VERSION "dbc-export 1 2026.26.6.5"

NS_ :

BS_:

BU_: ADSP APSB CMP DAS GTW OCS1P PTC RCM TCU TCU2 UI UIS VCLEFT

BO_ 979 UI_airbagCutoffStatus: 1 UI
 SG_ UI_airbagCutoffSwState : 0|2@1+ (1,0) [0|3] "" Vector__XXX
 SG_ UI_warningIndicatorStatus : 2|2@1+ (1,0) [0|2] "" Vector__XXX

BO_ 1523 UI_alertLog: 8 UI
 SG_ UI_alertID M : 0|9@1+ (1,0) [0|511] "" Vector__XXX
 SG_ UI_alertState : 15|1@1+ (1,0) [0|1] "" Vector__XXX
 SG_ UI_a006_remoteServiceAlertCode m6 : 16|32@1+ (1,0) [0|4294967295] "" Vector__XXX
 SG_ UI_a009_squashfsDevice m9 : 16|4@1+ (1,0) [0|15] "" Vector__XXX
 SG_ UI_a009_squashfsErrorCount m9 : 24|16@1+ (1,0) [0|65535] "" Vector__XXX
 SG_ UI_a034_BackupCamera m34 : 16|1@1+ (1,0) [0|1] "" Vector__XXX
 SG_ UI_a034_Tuner m34 : 17|1@1+ (1,0) [0|1] "" Vector__XXX
 SG_ UI_a034_Bluetooth m34 : 18|1@1+ (1,0) [0|1] "" Vector__XXX
 SG_ UI_a034_WiFi m34 : 19|1@1+ (1,0) [0|1] "" Vector__XXX
 SG_ UI_a034_Cellular m34 : 20|1@1+ (1,0) [0|1] "" Vector__XXX
 SG_ UI_a034_TouchScreen m34 : 21|1@1+ (1,0) [0|1] "" Vector__XXX
 SG_ UI_a034_Display m34 : 22|1@1+ (1,0) [0|1] "" Vector__XXX
 SG_ UI_a034_Audio m34 : 23|1@1+ (1,0) [0|1] "" Vector__XXX
 SG_ UI_a034_FatalWakeup m34 : 24|1@1+ (1,0) [0|1] "" Vector__XXX
 SG_ UI_a034_UnknownWakeupError m34 : 25|1@1+ (1,0) [0|1] "" Vector__XXX
 SG_ UI_a036_audioWatchdogReason m36 : 16|8@1+ (1,0) [0|255] "" Vector__XXX
 SG_ UI_a045_ManualECallDisabled m45 : 16|1@1+ (1,0) [0|1] "" Vector__XXX
 SG_ UI_a045_ManualECallButtonDisconn m45 : 17|1@1+ (1,0) [0|1] "" Vector__XXX
 SG_ UI_a045_CellAntenna m45 : 18|1@1+ (1,0) [0|1] "" Vector__XXX
 SG_ UI_a045_GPSAntenna m45 : 19|1@1+ (1,0) [0|1] "" Vector__XXX
 SG_ UI_a045_ECallSpeaker m45 : 20|1@1+ (1,0) [0|1] "" Vector__XXX
 SG_ UI_a045_ECallMic m45 : 21|1@1+ (1,0) [0|1] "" Vector__XXX
 SG_ UI_a045_SIMTest m45 : 22|1@1+ (1,0) [0|1] "" Vector__XXX
 SG_ UI_a045_ENSTest m45 : 23|1@1+ (1,0) [0|1] "" Vector__XXX
 SG_ UI_a045_CellularTest m45 : 24|1@1+ (1,0) [0|1] "" Vector__XXX
 SG_ UI_a045_ModemFirmwareTest m45 : 25|1@1+ (1,0) [0|1] "" Vector__XXX
 SG_ UI_a052_kernelPanicSignature m52 : 16|32@1+ (1,0) [0|4294967295] "" Vector__XXX
 SG_ UI_a065_wifiRecoveryReason m65 : 16|8@1+ (1,0) [0|255] "" Vector__XXX
 SG_ UI_a066_ProcessId m66 : 16|8@1+ (1,0) [0|255] "" Vector__XXX
 SG_ UI_a066_RingBlitter m66 : 24|1@1+ (1,0) [0|1] "" Vector__XXX
 SG_ UI_a066_RingBSD m66 : 25|1@1+ (1,0) [0|1] "" Vector__XXX
 SG_ UI_a066_RingRender m66 : 26|1@1+ (1,0) [0|1] "" Vector__XXX
 SG_ UI_a066_RingVideoEnhancement m66 : 27|1@1+ (1,0) [0|1] "" Vector__XXX
 SG_ UI_a066_EnginesHung m66 : 28|1@1+ (1,0) [0|1] "" Vector__XXX
 SG_ UI_a066_EnginesWedged m66 : 29|1@1+ (1,0) [0|1] "" Vector__XXX
 SG_ UI_a066_RecoveryFailed m66 : 30|1@1+ (1,0) [0|1] "" Vector__XXX
 SG_ UI_a066_FlipDoneTimedOut m66 : 31|1@1+ (1,0) [0|1] "" Vector__XXX
 SG_ UI_a066_TimedoutSoftRecovered m66 : 32|1@1+ (1,0) [0|1] "" Vector__XXX
 SG_ UI_a087_BmpResetType m87 : 16|3@1+ (1,0) [0|7] "" Vector__XXX
 SG_ UI_a096_PipelineId m96 : 16|8@1+ (1,0) [0|255] "" Vector__XXX
 SG_ UI_a096_UdpTimeout m96 : 24|1@1+ (1,0) [0|1] "" Vector__XXX
 SG_ UI_a096_PipelineWarning m96 : 25|1@1+ (1,0) [0|1] "" Vector__XXX
 SG_ UI_a096_PipelineError m96 : 26|1@1+ (1,0) [0|1] "" Vector__XXX
 SG_ UI_a096_UnexpectedExit m96 : 27|1@1+ (1,0) [0|1] "" Vector__XXX
 SG_ UI_a096_PipelineOverrun m96 : 28|1@1+ (1,0) [0|1] "" Vector__XXX
 SG_ UI_a096_MissingXWindow m96 : 29|1@1+ (1,0) [0|1] "" Vector__XXX
 SG_ UI_a099_emmcStatusRegister m99 : 16|32@1+ (1,0) [0|4294967295] "" Vector__XXX
 SG_ UI_a100_emmcFTLCounter m100 : 16|32@1+ (1,0) [0|4294967295] "" Vector__XXX
 SG_ UI_a131_DisplayPortFailureType m131 : 16|1@1+ (1,0) [0|1] "" Vector__XXX
 SG_ UI_a147_whichASIL m147 : 16|1@1+ (1,0) [0|1] "" Vector__XXX
 SG_ UI_a147_errorCode m147 : 24|8@1+ (1,0) [0|255] "" Vector__XXX
 SG_ UI_a148_sleepType m148 : 16|3@1+ (1,0) [0|7] "" Vector__XXX
 SG_ UI_a148_lastFailedDev m148 : 24|32@1+ (1,0) [0|4294967295] "" Vector__XXX
 SG_ UI_a148_lastFailedPmSuspendDev m148 : 56|5@1+ (1,0) [0|31] "" Vector__XXX
 SG_ UI_a149_displayType m149 : 16|8@1+ (1,0) [0|255] "" Vector__XXX
 SG_ UI_a149_displaySeat m149 : 24|4@1+ (1,0) [0|15] "" Vector__XXX
 SG_ UI_a149_errorCode m149 : 32|32@1+ (1,0) [0|4294967295] "" Vector__XXX
 SG_ UI_a151_cpuAmbientDeltaTemp m151 : 16|16@1+ (1,0) [0|65535] "" Vector__XXX
 SG_ UI_a151_socThermalResistance m151 : 32|16@1+ (1,0) [0|65535] "" Vector__XXX
 SG_ UI_a153_processName m153 : 16|8@1+ (1,0) [0|255] "" Vector__XXX
 SG_ UI_a153_restartReason m153 : 24|8@1+ (1,0) [0|255] "" Vector__XXX
 SG_ UI_a158_UsbDeviceMountErrorCode m158 : 16|32@1+ (1,0) [0|4294967295] "" Vector__XXX
 SG_ UI_a160_WatchdogStarving m160 : 16|1@1+ (1,0) [0|1] "" Vector__XXX
 SG_ UI_a160_MemoryPressureCritical m160 : 17|1@1+ (1,0) [0|1] "" Vector__XXX
 SG_ UI_a160_MemoryUsageCritical m160 : 18|1@1+ (1,0) [0|1] "" Vector__XXX
 SG_ UI_a160_SlabUsageCritical m160 : 19|1@1+ (1,0) [0|1] "" Vector__XXX
 SG_ UI_a165_fsCorruptedDevice m165 : 16|4@1+ (1,0) [0|15] "" Vector__XXX
 SG_ UI_a166_fsErrorDevice m166 : 16|4@1+ (1,0) [0|15] "" Vector__XXX
 SG_ UI_a167_processId m167 : 16|5@1+ (1,0) [0|31] "" Vector__XXX
 SG_ UI_a173_errorCode m173 : 16|2@1+ (1,0) [0|3] "" Vector__XXX
 SG_ UI_a173_hookIndex m173 : 18|4@1+ (1,0) [0|15] "" Vector__XXX
 SG_ UI_a173_lastFailedPmSuspendDev m173 : 24|5@1+ (1,0) [0|31] "" Vector__XXX
 SG_ UI_a176_PrimaryAntenna m176 : 16|3@1+ (1,0) [0|7] "" Vector__XXX
 SG_ UI_a176_SecondaryAntenna m176 : 19|3@1+ (1,0) [0|7] "" Vector__XXX
 SG_ UI_a176_TertiaryAntenna m176 : 24|3@1+ (1,0) [0|7] "" Vector__XXX
 SG_ UI_a177_errorCode m177 : 16|5@1+ (1,0) [0|31] "" Vector__XXX
 SG_ UI_a177_errorSource m177 : 24|6@1+ (1,0) [0|63] "" Vector__XXX
 SG_ UI_a178_irqNumber m178 : 16|16@1+ (1,0) [0|65535] "" Vector__XXX
 SG_ UI_a178_irqSourceId m178 : 32|32@1+ (1,0) [0|4294967295] "" Vector__XXX
 SG_ UI_a192_AudioRebootState m192 : 16|4@1+ (1,0) [0|15] "" Vector__XXX
 SG_ UI_a204_ModemSleepFailureReason m204 : 16|3@1+ (1,0) [0|7] "" Vector__XXX
 SG_ UI_a208_mqttClientDisconnectReas m208 : 16|8@1+ (1,0) [0|255] "" Vector__XXX
 SG_ UI_a214_errorCode m214 : 16|8@1+ (1,0) [0|255] "" Vector__XXX
 SG_ UI_a214_lastFailedDev m214 : 24|32@1+ (1,0) [0|4294967295] "" Vector__XXX
 SG_ UI_a214_lastFailedPmSuspendDev m214 : 56|5@1+ (1,0) [0|31] "" Vector__XXX
 SG_ UI_a216_circuitProblem m216 : 16|8@1+ (1,0) [0|255] "" Vector__XXX
 SG_ UI_a216_circuitNode m216 : 24|8@1+ (1,0) [0|255] "" Vector__XXX
 SG_ UI_a217_cgroupName m217 : 16|5@1+ (1,0) [0|31] "" Vector__XXX
 SG_ UI_a220_errorCode m220 : 16|4@1+ (1,0) [0|15] "" Vector__XXX
 SG_ UI_a221_errorCode m221 : 16|4@1+ (1,0) [0|15] "" Vector__XXX
 SG_ UI_a221_networkErrorCode m221 : 20|9@1+ (1,0) [0|511] "" Vector__XXX
 SG_ UI_a221_serverErrorCode m221 : 32|16@1+ (1,0) [0|65535] "" Vector__XXX
 SG_ UI_a222_errorCode m222 : 16|4@1+ (1,0) [0|15] "" Vector__XXX
 SG_ UI_a223_database m223 : 16|6@1+ (1,0) [0|63] "" Vector__XXX
 SG_ UI_a226_count m226 : 16|16@1+ (1,0) [0|65535] "" Vector__XXX
 SG_ UI_a229_errorCode m229 : 16|8@1+ (1,0) [0|255] "" Vector__XXX
 SG_ UI_a231_sleepType m231 : 16|3@1+ (1,0) [0|7] "" Vector__XXX
 SG_ UI_a232_processExited m232 : 16|8@1+ (1,0) [0|255] "" Vector__XXX
 SG_ UI_a232_processSignal m232 : 24|8@1+ (1,0) [0|255] "" Vector__XXX
 SG_ UI_a240_ethErrorType m240 : 16|8@1+ (1,0) [0|255] "" Vector__XXX
 SG_ UI_a241_errorCode m241 : 16|8@1+ (1,0) [0|255] "" Vector__XXX
 SG_ UI_a242_CenterDispFaultInjected m242 : 16|1@1+ (1,0) [0|1] "" Vector__XXX
 SG_ UI_a242_ConnectivityFaultInjecte m242 : 17|1@1+ (1,0) [0|1] "" Vector__XXX
 SG_ UI_a242_ConnectivityHWFaultInjec m242 : 18|1@1+ (1,0) [0|1] "" Vector__XXX
 SG_ UI_a242_QtCarFaultInjected m242 : 19|1@1+ (1,0) [0|1] "" Vector__XXX
 SG_ UI_a242_RearDispFaultInjected m242 : 20|1@1+ (1,0) [0|1] "" Vector__XXX
 SG_ UI_a242_QtCarRearFaultInjected m242 : 21|1@1+ (1,0) [0|1] "" Vector__XXX
 SG_ UI_a242_DASServerFaultInjected m242 : 22|1@1+ (1,0) [0|1] "" Vector__XXX
 SG_ UI_a242_CenterDispStatusFaultInj m242 : 23|1@1+ (1,0) [0|1] "" Vector__XXX
 SG_ UI_a242_FaultCode m242 : 24|16@1+ (1,0) [0|65535] "" Vector__XXX
 SG_ UI_a247_displayType m247 : 16|8@1+ (1,0) [0|255] "" Vector__XXX
 SG_ UI_a247_displaySeat m247 : 24|4@1+ (1,0) [0|15] "" Vector__XXX
 SG_ UI_a253_correctionCode m253 : 16|48@1+ (1,0) [0|281474976710655] "" Vector__XXX
 SG_ UI_a257_ModemRebootReason m257 : 16|3@1+ (1,0) [0|7] "" Vector__XXX
 SG_ UI_a257_ModemRebootEthPresent m257 : 19|1@1+ (1,0) [0|1] "" Vector__XXX
 SG_ UI_a261_bluetoothStackPanicReaso m261 : 16|6@1+ (1,0) [0|63] "" Vector__XXX
 SG_ UI_a263_hermesUploadFailure m263 : 16|1@1+ (1,0) [0|1] "" Vector__XXX
 SG_ UI_a263_udsUploadFailure m263 : 17|1@1+ (1,0) [0|1] "" Vector__XXX
 SG_ UI_a274_hintCardType m274 : 16|4@1+ (1,0) [0|15] "" Vector__XXX
 SG_ UI_a274_hintCardDismissOutcome m274 : 20|3@1+ (1,0) [0|7] "" Vector__XXX

BO_ 291 UI_alertMatrix1: 8 UI
 SG_ UI_a001_DriverDoorOpen : 0|1@1+ (1,0) [0|1] "" Vector__XXX
 SG_ UI_a002_DoorOpen : 1|1@1+ (1,0) [0|1] "" Vector__XXX
 SG_ UI_a003_TrunkOpen : 2|1@1+ (1,0) [0|1] "" Vector__XXX
 SG_ UI_a004_FrunkOpen : 3|1@1+ (1,0) [0|1] "" Vector__XXX
 SG_ UI_a005_HeadlightsOnDoorOpen : 4|1@1+ (1,0) [0|1] "" Vector__XXX
 SG_ UI_a006_RemoteServiceAlert : 5|1@1+ (1,0) [0|1] "" Vector__XXX
 SG_ UI_a007_SoftPackConfigMismatch : 6|1@1+ (1,0) [0|1] "" Vector__XXX
 SG_ UI_a008_TouchScreenError : 7|1@1+ (1,0) [0|1] "" Vector__XXX
 SG_ UI_a009_SquashfsError : 8|1@1+ (1,0) [0|1] "" Vector__XXX
 SG_ UI_a010_MapsMissing : 9|1@1+ (1,0) [0|1] "" Vector__XXX
 SG_ UI_a011_IncorrectMap : 10|1@1+ (1,0) [0|1] "" Vector__XXX
 SG_ UI_a012_NotOnPrivateProperty : 11|1@1+ (1,0) [0|1] "" Vector__XXX
 SG_ UI_a013_TPMSHardWarning : 12|1@1+ (1,0) [0|1] "" Vector__XXX
 SG_ UI_a014_TPMSSoftWarning : 13|1@1+ (1,0) [0|1] "" Vector__XXX
 SG_ UI_a015_TPMSOverPressureWarning : 14|1@1+ (1,0) [0|1] "" Vector__XXX
 SG_ UI_a016_TPMSTemperatureWarning : 15|1@1+ (1,0) [0|1] "" Vector__XXX
 SG_ UI_a017_TPMSSystemFault : 16|1@1+ (1,0) [0|1] "" Vector__XXX
 SG_ UI_a018_SlipStartOn : 17|1@1+ (1,0) [0|1] "" Vector__XXX
 SG_ UI_a019_ParkBrakeFault : 18|1@1+ (1,0) [0|1] "" Vector__XXX
 SG_ UI_a020_SteeringReduced : 19|1@1+ (1,0) [0|1] "" Vector__XXX
 SG_ UI_a021_RearSeatbeltUnbuckled : 20|1@1+ (1,0) [0|1] "" Vector__XXX
 SG_ UI_a022_ApeFusesEtc : 21|1@1+ (1,0) [0|1] "" Vector__XXX
 SG_ UI_a023_CellInternetCheckFailed : 22|1@1+ (1,0) [0|1] "" Vector__XXX
 SG_ UI_a024_WifiInternetCheckFailed : 23|1@1+ (1,0) [0|1] "" Vector__XXX
 SG_ UI_a026_ModemResetLoopDetected : 25|1@1+ (1,0) [0|1] "" Vector__XXX
 SG_ UI_a027_AutoSteerMIA : 26|1@1+ (1,0) [0|1] "" Vector__XXX
 SG_ UI_a028_FrontTrunkPopupClosed : 27|1@1+ (1,0) [0|1] "" Vector__XXX
 SG_ UI_a029_ModemMIA : 28|1@1+ (1,0) [0|1] "" Vector__XXX
 SG_ UI_a030_ModemVMCrash : 29|1@1+ (1,0) [0|1] "" Vector__XXX
 SG_ UI_a031_BrakeFluidLow : 30|1@1+ (1,0) [0|1] "" Vector__XXX
 SG_ UI_a032_CellModemRecoveryResets : 31|1@1+ (1,0) [0|1] "" Vector__XXX
 SG_ UI_a033_ApTrialExpired : 32|1@1+ (1,0) [0|1] "" Vector__XXX
 SG_ UI_a034_WakeupProblem : 33|1@1+ (1,0) [0|1] "" Vector__XXX
 SG_ UI_a035_FrunkOpenChime : 34|1@1+ (1,0) [0|1] "" Vector__XXX
 SG_ UI_a036_AudioWatchdog : 35|1@1+ (1,0) [0|1] "" Vector__XXX
 SG_ UI_a037_AudioWatchdogXrunStormEr : 36|1@1+ (1,0) [0|1] "" Vector__XXX
 SG_ UI_a038_AudioWatchdogA2bI2cLocku : 37|1@1+ (1,0) [0|1] "" Vector__XXX
 SG_ UI_a039_AudioA2bNeedRediscovery : 38|1@1+ (1,0) [0|1] "" Vector__XXX
 SG_ UI_a040_HomelinkTransmit : 39|1@1+ (1,0) [0|1] "" Vector__XXX
 SG_ UI_a041_AudioDmesgXrun : 40|1@1+ (1,0) [0|1] "" Vector__XXX
 SG_ UI_a042_AudioDmesgRtThrottling : 41|1@1+ (1,0) [0|1] "" Vector__XXX
 SG_ UI_a043_InvalidMapDataOverride : 42|1@1+ (1,0) [0|1] "" Vector__XXX
 SG_ UI_a044_AudioDmesgDspException : 43|1@1+ (1,0) [0|1] "" Vector__XXX
 SG_ UI_a045_ECallSystemCheckFailed : 44|1@1+ (1,0) [0|1] "" Vector__XXX
 SG_ UI_a046_BackupCameraStreamError : 45|1@1+ (1,0) [0|1] "" Vector__XXX
 SG_ UI_a047_CellRoamingDisallowed : 46|1@1+ (1,0) [0|1] "" Vector__XXX
 SG_ UI_a048_AudioPremiumAmpCheckFail : 47|1@1+ (1,0) [0|1] "" Vector__XXX
 SG_ UI_a049_BrakeShiftRequired : 48|1@1+ (1,0) [0|1] "" Vector__XXX
 SG_ UI_a050_BackupCameraIPUTimeout : 49|1@1+ (1,0) [0|1] "" Vector__XXX
 SG_ UI_a051_BackupCameraFrameTimeout : 50|1@1+ (1,0) [0|1] "" Vector__XXX
 SG_ UI_a052_KernelPanicReported : 51|1@1+ (1,0) [0|1] "" Vector__XXX
 SG_ UI_a053_QtCarExitError : 52|1@1+ (1,0) [0|1] "" Vector__XXX
 SG_ UI_a054_AudioBoostPowerBad : 53|1@1+ (1,0) [0|1] "" Vector__XXX
 SG_ UI_a055_ManualECallDisabled : 54|1@1+ (1,0) [0|1] "" Vector__XXX
 SG_ UI_a056_ManualECallButtonDisconn : 55|1@1+ (1,0) [0|1] "" Vector__XXX
 SG_ UI_a057_CellAntennaDisconnected : 56|1@1+ (1,0) [0|1] "" Vector__XXX
 SG_ UI_a058_GPSAntennaDisconnected : 57|1@1+ (1,0) [0|1] "" Vector__XXX
 SG_ UI_a059_ECallSpeakerDisconnected : 58|1@1+ (1,0) [0|1] "" Vector__XXX
 SG_ UI_a060_ECallMicDisconnected : 59|1@1+ (1,0) [0|1] "" Vector__XXX
 SG_ UI_a061_SIMTestFailed : 60|1@1+ (1,0) [0|1] "" Vector__XXX
 SG_ UI_a062_ENSTestFailed : 61|1@1+ (1,0) [0|1] "" Vector__XXX
 SG_ UI_a063_CellularTestFailed : 62|1@1+ (1,0) [0|1] "" Vector__XXX
 SG_ UI_a064_ModemFirmwareTestFailed : 63|1@1+ (1,0) [0|1] "" Vector__XXX

BO_ 292 UI_alertMatrix2: 8 UI
 SG_ UI_a065_WiFiRecoveryReset : 0|1@1+ (1,0) [0|1] "" Vector__XXX
 SG_ UI_a066_GpuHangDetected : 1|1@1+ (1,0) [0|1] "" Vector__XXX
 SG_ UI_a067_WarnOnI915 : 2|1@1+ (1,0) [0|1] "" Vector__XXX
 SG_ UI_a068_VideoUnexpectedExit : 3|1@1+ (1,0) [0|1] "" Vector__XXX
 SG_ UI_a069_VideoUDPTimeout : 4|1@1+ (1,0) [0|1] "" Vector__XXX
 SG_ UI_a070_VideoPipelineWarning : 5|1@1+ (1,0) [0|1] "" Vector__XXX
 SG_ UI_a071_VideoPipelineError : 6|1@1+ (1,0) [0|1] "" Vector__XXX
 SG_ UI_a072_ECallAnalogMicFailed : 7|1@1+ (1,0) [0|1] "" Vector__XXX
 SG_ UI_a073_ECallDigitalMicFailed : 8|1@1+ (1,0) [0|1] "" Vector__XXX
 SG_ UI_a074_EMMCHangDetected : 9|1@1+ (1,0) [0|1] "" Vector__XXX
 SG_ UI_a075_BackupCameraInitError : 10|1@1+ (1,0) [0|1] "" Vector__XXX
 SG_ UI_a076_NumFalseManualECalls : 11|1@1+ (1,0) [0|1] "" Vector__XXX
 SG_ UI_a077_AudioA2bMicChannelSwap : 12|1@1+ (1,0) [0|1] "" Vector__XXX
 SG_ UI_a078_DashcamUsbDriveUnmountab : 13|1@1+ (1,0) [0|1] "" Vector__XXX
 SG_ UI_a079_DashcamUsbDriveFull : 14|1@1+ (1,0) [0|1] "" Vector__XXX
 SG_ UI_a080_DashcamUsbDriveSlow : 15|1@1+ (1,0) [0|1] "" Vector__XXX
 SG_ UI_a081_CellModemSearchExpired : 16|1@1+ (1,0) [0|1] "" Vector__XXX
 SG_ UI_a082_NumModemRebootStuckInECa : 17|1@1+ (1,0) [0|1] "" Vector__XXX
 SG_ UI_a083_ECallProxyWatchdogTrigge : 18|1@1+ (1,0) [0|1] "" Vector__XXX
 SG_ UI_a084_SerializerError : 19|1@1+ (1,0) [0|1] "" Vector__XXX
 SG_ UI_a085_DeserializerError : 20|1@1+ (1,0) [0|1] "" Vector__XXX
 SG_ UI_a086_TouchEnumerationError : 21|1@1+ (1,0) [0|1] "" Vector__XXX
 SG_ UI_a087_BmpReset : 22|1@1+ (1,0) [0|1] "" Vector__XXX
 SG_ UI_a088_CellRemovableSimMissing : 23|1@1+ (1,0) [0|1] "" Vector__XXX
 SG_ UI_a089_RadioReset : 24|1@1+ (1,0) [0|1] "" Vector__XXX
 SG_ UI_a090_RadioPingFailError : 25|1@1+ (1,0) [0|1] "" Vector__XXX
 SG_ UI_a091_VehicleLinkStall : 26|1@1+ (1,0) [0|1] "" Vector__XXX
 SG_ UI_a092_updateStarted : 27|1@1+ (1,0) [0|1] "" Vector__XXX
 SG_ UI_a093_updateEnded : 28|1@1+ (1,0) [0|1] "" Vector__XXX
 SG_ UI_a094_ModemPowerOnFailure : 29|1@1+ (1,0) [0|1] "" Vector__XXX
 SG_ UI_a095_CidStorageRunningLow : 30|1@1+ (1,0) [0|1] "" Vector__XXX
 SG_ UI_a096_VideodPipelineIssueDetec : 31|1@1+ (1,0) [0|1] "" Vector__XXX
 SG_ UI_a097_AudiodRestarted : 32|1@1+ (1,0) [0|1] "" Vector__XXX
 SG_ UI_a098_DiskCheckFailure : 33|1@1+ (1,0) [0|1] "" Vector__XXX
 SG_ UI_a099_eMMCStatusError : 34|1@1+ (1,0) [0|1] "" Vector__XXX
 SG_ UI_a100_eMMCFTLError : 35|1@1+ (1,0) [0|1] "" Vector__XXX
 SG_ UI_a101_wifiStackProblem : 36|1@1+ (1,0) [0|1] "" Vector__XXX
 SG_ UI_a102_A2bDiscoveryFailed : 37|1@1+ (1,0) [0|1] "" Vector__XXX
 SG_ UI_a103_UsbHubNotEnumerating : 38|1@1+ (1,0) [0|1] "" Vector__XXX
 SG_ UI_a104_DashcamUsbDriveMissing : 39|1@1+ (1,0) [0|1] "" Vector__XXX
 SG_ UI_a105_firmwareReinstallRequest : 40|1@1+ (1,0) [0|1] "" Vector__XXX
 SG_ UI_a106_rebootBackstopTriggered : 41|1@1+ (1,0) [0|1] "" Vector__XXX
 SG_ UI_a107_DashcamUsbDriveTooBigFor : 42|1@1+ (1,0) [0|1] "" Vector__XXX
 SG_ UI_a108_DashcamUsbDriveGettingFu : 43|1@1+ (1,0) [0|1] "" Vector__XXX
 SG_ UI_a109_DashcamUsbDriveTooSmall : 44|1@1+ (1,0) [0|1] "" Vector__XXX
 SG_ UI_a110_DashcamUsbDriveCorrupt : 45|1@1+ (1,0) [0|1] "" Vector__XXX
 SG_ UI_a111_DashcamUsbDriveNotSuperS : 46|1@1+ (1,0) [0|1] "" Vector__XXX
 SG_ UI_a112_badUSBDevice : 47|1@1+ (1,0) [0|1] "" Vector__XXX
 SG_ UI_a113_DashcamHasOnboardSentryC : 48|1@1+ (1,0) [0|1] "" Vector__XXX
 SG_ UI_a114_drivingVisualizationDegr : 49|1@1+ (1,0) [0|1] "" Vector__XXX
 SG_ UI_a115_IrisEDLMode : 50|1@1+ (1,0) [0|1] "" Vector__XXX
 SG_ UI_a116_UncorrectableMemoryError : 51|1@1+ (1,0) [0|1] "" Vector__XXX
 SG_ UI_a117_VehicleSelfTestRunning : 52|1@1+ (1,0) [0|1] "" Vector__XXX
 SG_ UI_a118_NVMeReset : 53|1@1+ (1,0) [0|1] "" Vector__XXX
 SG_ UI_a119_nvmeBlockDeviceMissing : 54|1@1+ (1,0) [0|1] "" Vector__XXX
 SG_ UI_a120_nvmePCIeLinkErrorDetecte : 55|1@1+ (1,0) [0|1] "" Vector__XXX
 SG_ UI_a121_nvmeSmartLogCritical : 56|1@1+ (1,0) [0|1] "" Vector__XXX
 SG_ UI_a122_AMDI2C0LostArbitration : 57|1@1+ (1,0) [0|1] "" Vector__XXX
 SG_ UI_a123_AMDI2C1LostArbitration : 58|1@1+ (1,0) [0|1] "" Vector__XXX
 SG_ UI_a124_AMDI2C0TxRxAborted : 59|1@1+ (1,0) [0|1] "" Vector__XXX
 SG_ UI_a125_AMDI2C1TxRxAborted : 60|1@1+ (1,0) [0|1] "" Vector__XXX
 SG_ UI_a126_UsbErrorDriveCorrupt : 61|1@1+ (1,0) [0|1] "" Vector__XXX
 SG_ UI_a128_dgpuNotDetected : 63|1@1+ (1,0) [0|1] "" Vector__XXX

BO_ 293 UI_alertMatrix3: 8 UI
 SG_ UI_a129_dgpuOperationFailure : 0|1@1+ (1,0) [0|1] "" Vector__XXX
 SG_ UI_a130_QtCarClusterExitError : 1|1@1+ (1,0) [0|1] "" Vector__XXX
 SG_ UI_a131_DisplayPortFailure : 2|1@1+ (1,0) [0|1] "" Vector__XXX
 SG_ UI_a132_AdspWatchdogRecoveryTrig : 3|1@1+ (1,0) [0|1] "" Vector__XXX
 SG_ UI_a133_AdspWatchdogRecoveryFail : 4|1@1+ (1,0) [0|1] "" Vector__XXX
 SG_ UI_a134_DashcamUsbDriveNoMedium : 5|1@1+ (1,0) [0|1] "" Vector__XXX
 SG_ UI_a135_warnRunOverlayExists : 6|1@1+ (1,0) [0|1] "" Vector__XXX
 SG_ UI_a136_warnSettingsConfExists : 7|1@1+ (1,0) [0|1] "" Vector__XXX
 SG_ UI_a137_ServiceShellActiveConnec : 8|1@1+ (1,0) [0|1] "" Vector__XXX
 SG_ UI_a138_applyingConfigChange : 9|1@1+ (1,0) [0|1] "" Vector__XXX
 SG_ UI_a139_postponedConfigChange : 10|1@1+ (1,0) [0|1] "" Vector__XXX
 SG_ UI_a140_NeverSleepActive : 11|1@1+ (1,0) [0|1] "" Vector__XXX
 SG_ UI_a141_falconDoorOpen : 12|1@1+ (1,0) [0|1] "" Vector__XXX
 SG_ UI_a142_CorrectableMemoryError : 13|1@1+ (1,0) [0|1] "" Vector__XXX
 SG_ UI_a143_FPSCrawling : 14|1@1+ (1,0) [0|1] "" Vector__XXX
 SG_ UI_a144_nvmeWarning : 15|1@1+ (1,0) [0|1] "" Vector__XXX
 SG_ UI_a145_nvmeUnsafeShutdown : 16|1@1+ (1,0) [0|1] "" Vector__XXX
 SG_ UI_a146_nvmeNeedsReplacement : 17|1@1+ (1,0) [0|1] "" Vector__XXX
 SG_ UI_a147_ASILGlobalError : 18|1@1+ (1,0) [0|1] "" Vector__XXX
 SG_ UI_a148_SleepFailure : 19|1@1+ (1,0) [0|1] "" Vector__XXX
 SG_ UI_a149_DisplayCheckFailure : 20|1@1+ (1,0) [0|1] "" Vector__XXX
 SG_ UI_a150_infoCPURunningHot : 21|1@1+ (1,0) [0|1] "" Vector__XXX
 SG_ UI_a151_carComputerThermalProble : 22|1@1+ (1,0) [0|1] "" Vector__XXX
 SG_ UI_a152_infoThrottling : 23|1@1+ (1,0) [0|1] "" Vector__XXX
 SG_ UI_a153_serviceRestarted : 24|1@1+ (1,0) [0|1] "" Vector__XXX
 SG_ UI_a154_AudiodBufferError : 25|1@1+ (1,0) [0|1] "" Vector__XXX
 SG_ UI_a155_UsbFrontHubUnavailable : 26|1@1+ (1,0) [0|1] "" Vector__XXX
 SG_ UI_a156_UsbFrontHubInstallMismat : 27|1@1+ (1,0) [0|1] "" Vector__XXX
 SG_ UI_a157_MCUActiveCoolingRequeste : 28|1@1+ (1,0) [0|1] "" Vector__XXX
 SG_ UI_a158_UsbDeviceMountError : 29|1@1+ (1,0) [0|1] "" Vector__XXX
 SG_ UI_a159_AudioHeartbeatFailure : 30|1@1+ (1,0) [0|1] "" Vector__XXX
 SG_ UI_a160_SystemWatchdogFailure : 31|1@1+ (1,0) [0|1] "" Vector__XXX
 SG_ UI_a161_ECallTemporarilyUnavaila : 32|1@1+ (1,0) [0|1] "" Vector__XXX
 SG_ UI_a162_voiceRecClipsUploaded : 33|1@1+ (1,0) [0|1] "" Vector__XXX
 SG_ UI_a163_QtCarVehicleExitError : 34|1@1+ (1,0) [0|1] "" Vector__XXX
 SG_ UI_a164_AudiodConnTimeout : 35|1@1+ (1,0) [0|1] "" Vector__XXX
 SG_ UI_a165_fsCorrupted : 36|1@1+ (1,0) [0|1] "" Vector__XXX
 SG_ UI_a166_fsError : 37|1@1+ (1,0) [0|1] "" Vector__XXX
 SG_ UI_a167_CgroupOverMemKill : 38|1@1+ (1,0) [0|1] "" Vector__XXX
 SG_ UI_a168_dgpuPowerOnSelfTestFailu : 39|1@1+ (1,0) [0|1] "" Vector__XXX
 SG_ UI_a169_SteamLoadShedFailure : 40|1@1+ (1,0) [0|1] "" Vector__XXX
 SG_ UI_a170_AMDdGPULoadShedFailure : 41|1@1+ (1,0) [0|1] "" Vector__XXX
 SG_ UI_a171_GraphicsLoadShedRequeste : 42|1@1+ (1,0) [0|1] "" Vector__XXX
 SG_ UI_a172_GraphicsLoadShedUIFailur : 43|1@1+ (1,0) [0|1] "" Vector__XXX
 SG_ UI_a173_pmSuspendFailure : 44|1@1+ (1,0) [0|1] "" Vector__XXX
 SG_ UI_a174_HistorySaveLoop : 45|1@1+ (1,0) [0|1] "" Vector__XXX
 SG_ UI_a176_CellularAntennaAlert : 47|1@1+ (1,0) [0|1] "" Vector__XXX
 SG_ UI_a177_MediaPlayerFailure : 48|1@1+ (1,0) [0|1] "" Vector__XXX
 SG_ UI_a178_irqDisabled : 49|1@1+ (1,0) [0|1] "" Vector__XXX
 SG_ UI_a180_AudiodInputRestarted : 51|1@1+ (1,0) [0|1] "" Vector__XXX
 SG_ UI_a181_ModemFirmwareVersionMism : 52|1@1+ (1,0) [0|1] "" Vector__XXX
 SG_ UI_a182_VideoPipelineOverrun : 53|1@1+ (1,0) [0|1] "" Vector__XXX
 SG_ UI_a183_DDAWFaulted : 54|1@1+ (1,0) [0|1] "" Vector__XXX
 SG_ UI_a184_ISAFaulted : 55|1@1+ (1,0) [0|1] "" Vector__XXX
 SG_ UI_a185_ELKSDisabled : 56|1@1+ (1,0) [0|1] "" Vector__XXX
 SG_ UI_a186_ELKSUnavailable : 57|1@1+ (1,0) [0|1] "" Vector__XXX
 SG_ UI_a187_TunerFirmwareMismatchedV : 58|1@1+ (1,0) [0|1] "" Vector__XXX
 SG_ UI_a188_TunerFirmwareMismatchedA : 59|1@1+ (1,0) [0|1] "" Vector__XXX
 SG_ UI_a189_TunerWatchdogReset : 60|1@1+ (1,0) [0|1] "" Vector__XXX
 SG_ UI_a190_TunerMIA : 61|1@1+ (1,0) [0|1] "" Vector__XXX
 SG_ UI_a191_TunerUpdateFailed : 62|1@1+ (1,0) [0|1] "" Vector__XXX
 SG_ UI_a192_AudioWatchdogReboot : 63|1@1+ (1,0) [0|1] "" Vector__XXX

BO_ 294 UI_alertMatrix4: 8 UI
 SG_ UI_a193_TcuRNandFwVersionMismatc : 0|1@1+ (1,0) [0|1] "" Vector__XXX
 SG_ UI_a194_AudioweaverRestarted : 1|1@1+ (1,0) [0|1] "" Vector__XXX
 SG_ UI_a195_gtwMfdUdpApiFired : 2|1@1+ (1,0) [0|1] "" Vector__XXX
 SG_ UI_a196_AMDI2C3BusInoperable : 3|1@1+ (1,0) [0|1] "" Vector__XXX
 SG_ UI_a197_AMDI2C1BusInoperable : 4|1@1+ (1,0) [0|1] "" Vector__XXX
 SG_ UI_a198_IncompatibleBTUSBHubHard : 5|1@1+ (1,0) [0|1] "" Vector__XXX
 SG_ UI_a199_HighAPedalDetectedAtColl : 6|1@1+ (1,0) [0|1] "" Vector__XXX
 SG_ UI_a200_UIFirmwareVersionMismatc : 7|1@1+ (1,0) [0|1] "" Vector__XXX
 SG_ UI_a201_rearDisplayDisconnected : 8|1@1+ (1,0) [0|1] "" Vector__XXX
 SG_ UI_a202_sysMemoryIncorrect : 9|1@1+ (1,0) [0|1] "" Vector__XXX
 SG_ UI_a204_ModemSleepFailure : 11|1@1+ (1,0) [0|1] "" Vector__XXX
 SG_ UI_a205_ModemSleepSignalMismatch : 12|1@1+ (1,0) [0|1] "" Vector__XXX
 SG_ UI_a206_ModemMIAAfterWake : 13|1@1+ (1,0) [0|1] "" Vector__XXX
 SG_ UI_a208_mqttClientDisconnected : 15|1@1+ (1,0) [0|1] "" Vector__XXX
 SG_ UI_a209_dataCallDisconnected : 16|1@1+ (1,0) [0|1] "" Vector__XXX
 SG_ UI_a210_CellularCSRegFail : 17|1@1+ (1,0) [0|1] "" Vector__XXX
 SG_ UI_a211_AEBSDisabled : 18|1@1+ (1,0) [0|1] "" Vector__XXX
 SG_ UI_a212_AEBSFaulted : 19|1@1+ (1,0) [0|1] "" Vector__XXX
 SG_ UI_a213_ISADisabled : 20|1@1+ (1,0) [0|1] "" Vector__XXX
 SG_ UI_a214_pmHelperFailure : 21|1@1+ (1,0) [0|1] "" Vector__XXX
 SG_ UI_a215_compositorStallDetected : 22|1@1+ (1,0) [0|1] "" Vector__XXX
 SG_ UI_a216_AudioA2bCircuitProblem : 23|1@1+ (1,0) [0|1] "" Vector__XXX
 SG_ UI_a217_CgroupMemoryPressure : 24|1@1+ (1,0) [0|1] "" Vector__XXX
 SG_ UI_a218_AudiodNoAudioDevices : 25|1@1+ (1,0) [0|1] "" Vector__XXX
 SG_ UI_a219_CompositorWatchdog : 26|1@1+ (1,0) [0|1] "" Vector__XXX
 SG_ UI_a220_MediaBrowseError : 27|1@1+ (1,0) [0|1] "" Vector__XXX
 SG_ UI_a221_NavigationServiceError : 28|1@1+ (1,0) [0|1] "" Vector__XXX
 SG_ UI_a222_QtCarRestart : 29|1@1+ (1,0) [0|1] "" Vector__XXX
 SG_ UI_a223_databaseError : 30|1@1+ (1,0) [0|1] "" Vector__XXX
 SG_ UI_a224_centerDisplayDisconnecte : 31|1@1+ (1,0) [0|1] "" Vector__XXX
 SG_ UI_a225_clusterDisplayDisconnect : 32|1@1+ (1,0) [0|1] "" Vector__XXX
 SG_ UI_a226_largePhoneContactSync : 33|1@1+ (1,0) [0|1] "" Vector__XXX
 SG_ UI_a228_pipewireXrunBurst : 35|1@1+ (1,0) [0|1] "" Vector__XXX
 SG_ UI_a229_SerDesError : 36|1@1+ (1,0) [0|1] "" Vector__XXX
 SG_ UI_a230_ModemSimCardMismatch : 37|1@1+ (1,0) [0|1] "" Vector__XXX
 SG_ UI_a231_SleepCancelled : 38|1@1+ (1,0) [0|1] "" Vector__XXX
 SG_ UI_a232_processExitError : 39|1@1+ (1,0) [0|1] "" Vector__XXX
 SG_ UI_a233_ModemRFFailure : 40|1@1+ (1,0) [0|1] "" Vector__XXX
 SG_ UI_a234_AMDI2C0Timeout : 41|1@1+ (1,0) [0|1] "" Vector__XXX
 SG_ UI_a235_AMDI2C1Timeout : 42|1@1+ (1,0) [0|1] "" Vector__XXX
 SG_ UI_a236_ModemOnResetState : 43|1@1+ (1,0) [0|1] "" Vector__XXX
 SG_ UI_a237_ClipUploadActive : 44|1@1+ (1,0) [0|1] "" Vector__XXX
 SG_ UI_a238_ModemConfigMismatch : 45|1@1+ (1,0) [0|1] "" Vector__XXX
 SG_ UI_a240_ethError : 47|1@1+ (1,0) [0|1] "" Vector__XXX
 SG_ UI_a241_AxCPError : 48|1@1+ (1,0) [0|1] "" Vector__XXX
 SG_ UI_a242_uiHealthFaultInjectionAc : 49|1@1+ (1,0) [0|1] "" Vector__XXX
 SG_ UI_a243_pmDisplayCheckFailure : 50|1@1+ (1,0) [0|1] "" Vector__XXX
 SG_ UI_a244_segfault : 51|1@1+ (1,0) [0|1] "" Vector__XXX
 SG_ UI_a245_taskHung : 52|1@1+ (1,0) [0|1] "" Vector__XXX
 SG_ UI_a246_gpuFenceTimeout : 53|1@1+ (1,0) [0|1] "" Vector__XXX
 SG_ UI_a247_StalklessDisplayBackligh : 54|1@1+ (1,0) [0|1] "" Vector__XXX
 SG_ UI_a252_TPMErrorReceive : 59|1@1+ (1,0) [0|1] "" Vector__XXX
 SG_ UI_a253_maintenanceHistoryRecord : 60|1@1+ (1,0) [0|1] "" Vector__XXX
 SG_ UI_a254_appCertificateExpired : 61|1@1+ (1,0) [0|1] "" Vector__XXX
 SG_ UI_a255_apbCertificateExpired : 62|1@1+ (1,0) [0|1] "" Vector__XXX
 SG_ UI_a256_sapFailedToEnable : 63|1@1+ (1,0) [0|1] "" Vector__XXX

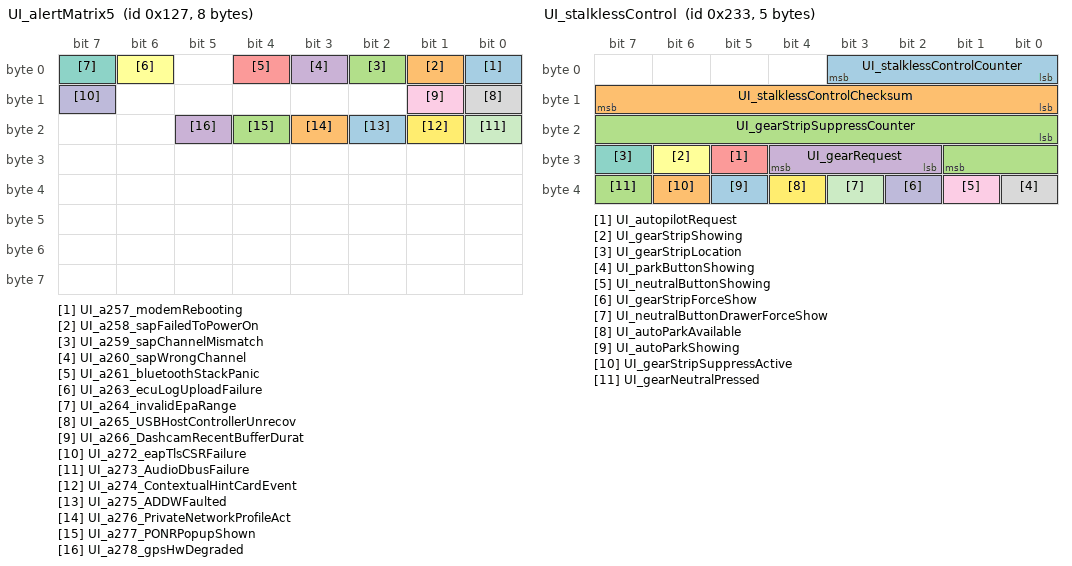
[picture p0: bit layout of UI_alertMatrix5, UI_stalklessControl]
BO_ 295 UI_alertMatrix5: 8 UI
 SG_ UI_a257_modemRebooting : 0|1@1+ (1,0) [0|1] "" Vector__XXX
 SG_ UI_a258_sapFailedToPowerOn : 1|1@1+ (1,0) [0|1] "" Vector__XXX
 SG_ UI_a259_sapChannelMismatch : 2|1@1+ (1,0) [0|1] "" Vector__XXX
 SG_ UI_a260_sapWrongChannel : 3|1@1+ (1,0) [0|1] "" Vector__XXX
 SG_ UI_a261_bluetoothStackPanic : 4|1@1+ (1,0) [0|1] "" Vector__XXX
 SG_ UI_a263_ecuLogUploadFailure : 6|1@1+ (1,0) [0|1] "" Vector__XXX
 SG_ UI_a264_invalidEpaRange : 7|1@1+ (1,0) [0|1] "" Vector__XXX
 SG_ UI_a265_USBHostControllerUnrecov : 8|1@1+ (1,0) [0|1] "" Vector__XXX
 SG_ UI_a266_DashcamRecentBufferDurat : 9|1@1+ (1,0) [0|1] "" Vector__XXX
 SG_ UI_a272_eapTlsCSRFailure : 15|1@1+ (1,0) [0|1] "" Vector__XXX
 SG_ UI_a273_AudioDbusFailure : 16|1@1+ (1,0) [0|1] "" Vector__XXX
 SG_ UI_a274_ContextualHintCardEvent : 17|1@1+ (1,0) [0|1] "" Vector__XXX
 SG_ UI_a275_ADDWFaulted : 18|1@1+ (1,0) [0|1] "" Vector__XXX
 SG_ UI_a276_PrivateNetworkProfileAct : 19|1@1+ (1,0) [0|1] "" Vector__XXX
 SG_ UI_a277_PONRPopupShown : 20|1@1+ (1,0) [0|1] "" Vector__XXX
 SG_ UI_a278_gpsHwDegraded : 21|1@1+ (1,0) [0|1] "" Vector__XXX

BO_ 1279 UI_energyConsumptionInfo: 8 UI
 SG_ UI_energyConsumptionInfoIndex M : 0|5@1+ (1,0) [0|31] "" Vector__XXX
 SG_ UI_energyLossTotal_epa m0 : 16|16@1- (1,0) [-32768|32767] "Wh" Vector__XXX
 SG_ UI_energyLossDriving_epa m0 : 32|16@1- (1,0) [-32768|32767] "Wh" Vector__XXX
 SG_ UI_energyLossClimate_epa m0 : 48|16@1- (1,0) [-32768|32767] "Wh" Vector__XXX
 SG_ UI_energyLossBattCond_epa m1 : 16|16@1- (1,0) [-32768|32767] "Wh" Vector__XXX
 SG_ UI_energyLossElevation_epa m1 : 32|16@1- (1,0) [-32768|32767] "Wh" Vector__XXX
 SG_ UI_energyLossAcc_epa m1 : 48|16@1- (1,0) [-32768|32767] "Wh" Vector__XXX
 SG_ UI_energyLossTotalSinceCharge_ep m2 : 16|16@1- (1,0) [-32768|32767] "Wh" Vector__XXX
 SG_ UI_energyLossDrivingSinceCharge_ m2 : 32|16@1- (1,0) [-32768|32767] "Wh" Vector__XXX
 SG_ UI_energyLossClimateSinceCharge_ m2 : 48|16@1- (1,0) [-32768|32767] "Wh" Vector__XXX
 SG_ UI_energyLossBattCondSinceCharge m3 : 16|16@1- (1,0) [-32768|32767] "Wh" Vector__XXX
 SG_ UI_energyLossElevationSinceCharg m3 : 32|16@1- (1,0) [-32768|32767] "Wh" Vector__XXX
 SG_ UI_energyLossAccSinceCharge_epa m3 : 48|16@1- (1,0) [-32768|32767] "Wh" Vector__XXX
 SG_ UI_energyLossTotalSinceTripStart m4 : 16|16@1- (1,0) [-32768|32767] "Wh" Vector__XXX
 SG_ UI_energyLossDrivingSinceTripSta m4 : 32|16@1- (1,0) [-32768|32767] "Wh" Vector__XXX
 SG_ UI_energyLossClimateSinceTripSta m4 : 48|16@1- (1,0) [-32768|32767] "Wh" Vector__XXX
 SG_ UI_energyLossBattCondSinceTripSt m5 : 16|16@1- (1,0) [-32768|32767] "Wh" Vector__XXX
 SG_ UI_energyLossElevationSinceTripS m5 : 32|16@1- (1,0) [-32768|32767] "Wh" Vector__XXX
 SG_ UI_energyLossAccSinceTripStart m5 : 48|16@1- (1,0) [-32768|32767] "Wh" Vector__XXX
 SG_ UI_energyDeltaTotal_epa m6 : 16|16@1- (1,0) [-32768|32767] "Wh" Vector__XXX
 SG_ UI_energyDeltaDriving_epa m6 : 32|16@1- (1,0) [-32768|32767] "Wh" Vector__XXX
 SG_ UI_energyDeltaClimate_epa m6 : 48|16@1- (1,0) [-32768|32767] "Wh" Vector__XXX
 SG_ UI_energyDeltaBattCond_epa m7 : 16|16@1- (1,0) [-32768|32767] "Wh" Vector__XXX
 SG_ UI_energyDeltaElevation_epa m7 : 32|16@1- (1,0) [-32768|32767] "Wh" Vector__XXX
 SG_ UI_energyDeltaAcc_epa m7 : 48|16@1- (1,0) [-32768|32767] "Wh" Vector__XXX
 SG_ UI_uiDeltaOffsetTotal_epa m8 : 16|16@1- (1,0) [-32768|32767] "Wh" Vector__XXX
 SG_ UI_uiDeltaOffsetDriving_epa m8 : 32|16@1- (1,0) [-32768|32767] "Wh" Vector__XXX
 SG_ UI_uiDeltaOffsetClimate_epa m8 : 48|16@1- (1,0) [-32768|32767] "Wh" Vector__XXX
 SG_ UI_uiDeltaOffsetBattCond_epa m9 : 16|16@1- (1,0) [-32768|32767] "Wh" Vector__XXX
 SG_ UI_uiDeltaOffsetElevation_epa m9 : 32|16@1- (1,0) [-32768|32767] "Wh" Vector__XXX
 SG_ UI_uiDeltaOffsetAcc_epa m9 : 48|16@1- (1,0) [-32768|32767] "Wh" Vector__XXX
 SG_ UI_rawToUiEnergyRatio_epa m10 : 8|8@1+ (0.01,0) [0|2.55] "-" Vector__XXX
 SG_ UI_driveDistance_epa m10 : 16|16@1+ (0.01,0) [0|655.35] "miles" Vector__XXX
 SG_ UI_energyDeltaTotalSinceCharge_e m11 : 16|16@1- (1,0) [-32768|32767] "Wh" Vector__XXX
 SG_ UI_energyDeltaDrivingSinceCharge m11 : 32|16@1- (1,0) [-32768|32767] "Wh" Vector__XXX
 SG_ UI_energyDeltaClimateSinceCharge m11 : 48|16@1- (1,0) [-32768|32767] "Wh" Vector__XXX
 SG_ UI_energyDeltaBattCondSinceCharg m12 : 16|16@1- (1,0) [-32768|32767] "Wh" Vector__XXX
 SG_ UI_energyDeltaElevationSinceChar m12 : 32|16@1- (1,0) [-32768|32767] "Wh" Vector__XXX
 SG_ UI_energyDeltaAccSinceCharge_epa m12 : 48|16@1- (1,0) [-32768|32767] "Wh" Vector__XXX
 SG_ UI_uiDeltaOffsetTotalSinceCharge m13 : 16|16@1- (1,0) [-32768|32767] "Wh" Vector__XXX
 SG_ UI_uiDeltaOffsetDrivingSinceChar m13 : 32|16@1- (1,0) [-32768|32767] "Wh" Vector__XXX
 SG_ UI_uiDeltaOffsetClimateSinceChar m13 : 48|16@1- (1,0) [-32768|32767] "Wh" Vector__XXX
 SG_ UI_uiDeltaOffsetBattCondSinceCha m14 : 16|16@1- (1,0) [-32768|32767] "Wh" Vector__XXX
 SG_ UI_uiDeltaOffsetElevationSinceCh m14 : 32|16@1- (1,0) [-32768|32767] "Wh" Vector__XXX
 SG_ UI_uiDeltaOffsetAccSinceCharge_e m14 : 48|16@1- (1,0) [-32768|32767] "Wh" Vector__XXX
 SG_ UI_rawToUiEnergyRatioSinceCharge m15 : 8|8@1+ (0.01,0) [0|2.55] "-" Vector__XXX
 SG_ UI_driveDistanceSinceCharge_epa m15 : 16|16@1+ (0.01,0) [0|655.35] "miles" Vector__XXX
 SG_ UI_energyDeltaTotalSinceTripStar m16 : 16|16@1- (1,0) [-32768|32767] "Wh" Vector__XXX
 SG_ UI_energyDeltaDrivingSinceTripSt m16 : 32|16@1- (1,0) [-32768|32767] "Wh" Vector__XXX
 SG_ UI_energyDeltaClimateSinceTripSt m16 : 48|16@1- (1,0) [-32768|32767] "Wh" Vector__XXX
 SG_ UI_energyDeltaBattCondSinceTripS m17 : 16|16@1- (1,0) [-32768|32767] "Wh" Vector__XXX
 SG_ UI_energyDeltaElevationSinceTrip m17 : 32|16@1- (1,0) [-32768|32767] "Wh" Vector__XXX
 SG_ UI_energyDeltaAccSinceTripStart m17 : 48|16@1- (1,0) [-32768|32767] "Wh" Vector__XXX
 SG_ UI_uiDeltaOffsetTotalSinceTripSt m18 : 16|16@1- (1,0) [-32768|32767] "Wh" Vector__XXX
 SG_ UI_uiDeltaOffsetDrivingSinceTrip m18 : 32|16@1- (1,0) [-32768|32767] "Wh" Vector__XXX
 SG_ UI_uiDeltaOffsetClimateSinceTrip m18 : 48|16@1- (1,0) [-32768|32767] "Wh" Vector__XXX
 SG_ UI_uiDeltaOffsetBattCondSinceTri m19 : 16|16@1- (1,0) [-32768|32767] "Wh" Vector__XXX
 SG_ UI_uiDeltaOffsetElevationSinceTr m19 : 32|16@1- (1,0) [-32768|32767] "Wh" Vector__XXX
 SG_ UI_uiDeltaOffsetAccSinceTripStar m19 : 48|16@1- (1,0) [-32768|32767] "Wh" Vector__XXX
 SG_ UI_rawToUiEnergyRatioSinceTripSt m20 : 8|8@1+ (0.01,0) [0|2.55] "-" Vector__XXX
 SG_ UI_driveDistanceSinceTripStart m20 : 16|16@1+ (0.01,0) [0|655.35] "miles" Vector__XXX
 SG_ UI_voyagerEnabled m21 : 5|1@1+ (1,0) [0|1] "" Vector__XXX
 SG_ UI_trailerMass m21 : 16|16@1+ (1,0) [0|65535] "kg" Vector__XXX

BO_ 993 UI_gearSliderInfo: 8 UI
 SG_ UI_gearSliderInfoIndex M : 0|2@1+ (1,0) [0|3] "" Vector__XXX
 SG_ UI_gearSliderW m0 : 2|14@1+ (1,0) [0|16383] "" Vector__XXX
 SG_ UI_gearSliderH m0 : 16|16@1+ (1,0) [0|65535] "" Vector__XXX
 SG_ UI_gearSliderX m0 : 32|16@1+ (1,0) [0|65535] "" Vector__XXX
 SG_ UI_gearSliderY m0 : 48|16@1+ (1,0) [0|65535] "" Vector__XXX
 SG_ UI_gearParkW m1 : 2|14@1+ (1,0) [0|16383] "" Vector__XXX
 SG_ UI_gearParkH m1 : 16|16@1+ (1,0) [0|65535] "" Vector__XXX
 SG_ UI_gearParkX m1 : 32|16@1+ (1,0) [0|65535] "" Vector__XXX
 SG_ UI_gearParkY m1 : 48|16@1+ (1,0) [0|65535] "" Vector__XXX
 SG_ UI_gearNeutralW m2 : 2|14@1+ (1,0) [0|16383] "" Vector__XXX
 SG_ UI_gearNeutralH m2 : 16|16@1+ (1,0) [0|65535] "" Vector__XXX
 SG_ UI_gearNeutralX m2 : 32|16@1+ (1,0) [0|65535] "" Vector__XXX
 SG_ UI_gearNeutralY m2 : 48|16@1+ (1,0) [0|65535] "" Vector__XXX

BO_ 563 UI_stalklessControl: 5 UI
 SG_ UI_stalklessControlCounter : 0|4@1+ (1,0) [0|15] "" Vector__XXX
 SG_ UI_stalklessControlChecksum : 8|8@1+ (1,0) [0|255] "" Vector__XXX
 SG_ UI_gearStripSuppressCounter : 16|10@1+ (1,0) [0|1023] "" Vector__XXX
 SG_ UI_gearRequest : 26|3@1+ (1,0) [1|7] "" Vector__XXX
 SG_ UI_autopilotRequest : 29|1@1+ (1,0) [0|1] "" Vector__XXX
 SG_ UI_gearStripShowing : 30|1@1+ (1,0) [0|1] "" Vector__XXX
 SG_ UI_gearStripLocation : 31|1@1+ (1,0) [0|1] "" Vector__XXX
 SG_ UI_parkButtonShowing : 32|1@1+ (1,0) [0|1] "" Vector__XXX
 SG_ UI_neutralButtonShowing : 33|1@1+ (1,0) [0|1] "" Vector__XXX
 SG_ UI_gearStripForceShow : 34|1@1+ (1,0) [0|1] "" Vector__XXX
 SG_ UI_neutralButtonDrawerForceShow : 35|1@1+ (1,0) [0|1] "" Vector__XXX
 SG_ UI_autoParkAvailable : 36|1@1+ (1,0) [0|1] "" Vector__XXX
 SG_ UI_autoParkShowing : 37|1@1+ (1,0) [0|1] "" Vector__XXX
 SG_ UI_gearStripSuppressActive : 38|1@1+ (1,0) [0|1] "" Vector__XXX
 SG_ UI_gearNeutralPressed : 39|1@1+ (1,0) [0|1] "" Vector__XXX

BO_ 986 UI_status3: 1 UI
 SG_ UI_wifiRegDomain : 0|7@1+ (1,0) [0|127] "" Vector__XXX
 SG_ UI_wifiTethered : 7|1@1+ (1,0) [0|1] "" Vector__XXX

BO_ 661 UI_systemMonitor: 8 UI
 SG_ UI_systemMonitorIndex M : 0|1@1+ (1,0) [0|1] "" Vector__XXX
 SG_ UI_SystemMemUsage m0 : 8|16@1+ (1,0) [0|65535] "MB" Vector__XXX
 SG_ UI_QtCarMemUsage m0 : 24|16@1+ (1,0) [0|65535] "MB" Vector__XXX
 SG_ UI_QtCarCPUUsage m0 : 40|7@1+ (1,0) [0|127] "%" Vector__XXX
 SG_ UI_emmcStatus m0 : 47|1@1+ (1,0) [0|1] "" Vector__XXX
 SG_ UI_SystemCPUUsage m0 : 48|7@1+ (1,0) [0|127] "%" Vector__XXX
 SG_ UI_HomeHealth m0 : 55|1@1+ (1,0) [0|1] "" Vector__XXX
 SG_ UI_VarHealth m0 : 56|1@1+ (1,0) [0|1] "" Vector__XXX
 SG_ UI_LogHealth m0 : 57|1@1+ (1,0) [0|1] "" Vector__XXX
 SG_ UI_TmpfsHealth m0 : 58|1@1+ (1,0) [0|1] "" Vector__XXX
 SG_ UI_emmcDataWritten m1 : 8|24@1+ (1,0) [0|16777215] "" Vector__XXX
 SG_ UI_emmcTotalErases m1 : 32|16@1+ (1,0) [0|65535] "" Vector__XXX

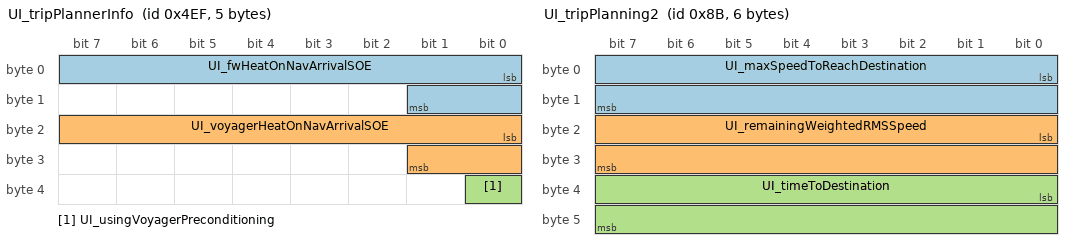
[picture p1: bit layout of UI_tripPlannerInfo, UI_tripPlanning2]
BO_ 1263 UI_tripPlannerInfo: 5 UI
 SG_ UI_fwHeatOnNavArrivalSOE : 0|10@1+ (0.1,0) [0|100] "%" Vector__XXX
 SG_ UI_voyagerHeatOnNavArrivalSOE : 16|10@1+ (0.1,0) [0|100] "%" Vector__XXX
 SG_ UI_usingVoyagerPreconditioning : 32|1@1+ (1,0) [0|1] "" Vector__XXX

BO_ 139 UI_tripPlanning2: 6 UI
 SG_ UI_maxSpeedToReachDestination : 0|16@1+ (0.01,0) [0|655.34] "m/s" Vector__XXX
 SG_ UI_remainingWeightedRMSSpeed : 16|16@1+ (0.01,0) [0|655.34] "m/s" Vector__XXX
 SG_ UI_timeToDestination : 32|16@1+ (1,0) [0|65534] "s" Vector__XXX

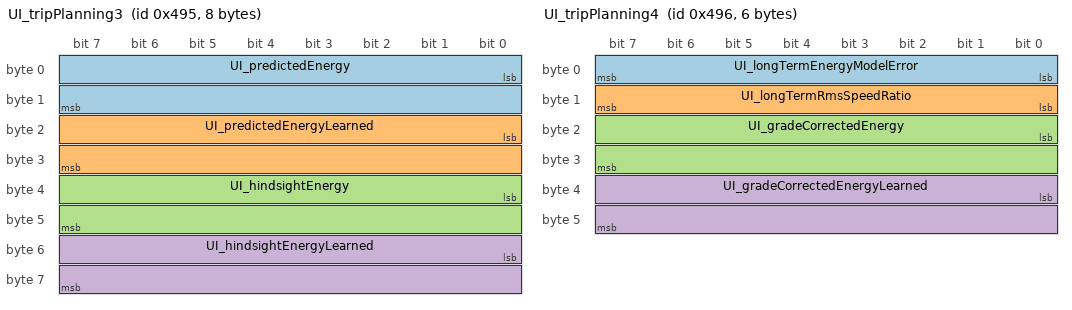
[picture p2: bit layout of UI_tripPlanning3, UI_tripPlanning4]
BO_ 1173 UI_tripPlanning3: 8 UI
 SG_ UI_predictedEnergy : 0|16@1- (0.01,0) [-327.67|327.67] "kWh" Vector__XXX
 SG_ UI_predictedEnergyLearned : 16|16@1- (0.01,0) [-327.68|327.67] "kWh" Vector__XXX
 SG_ UI_hindsightEnergy : 32|16@1- (0.01,0) [-327.67|327.67] "kWh" Vector__XXX
 SG_ UI_hindsightEnergyLearned : 48|16@1- (0.01,0) [-327.68|327.67] "kWh" Vector__XXX

BO_ 1174 UI_tripPlanning4: 6 UI
 SG_ UI_longTermEnergyModelError : 0|8@1- (0.5,0) [-64|63.5] "whpm" Vector__XXX
 SG_ UI_longTermRmsSpeedRatio : 8|8@1+ (0.01,0) [0|2.54] "1" Vector__XXX
 SG_ UI_gradeCorrectedEnergy : 16|16@1- (0.01,0) [-327.68|327.67] "kWh" Vector__XXX
 SG_ UI_gradeCorrectedEnergyLearned : 32|16@1- (0.01,0) [-327.68|327.67] "kWh" Vector__XXX

BO_ 1175 UI_tripPlanning5: 4 UI
 SG_ UI_battPreconditionOnNavTime : 0|16@1+ (1,0) [0|65534] "s" Vector__XXX
 SG_ UI_maxBattPreconditionOnNavTime : 16|16@1+ (1,0) [0|65534] "s" Vector__XXX

BO_ 649 VCLEFT_logging10Hz: 8 VCLEFT
 SG_ VCLEFT_logging10HzIndex M : 0|1@1+ (1,0) [0|1] "" Vector__XXX
 SG_ VCLEFT_hvacBlowerRs m0 : 1|8@1+ (0.25,0) [0|60] "mOhm" Vector__XXX
 SG_ VCLEFT_hvacBlowerIPhase0 m0 : 9|7@1+ (0.4,0) [0|50] "A" Vector__XXX
 SG_ VCLEFT_hvacBlowerIPhase1 m0 : 16|7@1+ (0.4,0) [0|50] "A" Vector__XXX
 SG_ VCLEFT_hvacBlowerIPhase2 m0 : 23|7@1+ (0.4,0) [0|50] "A" Vector__XXX
 SG_ VCLEFT_hvacBlower_IO_CBC_HEAD m0 : 30|4@1+ (1,0) [0|15] "" Vector__XXX
 SG_ VCLEFT_hvacBlower_IO_CBC_TAIL m0 : 34|4@1+ (1,0) [0|15] "" Vector__XXX
 SG_ VCLEFT_hvacBlower_IO_CBC_TAIL_va m0 : 38|1@1+ (1,0) [0|1] "" Vector__XXX
 SG_ VCLEFT_hvacBlower_IO_CBC_Status m0 : 39|1@1+ (1,0) [0|1] "" Vector__XXX
 SG_ VCLEFT_hvacBlower_IO_CBC_numUart m0 : 40|8@1+ (1,0) [0|255] "" Vector__XXX
 SG_ VCLEFT_hvacBlowerCBCEstState m0 : 48|4@1+ (1,0) [0|15] "" Vector__XXX
 SG_ VCLEFT_hvacBlowerCBCCtrlState m0 : 52|3@1+ (1,0) [0|7] "" Vector__XXX
 SG_ VCLEFT_hvacBlowerITerm m0 : 55|7@1+ (0.05,-1.5) [-1.5|4.5] "Nm" Vector__XXX
 SG_ VCLEFT_hvacBlowerSpiError m0 : 62|1@1+ (1,0) [0|1] "" Vector__XXX
 SG_ VCLEFT_hvacBlowerRsOnlineActive m0 : 63|1@1+ (1,0) [0|1] "" Vector__XXX

BO_TX_BU_ 979 : UI;
BO_TX_BU_ 1523 : UI;
BO_TX_BU_ 291 : UI;
BO_TX_BU_ 292 : UI;
BO_TX_BU_ 293 : UI;
BO_TX_BU_ 294 : UI;
BO_TX_BU_ 295 : UI;
BO_TX_BU_ 1279 : UI;
BO_TX_BU_ 993 : UI;
BO_TX_BU_ 563 : UI;
BO_TX_BU_ 986 : UI;
BO_TX_BU_ 661 : UI;
BO_TX_BU_ 1263 : UI;
BO_TX_BU_ 139 : UI;
BO_TX_BU_ 1173 : UI;
BO_TX_BU_ 1174 : UI;
BO_TX_BU_ 1175 : UI;
BO_TX_BU_ 649 : VCLEFT;
CM_ BO_ 979 "Touchscreen user interface computer message: airbag cutoff status";
CM_ SG_ 979 UI_airbagCutoffSwState "Reports the front passenger airbag cutoff switch request; raw 2 = signal not available (SNA)";
CM_ SG_ 979 UI_warningIndicatorStatus "Touchscreen user interface computer: warning indicator status; raw 3 = signal not available (SNA)";
CM_ BO_ 1523 "Touchscreen user interface computer message: alert log";
CM_ SG_ 1523 UI_alertID "Touchscreen user interface computer: alert ID";
CM_ SG_ 1523 UI_alertState "Touchscreen user interface computer: alert state";
CM_ SG_ 1523 UI_a006_remoteServiceAlertCode "Touchscreen user interface computer: a006 remote service alert code";
CM_ SG_ 1523 UI_a009_squashfsDevice "Touchscreen user interface computer: a009 squashfs device";
CM_ SG_ 1523 UI_a009_squashfsErrorCount "Touchscreen user interface computer: a009 squashfs error count";
CM_ SG_ 1523 UI_a034_BackupCamera "Touchscreen user interface computer: a034 backup camera";
CM_ SG_ 1523 UI_a034_Tuner "Touchscreen user interface computer: a034 tuner";
CM_ SG_ 1523 UI_a034_Bluetooth "Touchscreen user interface computer: a034 bluetooth";
CM_ SG_ 1523 UI_a034_WiFi "Touchscreen user interface computer: a034 wi fi";
CM_ SG_ 1523 UI_a034_Cellular "Touchscreen user interface computer: a034 cellular";
CM_ SG_ 1523 UI_a034_TouchScreen "Touchscreen user interface computer: a034 touch screen";
CM_ SG_ 1523 UI_a034_Display "Touchscreen user interface computer: a034 display";
CM_ SG_ 1523 UI_a034_Audio "Touchscreen user interface computer: a034 audio";
CM_ SG_ 1523 UI_a034_FatalWakeup "Touchscreen user interface computer: a034 fatal wakeup";
CM_ SG_ 1523 UI_a034_UnknownWakeupError "Touchscreen user interface computer: a034 unknown wakeup error";
CM_ SG_ 1523 UI_a036_audioWatchdogReason "Touchscreen user interface computer: a036 audio watchdog reason";
CM_ SG_ 1523 UI_a045_ManualECallDisabled "Touchscreen user interface computer: a045 manual e call disabled";
CM_ SG_ 1523 UI_a045_ManualECallButtonDisconn "Touchscreen user interface computer: a045 manual e call button disconnected";
CM_ SG_ 1523 UI_a045_CellAntenna "Touchscreen user interface computer: a045 cell antenna";
CM_ SG_ 1523 UI_a045_GPSAntenna "Touchscreen user interface computer: a045 GPS antenna";
CM_ SG_ 1523 UI_a045_ECallSpeaker "Touchscreen user interface computer: a045 e call speaker";
CM_ SG_ 1523 UI_a045_ECallMic "Touchscreen user interface computer: a045 e call mic";
CM_ SG_ 1523 UI_a045_SIMTest "Touchscreen user interface computer: a045 SIM test";
CM_ SG_ 1523 UI_a045_ENSTest "Touchscreen user interface computer: a045 ENS test";
CM_ SG_ 1523 UI_a045_CellularTest "Touchscreen user interface computer: a045 cellular test";
CM_ SG_ 1523 UI_a045_ModemFirmwareTest "Touchscreen user interface computer: a045 modem firmware test";
CM_ SG_ 1523 UI_a052_kernelPanicSignature "Touchscreen user interface computer: a052 kernel panic signature";
CM_ SG_ 1523 UI_a065_wifiRecoveryReason "Touchscreen user interface computer: a065 wifi recovery reason";
CM_ SG_ 1523 UI_a066_ProcessId "Touchscreen user interface computer: a066 process id";
CM_ SG_ 1523 UI_a066_RingBlitter "Touchscreen user interface computer: a066 ring blitter";
CM_ SG_ 1523 UI_a066_RingBSD "Touchscreen user interface computer: a066 ring BSD";
CM_ SG_ 1523 UI_a066_RingRender "Touchscreen user interface computer: a066 ring render";
CM_ SG_ 1523 UI_a066_RingVideoEnhancement "Touchscreen user interface computer: a066 ring video enhancement";
CM_ SG_ 1523 UI_a066_EnginesHung "Touchscreen user interface computer: a066 engines hung";
CM_ SG_ 1523 UI_a066_EnginesWedged "Touchscreen user interface computer: a066 engines wedged";
CM_ SG_ 1523 UI_a066_RecoveryFailed "Touchscreen user interface computer: a066 recovery failed";
CM_ SG_ 1523 UI_a066_FlipDoneTimedOut "Touchscreen user interface computer: a066 flip done timed out";
CM_ SG_ 1523 UI_a066_TimedoutSoftRecovered "Touchscreen user interface computer: a066 timedout soft recovered";
CM_ SG_ 1523 UI_a087_BmpResetType "Touchscreen user interface computer: a087 bmp reset type";
CM_ SG_ 1523 UI_a096_PipelineId "Touchscreen user interface computer: a096 pipeline id";
CM_ SG_ 1523 UI_a096_UdpTimeout "Touchscreen user interface computer: a096 udp timeout";
CM_ SG_ 1523 UI_a096_PipelineWarning "Touchscreen user interface computer: a096 pipeline warning";
CM_ SG_ 1523 UI_a096_PipelineError "Touchscreen user interface computer: a096 pipeline error";
CM_ SG_ 1523 UI_a096_UnexpectedExit "Touchscreen user interface computer: a096 unexpected exit";
CM_ SG_ 1523 UI_a096_PipelineOverrun "Touchscreen user interface computer: a096 pipeline overrun";
CM_ SG_ 1523 UI_a096_MissingXWindow "Touchscreen user interface computer: a096 missing x window";
CM_ SG_ 1523 UI_a099_emmcStatusRegister "Touchscreen user interface computer: a099 emmc status register";
CM_ SG_ 1523 UI_a100_emmcFTLCounter "Touchscreen user interface computer: a100 emmc FTL counter";
CM_ SG_ 1523 UI_a131_DisplayPortFailureType "Touchscreen user interface computer: a131 display port failure type";
CM_ SG_ 1523 UI_a147_whichASIL "Touchscreen user interface computer: a147 which ASIL";
CM_ SG_ 1523 UI_a147_errorCode "Touchscreen user interface computer: a147 error code";
CM_ SG_ 1523 UI_a148_sleepType "Touchscreen user interface computer: a148 sleep type";
CM_ SG_ 1523 UI_a148_lastFailedDev "Touchscreen user interface computer: a148 last failed dev";
CM_ SG_ 1523 UI_a148_lastFailedPmSuspendDev "Touchscreen user interface computer: a148 last failed pm suspend dev";
CM_ SG_ 1523 UI_a149_displayType "Touchscreen user interface computer: a149 display type";
CM_ SG_ 1523 UI_a149_displaySeat "Touchscreen user interface computer: a149 display seat";
CM_ SG_ 1523 UI_a149_errorCode "Touchscreen user interface computer: a149 error code";
CM_ SG_ 1523 UI_a151_cpuAmbientDeltaTemp "Touchscreen user interface computer: a151 cpu ambient delta temp";
CM_ SG_ 1523 UI_a151_socThermalResistance "Touchscreen user interface computer: a151 soc thermal resistance";
CM_ SG_ 1523 UI_a153_processName "Touchscreen user interface computer: a153 process name";
CM_ SG_ 1523 UI_a153_restartReason "Touchscreen user interface computer: a153 restart reason";
CM_ SG_ 1523 UI_a158_UsbDeviceMountErrorCode "Touchscreen user interface computer: a158 usb device mount error code";
CM_ SG_ 1523 UI_a160_WatchdogStarving "Touchscreen user interface computer: a160 watchdog starving";
CM_ SG_ 1523 UI_a160_MemoryPressureCritical "Touchscreen user interface computer: a160 memory pressure critical";
CM_ SG_ 1523 UI_a160_MemoryUsageCritical "Touchscreen user interface computer: a160 memory usage critical";
CM_ SG_ 1523 UI_a160_SlabUsageCritical "Touchscreen user interface computer: a160 slab usage critical";
CM_ SG_ 1523 UI_a165_fsCorruptedDevice "Touchscreen user interface computer: a165 fs corrupted device";
CM_ SG_ 1523 UI_a166_fsErrorDevice "Touchscreen user interface computer: a166 fs error device";
CM_ SG_ 1523 UI_a167_processId "Touchscreen user interface computer: a167 process id";
CM_ SG_ 1523 UI_a173_errorCode "Touchscreen user interface computer: a173 error code";
CM_ SG_ 1523 UI_a173_hookIndex "Touchscreen user interface computer: a173 hook index";
CM_ SG_ 1523 UI_a173_lastFailedPmSuspendDev "Touchscreen user interface computer: a173 last failed pm suspend dev";
CM_ SG_ 1523 UI_a176_PrimaryAntenna "Touchscreen user interface computer: a176 primary antenna";
CM_ SG_ 1523 UI_a176_SecondaryAntenna "Touchscreen user interface computer: a176 secondary antenna";
CM_ SG_ 1523 UI_a176_TertiaryAntenna "Touchscreen user interface computer: a176 tertiary antenna";
CM_ SG_ 1523 UI_a177_errorCode "Touchscreen user interface computer: a177 error code";
CM_ SG_ 1523 UI_a177_errorSource "Touchscreen user interface computer: a177 error source";
CM_ SG_ 1523 UI_a178_irqNumber "Touchscreen user interface computer: a178 irq number";
CM_ SG_ 1523 UI_a178_irqSourceId "Touchscreen user interface computer: a178 irq source id";
CM_ SG_ 1523 UI_a192_AudioRebootState "Touchscreen user interface computer: a192 audio reboot state";
CM_ SG_ 1523 UI_a204_ModemSleepFailureReason "Touchscreen user interface computer: a204 modem sleep failure reason";
CM_ SG_ 1523 UI_a208_mqttClientDisconnectReas "Touchscreen user interface computer: a208 mqtt client disconnect reason";
CM_ SG_ 1523 UI_a214_errorCode "Touchscreen user interface computer: a214 error code";
CM_ SG_ 1523 UI_a214_lastFailedDev "Touchscreen user interface computer: a214 last failed dev";
CM_ SG_ 1523 UI_a214_lastFailedPmSuspendDev "Touchscreen user interface computer: a214 last failed pm suspend dev";
CM_ SG_ 1523 UI_a216_circuitProblem "Touchscreen user interface computer: a216 circuit problem";
CM_ SG_ 1523 UI_a216_circuitNode "Touchscreen user interface computer: a216 circuit node";
CM_ SG_ 1523 UI_a217_cgroupName "Touchscreen user interface computer: a217 cgroup name";
CM_ SG_ 1523 UI_a220_errorCode "Touchscreen user interface computer: a220 error code";
CM_ SG_ 1523 UI_a221_errorCode "Touchscreen user interface computer: a221 error code";
CM_ SG_ 1523 UI_a221_networkErrorCode "Touchscreen user interface computer: a221 network error code; raw 500 = signal not available (SNA)";
CM_ SG_ 1523 UI_a221_serverErrorCode "Touchscreen user interface computer: a221 server error code";
CM_ SG_ 1523 UI_a222_errorCode "Touchscreen user interface computer: a222 error code";
CM_ SG_ 1523 UI_a223_database "Touchscreen user interface computer: a223 database";
CM_ SG_ 1523 UI_a226_count "Touchscreen user interface computer: a226 count";
CM_ SG_ 1523 UI_a229_errorCode "Touchscreen user interface computer: a229 error code";
CM_ SG_ 1523 UI_a231_sleepType "Touchscreen user interface computer: a231 sleep type";
CM_ SG_ 1523 UI_a232_processExited "Touchscreen user interface computer: a232 process exited";
CM_ SG_ 1523 UI_a232_processSignal "Touchscreen user interface computer: a232 process signal";
CM_ SG_ 1523 UI_a240_ethErrorType "Touchscreen user interface computer: a240 eth error type";
CM_ SG_ 1523 UI_a241_errorCode "Touchscreen user interface computer: a241 error code";
CM_ SG_ 1523 UI_a242_CenterDispFaultInjected "Touchscreen user interface computer: a242 center disp fault injected";
CM_ SG_ 1523 UI_a242_ConnectivityFaultInjecte "Touchscreen user interface computer: a242 connectivity fault injected";
CM_ SG_ 1523 UI_a242_ConnectivityHWFaultInjec "Touchscreen user interface computer: a242 connectivity HW fault injected";
CM_ SG_ 1523 UI_a242_QtCarFaultInjected "Signal reported by Touchscreen user interface computer";
CM_ SG_ 1523 UI_a242_RearDispFaultInjected "Touchscreen user interface computer: a242 rear disp fault injected";
CM_ SG_ 1523 UI_a242_QtCarRearFaultInjected "Signal reported by Touchscreen user interface computer";
CM_ SG_ 1523 UI_a242_DASServerFaultInjected "Touchscreen user interface computer: a242 DAS server fault injected";
CM_ SG_ 1523 UI_a242_CenterDispStatusFaultInj "Touchscreen user interface computer: a242 center disp status fault injected";
CM_ SG_ 1523 UI_a242_FaultCode "Touchscreen user interface computer: a242 fault code";
CM_ SG_ 1523 UI_a247_displayType "Touchscreen user interface computer: a247 display type";
CM_ SG_ 1523 UI_a247_displaySeat "Touchscreen user interface computer: a247 display seat";
CM_ SG_ 1523 UI_a253_correctionCode "Touchscreen user interface computer: a253 correction code";
CM_ SG_ 1523 UI_a257_ModemRebootReason "Touchscreen user interface computer: a257 modem reboot reason";
CM_ SG_ 1523 UI_a257_ModemRebootEthPresent "Touchscreen user interface computer: a257 modem reboot eth present";
CM_ SG_ 1523 UI_a261_bluetoothStackPanicReaso "Touchscreen user interface computer: a261 bluetooth stack panic reason";
CM_ SG_ 1523 UI_a263_hermesUploadFailure "Touchscreen user interface computer: a263 hermes upload failure";
CM_ SG_ 1523 UI_a263_udsUploadFailure "Touchscreen user interface computer: a263 uds upload failure";
CM_ SG_ 1523 UI_a274_hintCardType "Touchscreen user interface computer: a274 hint card type";
CM_ SG_ 1523 UI_a274_hintCardDismissOutcome "Touchscreen user interface computer: a274 hint card dismiss outcome";
CM_ BO_ 291 "Touchscreen user interface computer message: alert matrix1";
CM_ SG_ 291 UI_a001_DriverDoorOpen "Touchscreen user interface computer: a001 driver door open";
CM_ SG_ 291 UI_a002_DoorOpen "Touchscreen user interface computer: a002 door open";
CM_ SG_ 291 UI_a003_TrunkOpen "Touchscreen user interface computer: a003 trunk open";
CM_ SG_ 291 UI_a004_FrunkOpen "Touchscreen user interface computer: a004 frunk open";
CM_ SG_ 291 UI_a005_HeadlightsOnDoorOpen "Touchscreen user interface computer: a005 headlights on door open";
CM_ SG_ 291 UI_a006_RemoteServiceAlert "Touchscreen user interface computer: a006 remote service alert";
CM_ SG_ 291 UI_a007_SoftPackConfigMismatch "Touchscreen user interface computer: a007 soft pack config mismatch";
CM_ SG_ 291 UI_a008_TouchScreenError "Touchscreen user interface computer: a008 touch screen error";
CM_ SG_ 291 UI_a009_SquashfsError "Touchscreen user interface computer: a009 squashfs error";
CM_ SG_ 291 UI_a010_MapsMissing "Touchscreen user interface computer: a010 maps missing";
CM_ SG_ 291 UI_a011_IncorrectMap "Touchscreen user interface computer: a011 incorrect map";
CM_ SG_ 291 UI_a012_NotOnPrivateProperty "Touchscreen user interface computer: a012 not on private property";
CM_ SG_ 291 UI_a013_TPMSHardWarning "Touchscreen user interface computer: a013 TPMS hard warning";
CM_ SG_ 291 UI_a014_TPMSSoftWarning "Touchscreen user interface computer: a014 TPMS soft warning";
CM_ SG_ 291 UI_a015_TPMSOverPressureWarning "Touchscreen user interface computer: a015 TPMS over pressure warning";
CM_ SG_ 291 UI_a016_TPMSTemperatureWarning "Touchscreen user interface computer: a016 TPMS temperature warning";
CM_ SG_ 291 UI_a017_TPMSSystemFault "Touchscreen user interface computer: a017 TPMS system fault";
CM_ SG_ 291 UI_a018_SlipStartOn "Touchscreen user interface computer: a018 slip start on";
CM_ SG_ 291 UI_a019_ParkBrakeFault "Touchscreen user interface computer: a019 park brake fault";
CM_ SG_ 291 UI_a020_SteeringReduced "Touchscreen user interface computer: a020 steering reduced";
CM_ SG_ 291 UI_a021_RearSeatbeltUnbuckled "Touchscreen user interface computer: a021 rear seatbelt unbuckled";
CM_ SG_ 291 UI_a022_ApeFusesEtc "Touchscreen user interface computer: a022 ape fuses etc";
CM_ SG_ 291 UI_a023_CellInternetCheckFailed "Touchscreen user interface computer: a023 cell internet check failed";
CM_ SG_ 291 UI_a024_WifiInternetCheckFailed "Touchscreen user interface computer: a024 wifi internet check failed";
CM_ SG_ 291 UI_a026_ModemResetLoopDetected "Touchscreen user interface computer: a026 modem reset loop detected";
CM_ SG_ 291 UI_a027_AutoSteerMIA "Touchscreen user interface computer: a027 auto steer MIA";
CM_ SG_ 291 UI_a028_FrontTrunkPopupClosed "Touchscreen user interface computer: a028 front trunk popup closed";
CM_ SG_ 291 UI_a029_ModemMIA "Touchscreen user interface computer: a029 modem MIA";
CM_ SG_ 291 UI_a030_ModemVMCrash "Touchscreen user interface computer: a030 modem VM crash";
CM_ SG_ 291 UI_a031_BrakeFluidLow "Touchscreen user interface computer: a031 brake fluid low";
CM_ SG_ 291 UI_a032_CellModemRecoveryResets "Touchscreen user interface computer: a032 cell modem recovery resets";
CM_ SG_ 291 UI_a033_ApTrialExpired "Touchscreen user interface computer: a033 ap trial expired";
CM_ SG_ 291 UI_a034_WakeupProblem "Touchscreen user interface computer: a034 wakeup problem";
CM_ SG_ 291 UI_a035_FrunkOpenChime "Touchscreen user interface computer: a035 frunk open chime";
CM_ SG_ 291 UI_a036_AudioWatchdog "Touchscreen user interface computer: a036 audio watchdog";
CM_ SG_ 291 UI_a037_AudioWatchdogXrunStormEr "Touchscreen user interface computer: a037 audio watchdog xrun storm error";
CM_ SG_ 291 UI_a038_AudioWatchdogA2bI2cLocku "Touchscreen user interface computer: a038 audio watchdog a2b i2c lockup error";
CM_ SG_ 291 UI_a039_AudioA2bNeedRediscovery "Touchscreen user interface computer: a039 audio a2b need rediscovery";
CM_ SG_ 291 UI_a040_HomelinkTransmit "Touchscreen user interface computer: a040 homelink transmit";
CM_ SG_ 291 UI_a041_AudioDmesgXrun "Touchscreen user interface computer: a041 audio dmesg xrun";
CM_ SG_ 291 UI_a042_AudioDmesgRtThrottling "Touchscreen user interface computer: a042 audio dmesg rt throttling";
CM_ SG_ 291 UI_a043_InvalidMapDataOverride "Touchscreen user interface computer: a043 invalid map data override";
CM_ SG_ 291 UI_a044_AudioDmesgDspException "Touchscreen user interface computer: a044 audio dmesg dsp exception";
CM_ SG_ 291 UI_a045_ECallSystemCheckFailed "Touchscreen user interface computer: a045 e call system check failed";
CM_ SG_ 291 UI_a046_BackupCameraStreamError "Touchscreen user interface computer: a046 backup camera stream error";
CM_ SG_ 291 UI_a047_CellRoamingDisallowed "Touchscreen user interface computer: a047 cell roaming disallowed";
CM_ SG_ 291 UI_a048_AudioPremiumAmpCheckFail "Touchscreen user interface computer: a048 audio premium amp check failed";
CM_ SG_ 291 UI_a049_BrakeShiftRequired "Touchscreen user interface computer: a049 brake shift required";
CM_ SG_ 291 UI_a050_BackupCameraIPUTimeout "Touchscreen user interface computer: a050 backup camera IPU timeout";
CM_ SG_ 291 UI_a051_BackupCameraFrameTimeout "Touchscreen user interface computer: a051 backup camera frame timeout";
CM_ SG_ 291 UI_a052_KernelPanicReported "Touchscreen user interface computer: a052 kernel panic reported";
CM_ SG_ 291 UI_a053_QtCarExitError "Signal reported by Touchscreen user interface computer";
CM_ SG_ 291 UI_a054_AudioBoostPowerBad "Touchscreen user interface computer: a054 audio boost power bad";
CM_ SG_ 291 UI_a055_ManualECallDisabled "Touchscreen user interface computer: a055 manual e call disabled";
CM_ SG_ 291 UI_a056_ManualECallButtonDisconn "Touchscreen user interface computer: a056 manual e call button disconnected";
CM_ SG_ 291 UI_a057_CellAntennaDisconnected "Touchscreen user interface computer: a057 cell antenna disconnected";
CM_ SG_ 291 UI_a058_GPSAntennaDisconnected "Touchscreen user interface computer: a058 GPS antenna disconnected";
CM_ SG_ 291 UI_a059_ECallSpeakerDisconnected "Touchscreen user interface computer: a059 e call speaker disconnected";
CM_ SG_ 291 UI_a060_ECallMicDisconnected "Touchscreen user interface computer: a060 e call mic disconnected";
CM_ SG_ 291 UI_a061_SIMTestFailed "Touchscreen user interface computer: a061 SIM test failed";
CM_ SG_ 291 UI_a062_ENSTestFailed "Touchscreen user interface computer: a062 ENS test failed";
CM_ SG_ 291 UI_a063_CellularTestFailed "Touchscreen user interface computer: a063 cellular test failed";
CM_ SG_ 291 UI_a064_ModemFirmwareTestFailed "Touchscreen user interface computer: a064 modem firmware test failed";
CM_ BO_ 292 "Touchscreen user interface computer message: alert matrix2";
CM_ SG_ 292 UI_a065_WiFiRecoveryReset "Touchscreen user interface computer: a065 wi fi recovery reset";
CM_ SG_ 292 UI_a066_GpuHangDetected "Touchscreen user interface computer: a066 gpu hang detected";
CM_ SG_ 292 UI_a067_WarnOnI915 "Touchscreen user interface computer: a067 warn on I915";
CM_ SG_ 292 UI_a068_VideoUnexpectedExit "Touchscreen user interface computer: a068 video unexpected exit";
CM_ SG_ 292 UI_a069_VideoUDPTimeout "Touchscreen user interface computer: a069 video UDP timeout";
CM_ SG_ 292 UI_a070_VideoPipelineWarning "Touchscreen user interface computer: a070 video pipeline warning";
CM_ SG_ 292 UI_a071_VideoPipelineError "Touchscreen user interface computer: a071 video pipeline error";
CM_ SG_ 292 UI_a072_ECallAnalogMicFailed "Touchscreen user interface computer: a072 e call analog mic failed";
CM_ SG_ 292 UI_a073_ECallDigitalMicFailed "Touchscreen user interface computer: a073 e call digital mic failed";
CM_ SG_ 292 UI_a074_EMMCHangDetected "Touchscreen user interface computer: a074 EMMC hang detected";
CM_ SG_ 292 UI_a075_BackupCameraInitError "Touchscreen user interface computer: a075 backup camera init error";
CM_ SG_ 292 UI_a076_NumFalseManualECalls "Touchscreen user interface computer: a076 num false manual e calls";
CM_ SG_ 292 UI_a077_AudioA2bMicChannelSwap "Touchscreen user interface computer: a077 audio a2b mic channel swap";
CM_ SG_ 292 UI_a078_DashcamUsbDriveUnmountab "Touchscreen user interface computer: a078 dashcam usb drive unmountable";
CM_ SG_ 292 UI_a079_DashcamUsbDriveFull "Touchscreen user interface computer: a079 dashcam usb drive full";
CM_ SG_ 292 UI_a080_DashcamUsbDriveSlow "Touchscreen user interface computer: a080 dashcam usb drive slow";
CM_ SG_ 292 UI_a081_CellModemSearchExpired "Touchscreen user interface computer: a081 cell modem search expired";
CM_ SG_ 292 UI_a082_NumModemRebootStuckInECa "Touchscreen user interface computer: a082 num modem reboot stuck in e call";
CM_ SG_ 292 UI_a083_ECallProxyWatchdogTrigge "Touchscreen user interface computer: a083 e call proxy watchdog triggered";
CM_ SG_ 292 UI_a084_SerializerError "Touchscreen user interface computer: a084 serializer error";
CM_ SG_ 292 UI_a085_DeserializerError "Touchscreen user interface computer: a085 deserializer error";
CM_ SG_ 292 UI_a086_TouchEnumerationError "Touchscreen user interface computer: a086 touch enumeration error";
CM_ SG_ 292 UI_a087_BmpReset "Touchscreen user interface computer: a087 bmp reset";
CM_ SG_ 292 UI_a088_CellRemovableSimMissing "Touchscreen user interface computer: a088 cell removable sim missing";
CM_ SG_ 292 UI_a089_RadioReset "Touchscreen user interface computer: a089 radio reset";
CM_ SG_ 292 UI_a090_RadioPingFailError "Touchscreen user interface computer: a090 radio ping fail error";
CM_ SG_ 292 UI_a091_VehicleLinkStall "Touchscreen user interface computer: a091 vehicle link stall";
CM_ SG_ 292 UI_a092_updateStarted "Touchscreen user interface computer: a092 update started";
CM_ SG_ 292 UI_a093_updateEnded "Touchscreen user interface computer: a093 update ended";
CM_ SG_ 292 UI_a094_ModemPowerOnFailure "Touchscreen user interface computer: a094 modem power on failure";
CM_ SG_ 292 UI_a095_CidStorageRunningLow "Touchscreen user interface computer: a095 cid storage running low";
CM_ SG_ 292 UI_a096_VideodPipelineIssueDetec "Touchscreen user interface computer: a096 videod pipeline issue detected";
CM_ SG_ 292 UI_a097_AudiodRestarted "Touchscreen user interface computer: a097 audiod restarted";
CM_ SG_ 292 UI_a098_DiskCheckFailure "Touchscreen user interface computer: a098 disk check failure";
CM_ SG_ 292 UI_a099_eMMCStatusError "Touchscreen user interface computer: a099 e MMC status error";
CM_ SG_ 292 UI_a100_eMMCFTLError "Touchscreen user interface computer: a100 e MMCFTL error";
CM_ SG_ 292 UI_a101_wifiStackProblem "Touchscreen user interface computer: a101 wifi stack problem";
CM_ SG_ 292 UI_a102_A2bDiscoveryFailed "Touchscreen user interface computer: a102 a2b discovery failed";
CM_ SG_ 292 UI_a103_UsbHubNotEnumerating "Touchscreen user interface computer: a103 usb hub not enumerating";
CM_ SG_ 292 UI_a104_DashcamUsbDriveMissing "Touchscreen user interface computer: a104 dashcam usb drive missing";
CM_ SG_ 292 UI_a105_firmwareReinstallRequest "Touchscreen user interface computer: a105 firmware reinstall requested";
CM_ SG_ 292 UI_a106_rebootBackstopTriggered "Touchscreen user interface computer: a106 reboot backstop triggered";
CM_ SG_ 292 UI_a107_DashcamUsbDriveTooBigFor "Touchscreen user interface computer: a107 dashcam usb drive too big for vfat fsck";
CM_ SG_ 292 UI_a108_DashcamUsbDriveGettingFu "Touchscreen user interface computer: a108 dashcam usb drive getting full";
CM_ SG_ 292 UI_a109_DashcamUsbDriveTooSmall "Touchscreen user interface computer: a109 dashcam usb drive too small";
CM_ SG_ 292 UI_a110_DashcamUsbDriveCorrupt "Touchscreen user interface computer: a110 dashcam usb drive corrupt";
CM_ SG_ 292 UI_a111_DashcamUsbDriveNotSuperS "Touchscreen user interface computer: a111 dashcam usb drive not super speed";
CM_ SG_ 292 UI_a112_badUSBDevice "Touchscreen user interface computer: a112 bad USB device";
CM_ SG_ 292 UI_a113_DashcamHasOnboardSentryC "Touchscreen user interface computer: a113 dashcam has onboard sentry clips";
CM_ SG_ 292 UI_a114_drivingVisualizationDegr "Touchscreen user interface computer: a114 driving visualization degraded";
CM_ SG_ 292 UI_a115_IrisEDLMode "Touchscreen user interface computer: a115 iris EDL mode";
CM_ SG_ 292 UI_a116_UncorrectableMemoryError "Touchscreen user interface computer: a116 uncorrectable memory error";
CM_ SG_ 292 UI_a117_VehicleSelfTestRunning "Touchscreen user interface computer: a117 vehicle self test running";
CM_ SG_ 292 UI_a118_NVMeReset "Touchscreen user interface computer: a118 NV me reset";
CM_ SG_ 292 UI_a119_nvmeBlockDeviceMissing "Touchscreen user interface computer: a119 nvme block device missing";
CM_ SG_ 292 UI_a120_nvmePCIeLinkErrorDetecte "Touchscreen user interface computer: a120 nvme PC ie link error detected";
CM_ SG_ 292 UI_a121_nvmeSmartLogCritical "Touchscreen user interface computer: a121 nvme smart log critical";
CM_ SG_ 292 UI_a122_AMDI2C0LostArbitration "Touchscreen user interface computer: a122 AMDI2 C0 lost arbitration";
CM_ SG_ 292 UI_a123_AMDI2C1LostArbitration "Touchscreen user interface computer: a123 AMDI2 C1 lost arbitration";
CM_ SG_ 292 UI_a124_AMDI2C0TxRxAborted "Touchscreen user interface computer: a124 AMDI2 C0 tx rx aborted";
CM_ SG_ 292 UI_a125_AMDI2C1TxRxAborted "Touchscreen user interface computer: a125 AMDI2 C1 tx rx aborted";
CM_ SG_ 292 UI_a126_UsbErrorDriveCorrupt "Touchscreen user interface computer: a126 usb error drive corrupt";
CM_ SG_ 292 UI_a128_dgpuNotDetected "Touchscreen user interface computer: a128 dgpu not detected";
CM_ BO_ 293 "Touchscreen user interface computer message: alert matrix3";
CM_ SG_ 293 UI_a129_dgpuOperationFailure "Touchscreen user interface computer: a129 dgpu operation failure";
CM_ SG_ 293 UI_a130_QtCarClusterExitError "Signal reported by Touchscreen user interface computer";
CM_ SG_ 293 UI_a131_DisplayPortFailure "Touchscreen user interface computer: a131 display port failure";
CM_ SG_ 293 UI_a132_AdspWatchdogRecoveryTrig "Touchscreen user interface computer: a132 adsp watchdog recovery triggered";
CM_ SG_ 293 UI_a133_AdspWatchdogRecoveryFail "Touchscreen user interface computer: a133 adsp watchdog recovery failed";
CM_ SG_ 293 UI_a134_DashcamUsbDriveNoMedium "Touchscreen user interface computer: a134 dashcam usb drive no medium";
CM_ SG_ 293 UI_a135_warnRunOverlayExists "Touchscreen user interface computer: a135 warn run overlay exists";
CM_ SG_ 293 UI_a136_warnSettingsConfExists "Touchscreen user interface computer: a136 warn settings conf exists";
CM_ SG_ 293 UI_a137_ServiceShellActiveConnec "Touchscreen user interface computer: a137 service shell active connection";
CM_ SG_ 293 UI_a138_applyingConfigChange "Touchscreen user interface computer: a138 applying config change";
CM_ SG_ 293 UI_a139_postponedConfigChange "Touchscreen user interface computer: a139 postponed config change";
CM_ SG_ 293 UI_a140_NeverSleepActive "Touchscreen user interface computer: a140 never sleep active";
CM_ SG_ 293 UI_a141_falconDoorOpen "Touchscreen user interface computer: a141 falcon door open";
CM_ SG_ 293 UI_a142_CorrectableMemoryError "Touchscreen user interface computer: a142 correctable memory error";
CM_ SG_ 293 UI_a143_FPSCrawling "Touchscreen user interface computer: a143 FPS crawling";
CM_ SG_ 293 UI_a144_nvmeWarning "Touchscreen user interface computer: a144 nvme warning";
CM_ SG_ 293 UI_a145_nvmeUnsafeShutdown "Touchscreen user interface computer: a145 nvme unsafe shutdown";
CM_ SG_ 293 UI_a146_nvmeNeedsReplacement "Touchscreen user interface computer: a146 nvme needs replacement";
CM_ SG_ 293 UI_a147_ASILGlobalError "Touchscreen user interface computer: a147 ASIL global error";
CM_ SG_ 293 UI_a148_SleepFailure "Touchscreen user interface computer: a148 sleep failure";
CM_ SG_ 293 UI_a149_DisplayCheckFailure "Touchscreen user interface computer: a149 display check failure";
CM_ SG_ 293 UI_a150_infoCPURunningHot "Touchscreen user interface computer: a150 info CPU running hot";
CM_ SG_ 293 UI_a151_carComputerThermalProble "Touchscreen user interface computer: a151 car computer thermal problem";
CM_ SG_ 293 UI_a152_infoThrottling "Touchscreen user interface computer: a152 info throttling";
CM_ SG_ 293 UI_a153_serviceRestarted "Touchscreen user interface computer: a153 service restarted";
CM_ SG_ 293 UI_a154_AudiodBufferError "Touchscreen user interface computer: a154 audiod buffer error";
CM_ SG_ 293 UI_a155_UsbFrontHubUnavailable "Touchscreen user interface computer: a155 usb front hub unavailable";
CM_ SG_ 293 UI_a156_UsbFrontHubInstallMismat "Touchscreen user interface computer: a156 usb front hub install mismatch";
CM_ SG_ 293 UI_a157_MCUActiveCoolingRequeste "Touchscreen user interface computer: a157 MCU active cooling requested";
CM_ SG_ 293 UI_a158_UsbDeviceMountError "Touchscreen user interface computer: a158 usb device mount error";
CM_ SG_ 293 UI_a159_AudioHeartbeatFailure "Touchscreen user interface computer: a159 audio heartbeat failure";
CM_ SG_ 293 UI_a160_SystemWatchdogFailure "Touchscreen user interface computer: a160 system watchdog failure";
CM_ SG_ 293 UI_a161_ECallTemporarilyUnavaila "Touchscreen user interface computer: a161 e call temporarily unavailable";
CM_ SG_ 293 UI_a162_voiceRecClipsUploaded "Touchscreen user interface computer: a162 voice rec clips uploaded";
CM_ SG_ 293 UI_a163_QtCarVehicleExitError "Signal reported by Touchscreen user interface computer";
CM_ SG_ 293 UI_a164_AudiodConnTimeout "Touchscreen user interface computer: a164 audiod conn timeout";
CM_ SG_ 293 UI_a165_fsCorrupted "Touchscreen user interface computer: a165 fs corrupted";
CM_ SG_ 293 UI_a166_fsError "Touchscreen user interface computer: a166 fs error";
CM_ SG_ 293 UI_a167_CgroupOverMemKill "Touchscreen user interface computer: a167 cgroup over mem kill";
CM_ SG_ 293 UI_a168_dgpuPowerOnSelfTestFailu "Touchscreen user interface computer: a168 dgpu power on self test failure";
CM_ SG_ 293 UI_a169_SteamLoadShedFailure "Touchscreen user interface computer: a169 steam load shed failure";
CM_ SG_ 293 UI_a170_AMDdGPULoadShedFailure "Touchscreen user interface computer: a170 AM dd GPU load shed failure";
CM_ SG_ 293 UI_a171_GraphicsLoadShedRequeste "Touchscreen user interface computer: a171 graphics load shed requested";
CM_ SG_ 293 UI_a172_GraphicsLoadShedUIFailur "Touchscreen user interface computer: a172 graphics load shed UI failure";
CM_ SG_ 293 UI_a173_pmSuspendFailure "Touchscreen user interface computer: a173 pm suspend failure";
CM_ SG_ 293 UI_a174_HistorySaveLoop "Touchscreen user interface computer: a174 history save loop";
CM_ SG_ 293 UI_a176_CellularAntennaAlert "Touchscreen user interface computer: a176 cellular antenna alert";
CM_ SG_ 293 UI_a177_MediaPlayerFailure "Touchscreen user interface computer: a177 media player failure";
CM_ SG_ 293 UI_a178_irqDisabled "Touchscreen user interface computer: a178 irq disabled";
CM_ SG_ 293 UI_a180_AudiodInputRestarted "Touchscreen user interface computer: a180 audiod input restarted";
CM_ SG_ 293 UI_a181_ModemFirmwareVersionMism "Touchscreen user interface computer: a181 modem firmware version mismatch";
CM_ SG_ 293 UI_a182_VideoPipelineOverrun "Touchscreen user interface computer: a182 video pipeline overrun";
CM_ SG_ 293 UI_a183_DDAWFaulted "Touchscreen user interface computer: a183 DDAW faulted";
CM_ SG_ 293 UI_a184_ISAFaulted "Touchscreen user interface computer: a184 ISA faulted";
CM_ SG_ 293 UI_a185_ELKSDisabled "Touchscreen user interface computer: a185 ELKS disabled";
CM_ SG_ 293 UI_a186_ELKSUnavailable "Touchscreen user interface computer: a186 ELKS unavailable";
CM_ SG_ 293 UI_a187_TunerFirmwareMismatchedV "Touchscreen user interface computer: a187 tuner firmware mismatched version";
CM_ SG_ 293 UI_a188_TunerFirmwareMismatchedA "Touchscreen user interface computer: a188 tuner firmware mismatched API";
CM_ SG_ 293 UI_a189_TunerWatchdogReset "Touchscreen user interface computer: a189 tuner watchdog reset";
CM_ SG_ 293 UI_a190_TunerMIA "Touchscreen user interface computer: a190 tuner MIA";
CM_ SG_ 293 UI_a191_TunerUpdateFailed "Touchscreen user interface computer: a191 tuner update failed";
CM_ SG_ 293 UI_a192_AudioWatchdogReboot "Touchscreen user interface computer: a192 audio watchdog reboot";
CM_ BO_ 294 "Touchscreen user interface computer message: alert matrix4";
CM_ SG_ 294 UI_a193_TcuRNandFwVersionMismatc "Touchscreen user interface computer: a193 tcu r nand fw version mismatch";
CM_ SG_ 294 UI_a194_AudioweaverRestarted "Touchscreen user interface computer: a194 audioweaver restarted";
CM_ SG_ 294 UI_a195_gtwMfdUdpApiFired "Touchscreen user interface computer: a195 gtw mfd udp api fired";
CM_ SG_ 294 UI_a196_AMDI2C3BusInoperable "Touchscreen user interface computer: a196 AMDI2 C3 bus inoperable";
CM_ SG_ 294 UI_a197_AMDI2C1BusInoperable "Touchscreen user interface computer: a197 AMDI2 C1 bus inoperable";
CM_ SG_ 294 UI_a198_IncompatibleBTUSBHubHard "Touchscreen user interface computer: a198 incompatible BTUSB hub hardware";
CM_ SG_ 294 UI_a199_HighAPedalDetectedAtColl "Touchscreen user interface computer: a199 high a pedal detected at collision";
CM_ SG_ 294 UI_a200_UIFirmwareVersionMismatc "Touchscreen user interface computer: a200 UI firmware version mismatch";
CM_ SG_ 294 UI_a201_rearDisplayDisconnected "Touchscreen user interface computer: a201 rear display disconnected";
CM_ SG_ 294 UI_a202_sysMemoryIncorrect "Touchscreen user interface computer: a202 sys memory incorrect";
CM_ SG_ 294 UI_a204_ModemSleepFailure "Touchscreen user interface computer: a204 modem sleep failure";
CM_ SG_ 294 UI_a205_ModemSleepSignalMismatch "Touchscreen user interface computer: a205 modem sleep signal mismatch";
CM_ SG_ 294 UI_a206_ModemMIAAfterWake "Touchscreen user interface computer: a206 modem MIA after wake";
CM_ SG_ 294 UI_a208_mqttClientDisconnected "Touchscreen user interface computer: a208 mqtt client disconnected";
CM_ SG_ 294 UI_a209_dataCallDisconnected "Touchscreen user interface computer: a209 data call disconnected";
CM_ SG_ 294 UI_a210_CellularCSRegFail "Touchscreen user interface computer: a210 cellular CS reg fail";
CM_ SG_ 294 UI_a211_AEBSDisabled "Touchscreen user interface computer: a211 AEBS disabled";
CM_ SG_ 294 UI_a212_AEBSFaulted "Touchscreen user interface computer: a212 AEBS faulted";
CM_ SG_ 294 UI_a213_ISADisabled "Touchscreen user interface computer: a213 ISA disabled";
CM_ SG_ 294 UI_a214_pmHelperFailure "Touchscreen user interface computer: a214 pm helper failure";
CM_ SG_ 294 UI_a215_compositorStallDetected "Touchscreen user interface computer: a215 compositor stall detected";
CM_ SG_ 294 UI_a216_AudioA2bCircuitProblem "Touchscreen user interface computer: a216 audio a2b circuit problem";
CM_ SG_ 294 UI_a217_CgroupMemoryPressure "Touchscreen user interface computer: a217 cgroup memory pressure";
CM_ SG_ 294 UI_a218_AudiodNoAudioDevices "Touchscreen user interface computer: a218 audiod no audio devices";
CM_ SG_ 294 UI_a219_CompositorWatchdog "Touchscreen user interface computer: a219 compositor watchdog";
CM_ SG_ 294 UI_a220_MediaBrowseError "Touchscreen user interface computer: a220 media browse error";
CM_ SG_ 294 UI_a221_NavigationServiceError "Touchscreen user interface computer: a221 navigation service error";
CM_ SG_ 294 UI_a222_QtCarRestart "Signal reported by Touchscreen user interface computer";
CM_ SG_ 294 UI_a223_databaseError "Touchscreen user interface computer: a223 database error";
CM_ SG_ 294 UI_a224_centerDisplayDisconnecte "Touchscreen user interface computer: a224 center display disconnected";
CM_ SG_ 294 UI_a225_clusterDisplayDisconnect "Touchscreen user interface computer: a225 cluster display disconnected";
CM_ SG_ 294 UI_a226_largePhoneContactSync "Touchscreen user interface computer: a226 large phone contact sync";
CM_ SG_ 294 UI_a228_pipewireXrunBurst "Touchscreen user interface computer: a228 pipewire xrun burst";
CM_ SG_ 294 UI_a229_SerDesError "Touchscreen user interface computer: a229 ser des error";
CM_ SG_ 294 UI_a230_ModemSimCardMismatch "Touchscreen user interface computer: a230 modem sim card mismatch";
CM_ SG_ 294 UI_a231_SleepCancelled "Touchscreen user interface computer: a231 sleep cancelled";
CM_ SG_ 294 UI_a232_processExitError "Touchscreen user interface computer: a232 process exit error";
CM_ SG_ 294 UI_a233_ModemRFFailure "Touchscreen user interface computer: a233 modem RF failure";
CM_ SG_ 294 UI_a234_AMDI2C0Timeout "Touchscreen user interface computer: a234 AMDI2 C0 timeout";
CM_ SG_ 294 UI_a235_AMDI2C1Timeout "Touchscreen user interface computer: a235 AMDI2 C1 timeout";
CM_ SG_ 294 UI_a236_ModemOnResetState "Touchscreen user interface computer: a236 modem on reset state";
CM_ SG_ 294 UI_a237_ClipUploadActive "Touchscreen user interface computer: a237 clip upload active";
CM_ SG_ 294 UI_a238_ModemConfigMismatch "Touchscreen user interface computer: a238 modem config mismatch";
CM_ SG_ 294 UI_a240_ethError "Touchscreen user interface computer: a240 eth error";
CM_ SG_ 294 UI_a241_AxCPError "Touchscreen user interface computer: a241 ax CP error";
CM_ SG_ 294 UI_a242_uiHealthFaultInjectionAc "Touchscreen user interface computer: a242 ui health fault injection active";
CM_ SG_ 294 UI_a243_pmDisplayCheckFailure "Touchscreen user interface computer: a243 pm display check failure";
CM_ SG_ 294 UI_a244_segfault "Touchscreen user interface computer: a244 segfault";
CM_ SG_ 294 UI_a245_taskHung "Touchscreen user interface computer: a245 task hung";
CM_ SG_ 294 UI_a246_gpuFenceTimeout "Touchscreen user interface computer: a246 gpu fence timeout";
CM_ SG_ 294 UI_a247_StalklessDisplayBackligh "Touchscreen user interface computer: a247 stalkless display backlight failure";
CM_ SG_ 294 UI_a252_TPMErrorReceive "Touchscreen user interface computer: a252 TPM error receive";
CM_ SG_ 294 UI_a253_maintenanceHistoryRecord "Touchscreen user interface computer: a253 maintenance history recorded";
CM_ SG_ 294 UI_a254_appCertificateExpired "Touchscreen user interface computer: a254 app certificate expired";
CM_ SG_ 294 UI_a255_apbCertificateExpired "Touchscreen user interface computer: a255 apb certificate expired";
CM_ SG_ 294 UI_a256_sapFailedToEnable "Touchscreen user interface computer: a256 sap failed to enable";
CM_ BO_ 295 "Touchscreen user interface computer message: alert matrix5";
CM_ SG_ 295 UI_a257_modemRebooting "Touchscreen user interface computer: a257 modem rebooting";
CM_ SG_ 295 UI_a258_sapFailedToPowerOn "Touchscreen user interface computer: a258 sap failed to power on";
CM_ SG_ 295 UI_a259_sapChannelMismatch "Touchscreen user interface computer: a259 sap channel mismatch";
CM_ SG_ 295 UI_a260_sapWrongChannel "Touchscreen user interface computer: a260 sap wrong channel";
CM_ SG_ 295 UI_a261_bluetoothStackPanic "Touchscreen user interface computer: a261 bluetooth stack panic";
CM_ SG_ 295 UI_a263_ecuLogUploadFailure "Touchscreen user interface computer: a263 ecu log upload failure";
CM_ SG_ 295 UI_a264_invalidEpaRange "Touchscreen user interface computer: a264 invalid epa range";
CM_ SG_ 295 UI_a265_USBHostControllerUnrecov "Touchscreen user interface computer: a265 USB host controller unrecoverable";
CM_ SG_ 295 UI_a266_DashcamRecentBufferDurat "Touchscreen user interface computer: a266 dashcam recent buffer duration reduced";
CM_ SG_ 295 UI_a272_eapTlsCSRFailure "Touchscreen user interface computer: a272 eap tls CSR failure";
CM_ SG_ 295 UI_a273_AudioDbusFailure "Touchscreen user interface computer: a273 audio dbus failure";
CM_ SG_ 295 UI_a274_ContextualHintCardEvent "Touchscreen user interface computer: a274 contextual hint card event";
CM_ SG_ 295 UI_a275_ADDWFaulted "Touchscreen user interface computer: a275 ADDW faulted";
CM_ SG_ 295 UI_a276_PrivateNetworkProfileAct "Touchscreen user interface computer: a276 private network profile active";
CM_ SG_ 295 UI_a277_PONRPopupShown "Touchscreen user interface computer: a277 PONR popup shown";
CM_ SG_ 295 UI_a278_gpsHwDegraded "Touchscreen user interface computer: a278 gps hw degraded";
CM_ BO_ 1279 "Touchscreen user interface computer message: energy consumption info";
CM_ SG_ 1279 UI_energyConsumptionInfoIndex "Touchscreen user interface computer: energy consumption info index";
CM_ SG_ 1279 UI_energyLossTotal_epa "Energy amount for a given bucket for an energy consumption baseline (raw/real energy consumed)";
CM_ SG_ 1279 UI_energyLossDriving_epa "Energy amount for a given bucket for an energy consumption baseline (raw/real energy consumed)";
CM_ SG_ 1279 UI_energyLossClimate_epa "Energy amount for a given bucket for an energy consumption baseline (raw/real energy consumed)";
CM_ SG_ 1279 UI_energyLossBattCond_epa "Energy amount for a given bucket for an energy consumption baseline (raw/real energy consumed)";
CM_ SG_ 1279 UI_energyLossElevation_epa "Energy amount for a given bucket for an energy consumption baseline (raw/real energy consumed)";
CM_ SG_ 1279 UI_energyLossAcc_epa "Energy amount for a given bucket for an energy consumption baseline (raw/real energy consumed)";
CM_ SG_ 1279 UI_energyLossTotalSinceCharge_ep "Energy amount for a given bucket for an energy consumption baseline (raw/real energy consumed)";
CM_ SG_ 1279 UI_energyLossDrivingSinceCharge_ "Energy amount for a given bucket for an energy consumption baseline (raw/real energy consumed)";
CM_ SG_ 1279 UI_energyLossClimateSinceCharge_ "Energy amount for a given bucket for an energy consumption baseline (raw/real energy consumed)";
CM_ SG_ 1279 UI_energyLossBattCondSinceCharge "Energy amount for a given bucket for an energy consumption baseline (raw/real energy consumed)";
CM_ SG_ 1279 UI_energyLossElevationSinceCharg "Energy amount for a given bucket for an energy consumption baseline (raw/real energy consumed)";
CM_ SG_ 1279 UI_energyLossAccSinceCharge_epa "Energy amount for a given bucket for an energy consumption baseline (raw/real energy consumed)";
CM_ SG_ 1279 UI_energyLossTotalSinceTripStart "Energy amount for a given bucket for an energy consumption baseline (raw/real energy consumed)";
CM_ SG_ 1279 UI_energyLossDrivingSinceTripSta "Energy amount for a given bucket for an energy consumption baseline (raw/real energy consumed)";
CM_ SG_ 1279 UI_energyLossClimateSinceTripSta "Energy amount for a given bucket for an energy consumption baseline (raw/real energy consumed)";
CM_ SG_ 1279 UI_energyLossBattCondSinceTripSt "Energy amount for a given bucket for an energy consumption baseline (raw/real energy consumed)";
CM_ SG_ 1279 UI_energyLossElevationSinceTripS "Energy amount for a given bucket for an energy consumption baseline (raw/real energy consumed)";
CM_ SG_ 1279 UI_energyLossAccSinceTripStart "Energy amount for a given bucket for an energy consumption baseline (raw/real energy consumed)";
CM_ SG_ 1279 UI_energyDeltaTotal_epa "Energy amount for a given bucket for an energy consumption baseline (raw/real energy consumed)";
CM_ SG_ 1279 UI_energyDeltaDriving_epa "Energy amount for a given bucket for an energy consumption baseline (raw/real energy consumed)";
CM_ SG_ 1279 UI_energyDeltaClimate_epa "Energy amount for a given bucket for an energy consumption baseline (raw/real energy consumed)";
CM_ SG_ 1279 UI_energyDeltaBattCond_epa "Energy amount for a given bucket for an energy consumption baseline (raw/real energy consumed)";
CM_ SG_ 1279 UI_energyDeltaElevation_epa "Energy amount for a given bucket for an energy consumption baseline (raw/real energy consumed)";
CM_ SG_ 1279 UI_energyDeltaAcc_epa "Energy amount for a given bucket for an energy consumption baseline (raw/real energy consumed)";
CM_ SG_ 1279 UI_uiDeltaOffsetTotal_epa "Energy amount for a given bucket for an energy consumption baseline (raw/real energy consumed)";
CM_ SG_ 1279 UI_uiDeltaOffsetDriving_epa "Energy amount for a given bucket for an energy consumption baseline (raw/real energy consumed)";
CM_ SG_ 1279 UI_uiDeltaOffsetClimate_epa "Energy amount for a given bucket for an energy consumption baseline (raw/real energy consumed)";
CM_ SG_ 1279 UI_uiDeltaOffsetBattCond_epa "Energy amount for a given bucket for an energy consumption baseline (raw/real energy consumed)";
CM_ SG_ 1279 UI_uiDeltaOffsetElevation_epa "Energy amount for a given bucket for an energy consumption baseline (raw/real energy consumed)";
CM_ SG_ 1279 UI_uiDeltaOffsetAcc_epa "Energy amount for a given bucket for an energy consumption baseline (raw/real energy consumed)";
CM_ SG_ 1279 UI_rawToUiEnergyRatio_epa "Ratio used for conversion between UI and raw energy domains";
CM_ SG_ 1279 UI_driveDistance_epa "Distance driven for an energy consumption baseline";
CM_ SG_ 1279 UI_energyDeltaTotalSinceCharge_e "Energy amount for a given bucket for an energy consumption baseline (raw/real energy consumed)";
CM_ SG_ 1279 UI_energyDeltaDrivingSinceCharge "Energy amount for a given bucket for an energy consumption baseline (raw/real energy consumed)";
CM_ SG_ 1279 UI_energyDeltaClimateSinceCharge "Energy amount for a given bucket for an energy consumption baseline (raw/real energy consumed)";
CM_ SG_ 1279 UI_energyDeltaBattCondSinceCharg "Energy amount for a given bucket for an energy consumption baseline (raw/real energy consumed)";
CM_ SG_ 1279 UI_energyDeltaElevationSinceChar "Energy amount for a given bucket for an energy consumption baseline (raw/real energy consumed)";
CM_ SG_ 1279 UI_energyDeltaAccSinceCharge_epa "Energy amount for a given bucket for an energy consumption baseline (raw/real energy consumed)";
CM_ SG_ 1279 UI_uiDeltaOffsetTotalSinceCharge "Energy amount for a given bucket for an energy consumption baseline (raw/real energy consumed)";
CM_ SG_ 1279 UI_uiDeltaOffsetDrivingSinceChar "Energy amount for a given bucket for an energy consumption baseline (raw/real energy consumed)";
CM_ SG_ 1279 UI_uiDeltaOffsetClimateSinceChar "Energy amount for a given bucket for an energy consumption baseline (raw/real energy consumed)";
CM_ SG_ 1279 UI_uiDeltaOffsetBattCondSinceCha "Energy amount for a given bucket for an energy consumption baseline (raw/real energy consumed)";
CM_ SG_ 1279 UI_uiDeltaOffsetElevationSinceCh "Energy amount for a given bucket for an energy consumption baseline (raw/real energy consumed)";
CM_ SG_ 1279 UI_uiDeltaOffsetAccSinceCharge_e "Energy amount for a given bucket for an energy consumption baseline (raw/real energy consumed)";
CM_ SG_ 1279 UI_rawToUiEnergyRatioSinceCharge "Ratio used for conversion between UI and raw energy domains";
CM_ SG_ 1279 UI_driveDistanceSinceCharge_epa "Distance driven for an energy consumption baseline";
CM_ SG_ 1279 UI_energyDeltaTotalSinceTripStar "Energy amount for a given bucket for an energy consumption baseline (raw/real energy consumed)";
CM_ SG_ 1279 UI_energyDeltaDrivingSinceTripSt "Energy amount for a given bucket for an energy consumption baseline (raw/real energy consumed)";
CM_ SG_ 1279 UI_energyDeltaClimateSinceTripSt "Energy amount for a given bucket for an energy consumption baseline (raw/real energy consumed)";
CM_ SG_ 1279 UI_energyDeltaBattCondSinceTripS "Energy amount for a given bucket for an energy consumption baseline (raw/real energy consumed)";
CM_ SG_ 1279 UI_energyDeltaElevationSinceTrip "Energy amount for a given bucket for an energy consumption baseline (raw/real energy consumed)";
CM_ SG_ 1279 UI_energyDeltaAccSinceTripStart "Energy amount for a given bucket for an energy consumption baseline (raw/real energy consumed)";
CM_ SG_ 1279 UI_uiDeltaOffsetTotalSinceTripSt "Energy amount for a given bucket for an energy consumption baseline (raw/real energy consumed)";
CM_ SG_ 1279 UI_uiDeltaOffsetDrivingSinceTrip "Energy amount for a given bucket for an energy consumption baseline (raw/real energy consumed)";
CM_ SG_ 1279 UI_uiDeltaOffsetClimateSinceTrip "Energy amount for a given bucket for an energy consumption baseline (raw/real energy consumed)";
CM_ SG_ 1279 UI_uiDeltaOffsetBattCondSinceTri "Energy amount for a given bucket for an energy consumption baseline (raw/real energy consumed)";
CM_ SG_ 1279 UI_uiDeltaOffsetElevationSinceTr "Energy amount for a given bucket for an energy consumption baseline (raw/real energy consumed)";
CM_ SG_ 1279 UI_uiDeltaOffsetAccSinceTripStar "Energy amount for a given bucket for an energy consumption baseline (raw/real energy consumed)";
CM_ SG_ 1279 UI_rawToUiEnergyRatioSinceTripSt "Ratio used for conversion between UI and raw energy domains";
CM_ SG_ 1279 UI_driveDistanceSinceTripStart "Distance driven for an energy consumption baseline";
CM_ SG_ 1279 UI_voyagerEnabled "Touchscreen user interface computer: voyager enabled";
CM_ SG_ 1279 UI_trailerMass "Trailer mass from user input";
CM_ BO_ 993 "Touchscreen user interface computer message: gear slider info";
CM_ SG_ 993 UI_gearSliderInfoIndex "Touchscreen user interface computer: gear slider info index";
CM_ SG_ 993 UI_gearSliderW "Touchscreen user interface computer: gear slider w";
CM_ SG_ 993 UI_gearSliderH "Touchscreen user interface computer: gear slider h";
CM_ SG_ 993 UI_gearSliderX "Touchscreen user interface computer: gear slider x";
CM_ SG_ 993 UI_gearSliderY "Touchscreen user interface computer: gear slider y";
CM_ SG_ 993 UI_gearParkW "Touchscreen user interface computer: gear park w";
CM_ SG_ 993 UI_gearParkH "Touchscreen user interface computer: gear park h";
CM_ SG_ 993 UI_gearParkX "Touchscreen user interface computer: gear park x";
CM_ SG_ 993 UI_gearParkY "Touchscreen user interface computer: gear park y";
CM_ SG_ 993 UI_gearNeutralW "Touchscreen user interface computer: gear neutral w";
CM_ SG_ 993 UI_gearNeutralH "Touchscreen user interface computer: gear neutral h";
CM_ SG_ 993 UI_gearNeutralX "Touchscreen user interface computer: gear neutral x";
CM_ SG_ 993 UI_gearNeutralY "Touchscreen user interface computer: gear neutral y";
CM_ BO_ 563 "Touchscreen user interface computer message: stalkless control";
CM_ SG_ 563 UI_stalklessControlCounter "Touchscreen user interface computer: stalkless control counter";
CM_ SG_ 563 UI_stalklessControlChecksum "Touchscreen user interface computer: stalkless control checksum";
CM_ SG_ 563 UI_gearStripSuppressCounter "Touchscreen user interface computer: gear strip suppress counter";
CM_ SG_ 563 UI_gearRequest "UI gear request from UI; raw 0 = signal not available (SNA)";
CM_ SG_ 563 UI_autopilotRequest "Touchscreen user interface computer: autopilot request";
CM_ SG_ 563 UI_gearStripShowing "UI communicating to GTW that the gear strip is visible on the screen as part of a handshake";
CM_ SG_ 563 UI_gearStripLocation "Touchscreen user interface computer: gear strip location";
CM_ SG_ 563 UI_parkButtonShowing "Touchscreen user interface computer: park button showing";
CM_ SG_ 563 UI_neutralButtonShowing "Touchscreen user interface computer: neutral button showing";
CM_ SG_ 563 UI_gearStripForceShow "UI request to GTW to show the gear strip";
CM_ SG_ 563 UI_neutralButtonDrawerForceShow "Touchscreen user interface computer: neutral button drawer force show";
CM_ SG_ 563 UI_autoParkAvailable "UI communicating to GTW that the autpark functionality is available";
CM_ SG_ 563 UI_autoParkShowing "Touchscreen user interface computer: auto park showing";
CM_ SG_ 563 UI_gearStripSuppressActive "UI communicating to GTW that the gear strip should not be shown";
CM_ SG_ 563 UI_gearNeutralPressed "Neutral button is being pressed";
CM_ BO_ 986 "Touchscreen user interface computer message: status3";
CM_ SG_ 986 UI_wifiRegDomain "Indicates the Wi-Fi regulatory domain.";
CM_ SG_ 986 UI_wifiTethered "Monitors whether Wi-Fi is connected while driving.";
CM_ BO_ 661 "Touchscreen user interface computer message: system monitor";
CM_ SG_ 661 UI_systemMonitorIndex "Touchscreen user interface computer: system monitor index";
CM_ SG_ 661 UI_SystemMemUsage "Monitors system memory usage";
CM_ SG_ 661 UI_QtCarMemUsage "Monitors memory usage of the primary User Interface application";
CM_ SG_ 661 UI_QtCarCPUUsage "Monitors CPU usage of the primary User Interface application";
CM_ SG_ 661 UI_emmcStatus "Touchscreen user interface computer: emmc status";
CM_ SG_ 661 UI_SystemCPUUsage "Monitors system CPU usage";
CM_ SG_ 661 UI_HomeHealth "Touchscreen user interface computer: home health";
CM_ SG_ 661 UI_VarHealth "Touchscreen user interface computer: var health";
CM_ SG_ 661 UI_LogHealth "Touchscreen user interface computer: log health";
CM_ SG_ 661 UI_TmpfsHealth "Touchscreen user interface computer: tmpfs health";
CM_ SG_ 661 UI_emmcDataWritten "Touchscreen user interface computer: emmc data written";
CM_ SG_ 661 UI_emmcTotalErases "Touchscreen user interface computer: emmc total erases";
CM_ BO_ 1263 "Touchscreen user interface computer message: trip planner info";
CM_ SG_ 1263 UI_fwHeatOnNavArrivalSOE "Energy percentages shown in the UI";
CM_ SG_ 1263 UI_voyagerHeatOnNavArrivalSOE "Energy percentages shown in the UI";
CM_ SG_ 1263 UI_usingVoyagerPreconditioning "Touchscreen user interface computer: using voyager preconditioning";
CM_ BO_ 139 "Touchscreen user interface computer message: trip planning2";
CM_ SG_ 139 UI_maxSpeedToReachDestination "maximum speed to reach destination without significant risk of running out of energy; raw 65535 = signal not available (SNA)";
CM_ SG_ 139 UI_remainingWeightedRMSSpeed "Touchscreen user interface computer: remaining weighted RMS speed; raw 65535 = signal not available (SNA)";
CM_ SG_ 139 UI_timeToDestination "remaining time to reach destination; raw 65535 = signal not available (SNA)";
CM_ BO_ 1173 "Touchscreen user interface computer message: trip planning3";
CM_ SG_ 1173 UI_predictedEnergy "initially predicted energy in kWh for current location along navigation route; raw 32768 = signal not available (SNA)";
CM_ SG_ 1173 UI_predictedEnergyLearned "Touchscreen user interface computer: predicted energy learned; raw 32768 = signal not available (SNA)";
CM_ SG_ 1173 UI_hindsightEnergy "hindsight energy, the model predicted energy based on measured speed and acceleration for the current location along navigation route; raw 32768 = signal not available (SNA)";
CM_ SG_ 1173 UI_hindsightEnergyLearned "Touchscreen user interface computer: hindsight energy learned; raw 32768 = signal not available (SNA)";
CM_ BO_ 1174 "Touchscreen user interface computer message: trip planning4";
CM_ SG_ 1174 UI_longTermEnergyModelError "Touchscreen user interface computer: long term energy model error; raw 128 = signal not available (SNA)";
CM_ SG_ 1174 UI_longTermRmsSpeedRatio "Touchscreen user interface computer: long term rms speed ratio; raw 255 = signal not available (SNA)";
CM_ SG_ 1174 UI_gradeCorrectedEnergy "Touchscreen user interface computer: grade corrected energy; raw 32768 = signal not available (SNA)";
CM_ SG_ 1174 UI_gradeCorrectedEnergyLearned "Touchscreen user interface computer: grade corrected energy learned; raw 32768 = signal not available (SNA)";
CM_ BO_ 1175 "Touchscreen user interface computer message: trip planning5";
CM_ SG_ 1175 UI_battPreconditionOnNavTime "Touchscreen user interface computer: batt precondition on nav time; raw 65535 = signal not available (SNA)";
CM_ SG_ 1175 UI_maxBattPreconditionOnNavTime "Touchscreen user interface computer: max batt precondition on nav time; raw 65535 = signal not available (SNA)";
CM_ BO_ 649 "Left body controller message: logging10 hz";
CM_ SG_ 649 VCLEFT_logging10HzIndex "Left body controller: logging10 hz index";
CM_ SG_ 649 VCLEFT_hvacBlowerRs "Left body controller: hvac blower rs; raw 255 = signal not available (SNA)";
CM_ SG_ 649 VCLEFT_hvacBlowerIPhase0 "Left body controller: hvac blower i phase0; raw 127 = signal not available (SNA)";
CM_ SG_ 649 VCLEFT_hvacBlowerIPhase1 "Left body controller: hvac blower i phase1; raw 127 = signal not available (SNA)";
CM_ SG_ 649 VCLEFT_hvacBlowerIPhase2 "Left body controller: hvac blower i phase2; raw 127 = signal not available (SNA)";
CM_ SG_ 649 VCLEFT_hvacBlower_IO_CBC_HEAD "Left body controller: hvac blower IO CBC HEAD";
CM_ SG_ 649 VCLEFT_hvacBlower_IO_CBC_TAIL "Left body controller: hvac blower IO CBC TAIL";
CM_ SG_ 649 VCLEFT_hvacBlower_IO_CBC_TAIL_va "Left body controller: hvac blower IO CBC TAIL valid";
CM_ SG_ 649 VCLEFT_hvacBlower_IO_CBC_Status "Left body controller: hvac blower IO CBC status";
CM_ SG_ 649 VCLEFT_hvacBlower_IO_CBC_numUart "Left body controller: hvac blower IO CBC num uart err";
CM_ SG_ 649 VCLEFT_hvacBlowerCBCEstState "Left body controller: hvac blower CBC est state";
CM_ SG_ 649 VCLEFT_hvacBlowerCBCCtrlState "Left body controller: hvac blower CBC ctrl state";
CM_ SG_ 649 VCLEFT_hvacBlowerITerm "Left body controller: hvac blower i term; raw 127 = signal not available (SNA)";
CM_ SG_ 649 VCLEFT_hvacBlowerSpiError "Left body controller: hvac blower spi error";
CM_ SG_ 649 VCLEFT_hvacBlowerRsOnlineActive "Left body controller: hvac blower rs online active";
BA_DEF_ BO_ "GenMsgCycleTime" INT 0 3600000;
BA_DEF_ BO_ "GenMsgSendType" ENUM "Cyclic","NotUsed","NotUsed","NotUsed","NotUsed","NotUsed","NotUsed","IfActive","NoMsgSendType","NotUsed";
BA_DEF_ BO_ "VFrameFormat" ENUM "StandardCAN","ExtendedCAN","reserved","J1939PG","reserved","reserved","reserved","reserved","reserved","reserved","reserved","reserved","reserved","reserved","StandardCAN_FD","ExtendedCAN_FD";
BA_DEF_ BO_ "CANFD_BRS" ENUM "0","1";
BA_DEF_ SG_ "GenSigSNA" STRING;
BA_DEF_ SG_ "SystemSignalLongSymbol" STRING;
BA_DEF_ SG_ "Confidence" ENUM "validated","plausible","layout-only","contradicted";
BA_DEF_DEF_ "GenMsgCycleTime" 0;
BA_DEF_DEF_ "GenMsgSendType" "NoMsgSendType";
BA_DEF_DEF_ "VFrameFormat" "StandardCAN";
BA_DEF_DEF_ "CANFD_BRS" "1";
BA_DEF_DEF_ "GenSigSNA" "";
BA_DEF_DEF_ "SystemSignalLongSymbol" "";
BA_DEF_DEF_ "Confidence" "layout-only";
BA_ "GenMsgCycleTime" BO_ 979 500;
BA_ "GenMsgSendType" BO_ 979 0;
BA_ "GenMsgCycleTime" BO_ 291 1000;
BA_ "GenMsgSendType" BO_ 291 0;
BA_ "GenMsgCycleTime" BO_ 292 1000;
BA_ "GenMsgSendType" BO_ 292 0;
BA_ "GenMsgCycleTime" BO_ 293 1000;
BA_ "GenMsgSendType" BO_ 293 0;
BA_ "GenMsgCycleTime" BO_ 294 1000;
BA_ "GenMsgSendType" BO_ 294 0;
BA_ "GenMsgCycleTime" BO_ 295 1000;
BA_ "GenMsgSendType" BO_ 295 0;
BA_ "GenMsgCycleTime" BO_ 1279 1000;
BA_ "GenMsgSendType" BO_ 1279 0;
BA_ "GenMsgCycleTime" BO_ 993 2000;
BA_ "GenMsgSendType" BO_ 993 0;
BA_ "GenMsgCycleTime" BO_ 563 500;
BA_ "GenMsgSendType" BO_ 563 0;
BA_ "GenMsgCycleTime" BO_ 986 1000;
BA_ "GenMsgSendType" BO_ 986 0;
BA_ "GenMsgCycleTime" BO_ 661 15000;
BA_ "GenMsgSendType" BO_ 661 0;
BA_ "GenMsgCycleTime" BO_ 1263 1000;
BA_ "GenMsgSendType" BO_ 1263 0;
BA_ "GenMsgCycleTime" BO_ 139 1000;
BA_ "GenMsgSendType" BO_ 139 0;
BA_ "GenMsgCycleTime" BO_ 1173 1000;
BA_ "GenMsgSendType" BO_ 1173 0;
BA_ "GenMsgCycleTime" BO_ 1174 1000;
BA_ "GenMsgSendType" BO_ 1174 0;
BA_ "GenMsgCycleTime" BO_ 1175 1000;
BA_ "GenMsgSendType" BO_ 1175 0;
BA_ "GenMsgCycleTime" BO_ 649 100;
BA_ "GenMsgSendType" BO_ 649 0;
BA_ "Confidence" SG_ 979 UI_airbagCutoffSwState 0;
BA_ "GenSigSNA" SG_ 979 UI_airbagCutoffSwState "2";
BA_ "Confidence" SG_ 979 UI_warningIndicatorStatus 1;
BA_ "GenSigSNA" SG_ 979 UI_warningIndicatorStatus "3";
BA_ "Confidence" SG_ 1523 UI_alertID 1;
BA_ "Confidence" SG_ 1523 UI_alertState 1;
BA_ "Confidence" SG_ 1523 UI_a009_squashfsDevice 1;
BA_ "Confidence" SG_ 1523 UI_a036_audioWatchdogReason 1;
BA_ "SystemSignalLongSymbol" SG_ 1523 UI_a045_ManualECallButtonDisconn "UI_a045_ManualECallButtonDisconnected";
BA_ "Confidence" SG_ 1523 UI_a087_BmpResetType 1;
BA_ "Confidence" SG_ 1523 UI_a131_DisplayPortFailureType 1;
BA_ "Confidence" SG_ 1523 UI_a147_whichASIL 1;
BA_ "Confidence" SG_ 1523 UI_a147_errorCode 1;
BA_ "Confidence" SG_ 1523 UI_a148_sleepType 1;
BA_ "Confidence" SG_ 1523 UI_a148_lastFailedPmSuspendDev 1;
BA_ "Confidence" SG_ 1523 UI_a149_displayType 1;
BA_ "Confidence" SG_ 1523 UI_a149_displaySeat 1;
BA_ "Confidence" SG_ 1523 UI_a149_errorCode 1;
BA_ "Confidence" SG_ 1523 UI_a153_processName 1;
BA_ "Confidence" SG_ 1523 UI_a153_restartReason 1;
BA_ "Confidence" SG_ 1523 UI_a158_UsbDeviceMountErrorCode 1;
BA_ "Confidence" SG_ 1523 UI_a165_fsCorruptedDevice 1;
BA_ "Confidence" SG_ 1523 UI_a166_fsErrorDevice 1;
BA_ "Confidence" SG_ 1523 UI_a167_processId 1;
BA_ "Confidence" SG_ 1523 UI_a173_errorCode 1;
BA_ "Confidence" SG_ 1523 UI_a173_lastFailedPmSuspendDev 1;
BA_ "Confidence" SG_ 1523 UI_a176_PrimaryAntenna 1;
BA_ "Confidence" SG_ 1523 UI_a176_SecondaryAntenna 1;
BA_ "Confidence" SG_ 1523 UI_a176_TertiaryAntenna 1;
BA_ "Confidence" SG_ 1523 UI_a177_errorCode 1;
BA_ "Confidence" SG_ 1523 UI_a177_errorSource 1;
BA_ "Confidence" SG_ 1523 UI_a192_AudioRebootState 1;
BA_ "Confidence" SG_ 1523 UI_a204_ModemSleepFailureReason 1;
BA_ "SystemSignalLongSymbol" SG_ 1523 UI_a208_mqttClientDisconnectReas "UI_a208_mqttClientDisconnectReason";
BA_ "Confidence" SG_ 1523 UI_a214_lastFailedPmSuspendDev 1;
BA_ "Confidence" SG_ 1523 UI_a216_circuitProblem 1;
BA_ "Confidence" SG_ 1523 UI_a216_circuitNode 1;
BA_ "Confidence" SG_ 1523 UI_a217_cgroupName 1;
BA_ "Confidence" SG_ 1523 UI_a220_errorCode 1;
BA_ "Confidence" SG_ 1523 UI_a221_errorCode 1;
BA_ "Confidence" SG_ 1523 UI_a221_networkErrorCode 1;
BA_ "GenSigSNA" SG_ 1523 UI_a221_networkErrorCode "500";
BA_ "Confidence" SG_ 1523 UI_a222_errorCode 1;
BA_ "Confidence" SG_ 1523 UI_a223_database 1;
BA_ "Confidence" SG_ 1523 UI_a229_errorCode 1;
BA_ "Confidence" SG_ 1523 UI_a231_sleepType 1;
BA_ "Confidence" SG_ 1523 UI_a232_processExited 1;
BA_ "Confidence" SG_ 1523 UI_a232_processSignal 1;
BA_ "Confidence" SG_ 1523 UI_a240_ethErrorType 1;
BA_ "SystemSignalLongSymbol" SG_ 1523 UI_a242_ConnectivityFaultInjecte "UI_a242_ConnectivityFaultInjected";
BA_ "SystemSignalLongSymbol" SG_ 1523 UI_a242_ConnectivityHWFaultInjec "UI_a242_ConnectivityHWFaultInjected";
BA_ "SystemSignalLongSymbol" SG_ 1523 UI_a242_CenterDispStatusFaultInj "UI_a242_CenterDispStatusFaultInjected";
BA_ "Confidence" SG_ 1523 UI_a247_displayType 1;
BA_ "Confidence" SG_ 1523 UI_a247_displaySeat 1;
BA_ "Confidence" SG_ 1523 UI_a257_ModemRebootReason 1;
BA_ "Confidence" SG_ 1523 UI_a257_ModemRebootEthPresent 1;
BA_ "Confidence" SG_ 1523 UI_a261_bluetoothStackPanicReaso 1;
BA_ "SystemSignalLongSymbol" SG_ 1523 UI_a261_bluetoothStackPanicReaso "UI_a261_bluetoothStackPanicReason";
BA_ "Confidence" SG_ 1523 UI_a274_hintCardType 1;
BA_ "Confidence" SG_ 1523 UI_a274_hintCardDismissOutcome 1;
BA_ "SystemSignalLongSymbol" SG_ 291 UI_a037_AudioWatchdogXrunStormEr "UI_a037_AudioWatchdogXrunStormError";
BA_ "SystemSignalLongSymbol" SG_ 291 UI_a038_AudioWatchdogA2bI2cLocku "UI_a038_AudioWatchdogA2bI2cLockupError";
BA_ "SystemSignalLongSymbol" SG_ 291 UI_a048_AudioPremiumAmpCheckFail "UI_a048_AudioPremiumAmpCheckFailed";
BA_ "SystemSignalLongSymbol" SG_ 291 UI_a056_ManualECallButtonDisconn "UI_a056_ManualECallButtonDisconnected";
BA_ "SystemSignalLongSymbol" SG_ 292 UI_a078_DashcamUsbDriveUnmountab "UI_a078_DashcamUsbDriveUnmountable";
BA_ "SystemSignalLongSymbol" SG_ 292 UI_a082_NumModemRebootStuckInECa "UI_a082_NumModemRebootStuckInECall";
BA_ "SystemSignalLongSymbol" SG_ 292 UI_a083_ECallProxyWatchdogTrigge "UI_a083_ECallProxyWatchdogTriggered";
BA_ "SystemSignalLongSymbol" SG_ 292 UI_a096_VideodPipelineIssueDetec "UI_a096_VideodPipelineIssueDetected";
BA_ "SystemSignalLongSymbol" SG_ 292 UI_a105_firmwareReinstallRequest "UI_a105_firmwareReinstallRequested";
BA_ "SystemSignalLongSymbol" SG_ 292 UI_a107_DashcamUsbDriveTooBigFor "UI_a107_DashcamUsbDriveTooBigForVfatFsck";
BA_ "SystemSignalLongSymbol" SG_ 292 UI_a108_DashcamUsbDriveGettingFu "UI_a108_DashcamUsbDriveGettingFull";
BA_ "SystemSignalLongSymbol" SG_ 292 UI_a111_DashcamUsbDriveNotSuperS "UI_a111_DashcamUsbDriveNotSuperSpeed";
BA_ "SystemSignalLongSymbol" SG_ 292 UI_a113_DashcamHasOnboardSentryC "UI_a113_DashcamHasOnboardSentryClips";
BA_ "SystemSignalLongSymbol" SG_ 292 UI_a114_drivingVisualizationDegr "UI_a114_drivingVisualizationDegraded";
BA_ "SystemSignalLongSymbol" SG_ 292 UI_a120_nvmePCIeLinkErrorDetecte "UI_a120_nvmePCIeLinkErrorDetected";
BA_ "SystemSignalLongSymbol" SG_ 293 UI_a132_AdspWatchdogRecoveryTrig "UI_a132_AdspWatchdogRecoveryTriggered";
BA_ "SystemSignalLongSymbol" SG_ 293 UI_a133_AdspWatchdogRecoveryFail "UI_a133_AdspWatchdogRecoveryFailed";
BA_ "SystemSignalLongSymbol" SG_ 293 UI_a137_ServiceShellActiveConnec "UI_a137_ServiceShellActiveConnection";
BA_ "SystemSignalLongSymbol" SG_ 293 UI_a151_carComputerThermalProble "UI_a151_carComputerThermalProblem";
BA_ "SystemSignalLongSymbol" SG_ 293 UI_a156_UsbFrontHubInstallMismat "UI_a156_UsbFrontHubInstallMismatch";
BA_ "SystemSignalLongSymbol" SG_ 293 UI_a157_MCUActiveCoolingRequeste "UI_a157_MCUActiveCoolingRequested";
BA_ "SystemSignalLongSymbol" SG_ 293 UI_a161_ECallTemporarilyUnavaila "UI_a161_ECallTemporarilyUnavailable";
BA_ "SystemSignalLongSymbol" SG_ 293 UI_a168_dgpuPowerOnSelfTestFailu "UI_a168_dgpuPowerOnSelfTestFailure";
BA_ "SystemSignalLongSymbol" SG_ 293 UI_a171_GraphicsLoadShedRequeste "UI_a171_GraphicsLoadShedRequested";
BA_ "SystemSignalLongSymbol" SG_ 293 UI_a172_GraphicsLoadShedUIFailur "UI_a172_GraphicsLoadShedUIFailure";
BA_ "SystemSignalLongSymbol" SG_ 293 UI_a181_ModemFirmwareVersionMism "UI_a181_ModemFirmwareVersionMismatch";
BA_ "SystemSignalLongSymbol" SG_ 293 UI_a187_TunerFirmwareMismatchedV "UI_a187_TunerFirmwareMismatchedVersion";
BA_ "SystemSignalLongSymbol" SG_ 293 UI_a188_TunerFirmwareMismatchedA "UI_a188_TunerFirmwareMismatchedAPI";
BA_ "SystemSignalLongSymbol" SG_ 294 UI_a193_TcuRNandFwVersionMismatc "UI_a193_TcuRNandFwVersionMismatch";
BA_ "SystemSignalLongSymbol" SG_ 294 UI_a198_IncompatibleBTUSBHubHard "UI_a198_IncompatibleBTUSBHubHardware";
BA_ "SystemSignalLongSymbol" SG_ 294 UI_a199_HighAPedalDetectedAtColl "UI_a199_HighAPedalDetectedAtCollision";
BA_ "SystemSignalLongSymbol" SG_ 294 UI_a200_UIFirmwareVersionMismatc "UI_a200_UIFirmwareVersionMismatch";
BA_ "SystemSignalLongSymbol" SG_ 294 UI_a224_centerDisplayDisconnecte "UI_a224_centerDisplayDisconnected";
BA_ "SystemSignalLongSymbol" SG_ 294 UI_a225_clusterDisplayDisconnect "UI_a225_clusterDisplayDisconnected";
BA_ "SystemSignalLongSymbol" SG_ 294 UI_a242_uiHealthFaultInjectionAc "UI_a242_uiHealthFaultInjectionActive";
BA_ "SystemSignalLongSymbol" SG_ 294 UI_a247_StalklessDisplayBackligh "UI_a247_StalklessDisplayBacklightFailure";
BA_ "SystemSignalLongSymbol" SG_ 294 UI_a253_maintenanceHistoryRecord "UI_a253_maintenanceHistoryRecorded";
BA_ "SystemSignalLongSymbol" SG_ 295 UI_a265_USBHostControllerUnrecov "UI_a265_USBHostControllerUnrecoverable";
BA_ "SystemSignalLongSymbol" SG_ 295 UI_a266_DashcamRecentBufferDurat "UI_a266_DashcamRecentBufferDurationReduced";
BA_ "SystemSignalLongSymbol" SG_ 295 UI_a276_PrivateNetworkProfileAct "UI_a276_PrivateNetworkProfileActive";
BA_ "Confidence" SG_ 1279 UI_energyConsumptionInfoIndex 1;
BA_ "Confidence" SG_ 1279 UI_energyLossTotal_epa 0;
BA_ "Confidence" SG_ 1279 UI_energyLossDriving_epa 0;
BA_ "Confidence" SG_ 1279 UI_energyLossClimate_epa 0;
BA_ "Confidence" SG_ 1279 UI_energyLossBattCond_epa 0;
BA_ "Confidence" SG_ 1279 UI_energyLossElevation_epa 0;
BA_ "Confidence" SG_ 1279 UI_energyLossAcc_epa 0;
BA_ "Confidence" SG_ 1279 UI_energyLossTotalSinceCharge_ep 0;
BA_ "SystemSignalLongSymbol" SG_ 1279 UI_energyLossTotalSinceCharge_ep "UI_energyLossTotalSinceCharge_epa";
BA_ "Confidence" SG_ 1279 UI_energyLossDrivingSinceCharge_ 0;
BA_ "SystemSignalLongSymbol" SG_ 1279 UI_energyLossDrivingSinceCharge_ "UI_energyLossDrivingSinceCharge_epa";
BA_ "Confidence" SG_ 1279 UI_energyLossClimateSinceCharge_ 0;
BA_ "SystemSignalLongSymbol" SG_ 1279 UI_energyLossClimateSinceCharge_ "UI_energyLossClimateSinceCharge_epa";
BA_ "Confidence" SG_ 1279 UI_energyLossBattCondSinceCharge 0;
BA_ "SystemSignalLongSymbol" SG_ 1279 UI_energyLossBattCondSinceCharge "UI_energyLossBattCondSinceCharge_epa";
BA_ "Confidence" SG_ 1279 UI_energyLossElevationSinceCharg 0;
BA_ "SystemSignalLongSymbol" SG_ 1279 UI_energyLossElevationSinceCharg "UI_energyLossElevationSinceCharge_epa";
BA_ "Confidence" SG_ 1279 UI_energyLossAccSinceCharge_epa 0;
BA_ "Confidence" SG_ 1279 UI_energyLossTotalSinceTripStart 0;
BA_ "Confidence" SG_ 1279 UI_energyLossDrivingSinceTripSta 0;
BA_ "SystemSignalLongSymbol" SG_ 1279 UI_energyLossDrivingSinceTripSta "UI_energyLossDrivingSinceTripStart";
BA_ "Confidence" SG_ 1279 UI_energyLossClimateSinceTripSta 0;
BA_ "SystemSignalLongSymbol" SG_ 1279 UI_energyLossClimateSinceTripSta "UI_energyLossClimateSinceTripStart";
BA_ "Confidence" SG_ 1279 UI_energyLossBattCondSinceTripSt 0;
BA_ "SystemSignalLongSymbol" SG_ 1279 UI_energyLossBattCondSinceTripSt "UI_energyLossBattCondSinceTripStart";
BA_ "Confidence" SG_ 1279 UI_energyLossElevationSinceTripS 0;
BA_ "SystemSignalLongSymbol" SG_ 1279 UI_energyLossElevationSinceTripS "UI_energyLossElevationSinceTripStart";
BA_ "Confidence" SG_ 1279 UI_energyLossAccSinceTripStart 0;
BA_ "Confidence" SG_ 1279 UI_energyDeltaTotal_epa 0;
BA_ "Confidence" SG_ 1279 UI_energyDeltaDriving_epa 0;
BA_ "Confidence" SG_ 1279 UI_energyDeltaClimate_epa 0;
BA_ "Confidence" SG_ 1279 UI_energyDeltaBattCond_epa 0;
BA_ "Confidence" SG_ 1279 UI_energyDeltaElevation_epa 0;
BA_ "Confidence" SG_ 1279 UI_energyDeltaAcc_epa 0;
BA_ "Confidence" SG_ 1279 UI_uiDeltaOffsetTotal_epa 0;
BA_ "Confidence" SG_ 1279 UI_uiDeltaOffsetDriving_epa 0;
BA_ "Confidence" SG_ 1279 UI_uiDeltaOffsetClimate_epa 0;
BA_ "Confidence" SG_ 1279 UI_uiDeltaOffsetBattCond_epa 0;
BA_ "Confidence" SG_ 1279 UI_uiDeltaOffsetElevation_epa 0;
BA_ "Confidence" SG_ 1279 UI_uiDeltaOffsetAcc_epa 0;
BA_ "Confidence" SG_ 1279 UI_rawToUiEnergyRatio_epa 0;
BA_ "Confidence" SG_ 1279 UI_driveDistance_epa 0;
BA_ "Confidence" SG_ 1279 UI_energyDeltaTotalSinceCharge_e 0;
BA_ "SystemSignalLongSymbol" SG_ 1279 UI_energyDeltaTotalSinceCharge_e "UI_energyDeltaTotalSinceCharge_epa";
BA_ "Confidence" SG_ 1279 UI_energyDeltaDrivingSinceCharge 0;
BA_ "SystemSignalLongSymbol" SG_ 1279 UI_energyDeltaDrivingSinceCharge "UI_energyDeltaDrivingSinceCharge_epa";
BA_ "Confidence" SG_ 1279 UI_energyDeltaClimateSinceCharge 0;
BA_ "SystemSignalLongSymbol" SG_ 1279 UI_energyDeltaClimateSinceCharge "UI_energyDeltaClimateSinceCharge_epa";
BA_ "Confidence" SG_ 1279 UI_energyDeltaBattCondSinceCharg 0;
BA_ "SystemSignalLongSymbol" SG_ 1279 UI_energyDeltaBattCondSinceCharg "UI_energyDeltaBattCondSinceCharge_epa";
BA_ "Confidence" SG_ 1279 UI_energyDeltaElevationSinceChar 0;
BA_ "SystemSignalLongSymbol" SG_ 1279 UI_energyDeltaElevationSinceChar "UI_energyDeltaElevationSinceCharge_epa";
BA_ "Confidence" SG_ 1279 UI_energyDeltaAccSinceCharge_epa 0;
BA_ "Confidence" SG_ 1279 UI_uiDeltaOffsetTotalSinceCharge 0;
BA_ "SystemSignalLongSymbol" SG_ 1279 UI_uiDeltaOffsetTotalSinceCharge "UI_uiDeltaOffsetTotalSinceCharge_epa";
BA_ "Confidence" SG_ 1279 UI_uiDeltaOffsetDrivingSinceChar 0;
BA_ "SystemSignalLongSymbol" SG_ 1279 UI_uiDeltaOffsetDrivingSinceChar "UI_uiDeltaOffsetDrivingSinceCharge_epa";
BA_ "Confidence" SG_ 1279 UI_uiDeltaOffsetClimateSinceChar 0;
BA_ "SystemSignalLongSymbol" SG_ 1279 UI_uiDeltaOffsetClimateSinceChar "UI_uiDeltaOffsetClimateSinceCharge_epa";
BA_ "Confidence" SG_ 1279 UI_uiDeltaOffsetBattCondSinceCha 0;
BA_ "SystemSignalLongSymbol" SG_ 1279 UI_uiDeltaOffsetBattCondSinceCha "UI_uiDeltaOffsetBattCondSinceCharge_epa";
BA_ "Confidence" SG_ 1279 UI_uiDeltaOffsetElevationSinceCh 0;
BA_ "SystemSignalLongSymbol" SG_ 1279 UI_uiDeltaOffsetElevationSinceCh "UI_uiDeltaOffsetElevationSinceCharge_epa";
BA_ "Confidence" SG_ 1279 UI_uiDeltaOffsetAccSinceCharge_e 0;
BA_ "SystemSignalLongSymbol" SG_ 1279 UI_uiDeltaOffsetAccSinceCharge_e "UI_uiDeltaOffsetAccSinceCharge_epa";
BA_ "Confidence" SG_ 1279 UI_rawToUiEnergyRatioSinceCharge 0;
BA_ "SystemSignalLongSymbol" SG_ 1279 UI_rawToUiEnergyRatioSinceCharge "UI_rawToUiEnergyRatioSinceCharge_epa";
BA_ "Confidence" SG_ 1279 UI_driveDistanceSinceCharge_epa 0;
BA_ "Confidence" SG_ 1279 UI_energyDeltaTotalSinceTripStar 0;
BA_ "SystemSignalLongSymbol" SG_ 1279 UI_energyDeltaTotalSinceTripStar "UI_energyDeltaTotalSinceTripStart";
BA_ "Confidence" SG_ 1279 UI_energyDeltaDrivingSinceTripSt 0;
BA_ "SystemSignalLongSymbol" SG_ 1279 UI_energyDeltaDrivingSinceTripSt "UI_energyDeltaDrivingSinceTripStart";
BA_ "Confidence" SG_ 1279 UI_energyDeltaClimateSinceTripSt 0;
BA_ "SystemSignalLongSymbol" SG_ 1279 UI_energyDeltaClimateSinceTripSt "UI_energyDeltaClimateSinceTripStart";
BA_ "Confidence" SG_ 1279 UI_energyDeltaBattCondSinceTripS 0;
BA_ "SystemSignalLongSymbol" SG_ 1279 UI_energyDeltaBattCondSinceTripS "UI_energyDeltaBattCondSinceTripStart";
BA_ "Confidence" SG_ 1279 UI_energyDeltaElevationSinceTrip 0;
BA_ "SystemSignalLongSymbol" SG_ 1279 UI_energyDeltaElevationSinceTrip "UI_energyDeltaElevationSinceTripStart";
BA_ "Confidence" SG_ 1279 UI_energyDeltaAccSinceTripStart 0;
BA_ "Confidence" SG_ 1279 UI_uiDeltaOffsetTotalSinceTripSt 0;
BA_ "SystemSignalLongSymbol" SG_ 1279 UI_uiDeltaOffsetTotalSinceTripSt "UI_uiDeltaOffsetTotalSinceTripStart";
BA_ "Confidence" SG_ 1279 UI_uiDeltaOffsetDrivingSinceTrip 0;
BA_ "SystemSignalLongSymbol" SG_ 1279 UI_uiDeltaOffsetDrivingSinceTrip "UI_uiDeltaOffsetDrivingSinceTripStart";
BA_ "Confidence" SG_ 1279 UI_uiDeltaOffsetClimateSinceTrip 0;
BA_ "SystemSignalLongSymbol" SG_ 1279 UI_uiDeltaOffsetClimateSinceTrip "UI_uiDeltaOffsetClimateSinceTripStart";
BA_ "Confidence" SG_ 1279 UI_uiDeltaOffsetBattCondSinceTri 0;
BA_ "SystemSignalLongSymbol" SG_ 1279 UI_uiDeltaOffsetBattCondSinceTri "UI_uiDeltaOffsetBattCondSinceTripStart";
BA_ "Confidence" SG_ 1279 UI_uiDeltaOffsetElevationSinceTr 0;
BA_ "SystemSignalLongSymbol" SG_ 1279 UI_uiDeltaOffsetElevationSinceTr "UI_uiDeltaOffsetElevationSinceTripStart";
BA_ "Confidence" SG_ 1279 UI_uiDeltaOffsetAccSinceTripStar 0;
BA_ "SystemSignalLongSymbol" SG_ 1279 UI_uiDeltaOffsetAccSinceTripStar "UI_uiDeltaOffsetAccSinceTripStart";
BA_ "Confidence" SG_ 1279 UI_rawToUiEnergyRatioSinceTripSt 0;
BA_ "SystemSignalLongSymbol" SG_ 1279 UI_rawToUiEnergyRatioSinceTripSt "UI_rawToUiEnergyRatioSinceTripStart";
BA_ "Confidence" SG_ 1279 UI_driveDistanceSinceTripStart 0;
BA_ "Confidence" SG_ 1279 UI_trailerMass 0;
BA_ "Confidence" SG_ 993 UI_gearSliderInfoIndex 1;
BA_ "Confidence" SG_ 563 UI_gearRequest 0;
BA_ "GenSigSNA" SG_ 563 UI_gearRequest "0";
BA_ "Confidence" SG_ 563 UI_autopilotRequest 1;
BA_ "Confidence" SG_ 563 UI_gearStripShowing 0;
BA_ "Confidence" SG_ 563 UI_gearStripLocation 1;
BA_ "Confidence" SG_ 563 UI_gearStripForceShow 0;
BA_ "Confidence" SG_ 563 UI_autoParkAvailable 0;
BA_ "Confidence" SG_ 563 UI_gearStripSuppressActive 0;
BA_ "Confidence" SG_ 563 UI_gearNeutralPressed 0;
BA_ "Confidence" SG_ 986 UI_wifiRegDomain 0;
BA_ "Confidence" SG_ 986 UI_wifiTethered 0;
BA_ "Confidence" SG_ 661 UI_systemMonitorIndex 1;
BA_ "Confidence" SG_ 661 UI_SystemMemUsage 0;
BA_ "Confidence" SG_ 661 UI_QtCarMemUsage 0;
BA_ "Confidence" SG_ 661 UI_QtCarCPUUsage 0;
BA_ "Confidence" SG_ 661 UI_SystemCPUUsage 0;
BA_ "Confidence" SG_ 1263 UI_fwHeatOnNavArrivalSOE 0;
BA_ "Confidence" SG_ 1263 UI_voyagerHeatOnNavArrivalSOE 0;
BA_ "Confidence" SG_ 139 UI_maxSpeedToReachDestination 0;
BA_ "GenSigSNA" SG_ 139 UI_maxSpeedToReachDestination "65535";
BA_ "Confidence" SG_ 139 UI_remainingWeightedRMSSpeed 1;
BA_ "GenSigSNA" SG_ 139 UI_remainingWeightedRMSSpeed "65535";
BA_ "Confidence" SG_ 139 UI_timeToDestination 0;
BA_ "GenSigSNA" SG_ 139 UI_timeToDestination "65535";
BA_ "Confidence" SG_ 1173 UI_predictedEnergy 0;
BA_ "GenSigSNA" SG_ 1173 UI_predictedEnergy "32768";
BA_ "Confidence" SG_ 1173 UI_predictedEnergyLearned 1;
BA_ "GenSigSNA" SG_ 1173 UI_predictedEnergyLearned "32768";
BA_ "Confidence" SG_ 1173 UI_hindsightEnergy 0;
BA_ "GenSigSNA" SG_ 1173 UI_hindsightEnergy "32768";
BA_ "Confidence" SG_ 1173 UI_hindsightEnergyLearned 1;
BA_ "GenSigSNA" SG_ 1173 UI_hindsightEnergyLearned "32768";
BA_ "Confidence" SG_ 1174 UI_longTermEnergyModelError 1;
BA_ "GenSigSNA" SG_ 1174 UI_longTermEnergyModelError "128";
BA_ "Confidence" SG_ 1174 UI_longTermRmsSpeedRatio 1;
BA_ "GenSigSNA" SG_ 1174 UI_longTermRmsSpeedRatio "255";
BA_ "Confidence" SG_ 1174 UI_gradeCorrectedEnergy 1;
BA_ "GenSigSNA" SG_ 1174 UI_gradeCorrectedEnergy "32768";
BA_ "Confidence" SG_ 1174 UI_gradeCorrectedEnergyLearned 1;
BA_ "GenSigSNA" SG_ 1174 UI_gradeCorrectedEnergyLearned "32768";
BA_ "Confidence" SG_ 1175 UI_battPreconditionOnNavTime 1;
BA_ "GenSigSNA" SG_ 1175 UI_battPreconditionOnNavTime "65535";
BA_ "Confidence" SG_ 1175 UI_maxBattPreconditionOnNavTime 1;
BA_ "GenSigSNA" SG_ 1175 UI_maxBattPreconditionOnNavTime "65535";
BA_ "Confidence" SG_ 649 VCLEFT_logging10HzIndex 1;
BA_ "Confidence" SG_ 649 VCLEFT_hvacBlowerRs 0;
BA_ "GenSigSNA" SG_ 649 VCLEFT_hvacBlowerRs "255";
BA_ "Confidence" SG_ 649 VCLEFT_hvacBlowerIPhase0 0;
BA_ "GenSigSNA" SG_ 649 VCLEFT_hvacBlowerIPhase0 "127";
BA_ "Confidence" SG_ 649 VCLEFT_hvacBlowerIPhase1 0;
BA_ "GenSigSNA" SG_ 649 VCLEFT_hvacBlowerIPhase1 "127";
BA_ "Confidence" SG_ 649 VCLEFT_hvacBlowerIPhase2 0;
BA_ "GenSigSNA" SG_ 649 VCLEFT_hvacBlowerIPhase2 "127";
BA_ "Confidence" SG_ 649 VCLEFT_hvacBlower_IO_CBC_HEAD 0;
BA_ "Confidence" SG_ 649 VCLEFT_hvacBlower_IO_CBC_TAIL 0;
BA_ "Confidence" SG_ 649 VCLEFT_hvacBlower_IO_CBC_TAIL_va 0;
BA_ "SystemSignalLongSymbol" SG_ 649 VCLEFT_hvacBlower_IO_CBC_TAIL_va "VCLEFT_hvacBlower_IO_CBC_TAIL_valid";
BA_ "Confidence" SG_ 649 VCLEFT_hvacBlower_IO_CBC_Status 0;
BA_ "Confidence" SG_ 649 VCLEFT_hvacBlower_IO_CBC_numUart 0;
BA_ "SystemSignalLongSymbol" SG_ 649 VCLEFT_hvacBlower_IO_CBC_numUart "VCLEFT_hvacBlower_IO_CBC_numUartErr";
BA_ "Confidence" SG_ 649 VCLEFT_hvacBlowerCBCEstState 0;
BA_ "Confidence" SG_ 649 VCLEFT_hvacBlowerCBCCtrlState 0;
BA_ "Confidence" SG_ 649 VCLEFT_hvacBlowerITerm 0;
BA_ "GenSigSNA" SG_ 649 VCLEFT_hvacBlowerITerm "127";
BA_ "Confidence" SG_ 649 VCLEFT_hvacBlowerSpiError 0;
BA_ "Confidence" SG_ 649 VCLEFT_hvacBlowerRsOnlineActive 0;
VAL_ 979 UI_airbagCutoffSwState 2 "SNA" 1 "PASSENGER_AIRBAG_OFF" 0 "PASSENGER_AIRBAG_ON" ;
VAL_ 979 UI_warningIndicatorStatus 3 "SNA" 1 "WARNING_LAMP_ON" 0 "WARNING_LAMP_OFF" ;
VAL_ 1523 UI_alertID 278 "a278_gpsHwDegraded" 277 "a277_PONRPopupShown" 276 "a276_PrivateNetworkProfileActive" 275 "a275_ADDWFaulted" 274 "a274_ContextualHintCardEvent" 273 "a273_AudioDbusFailure" 272 "a272_eapTlsCSRFailure" 266 "a266_DashcamRecentBufferDurationReduced" 265 "a265_USBHostControllerUnrecoverable" 264 "a264_invalidEpaRange" 263 "a263_ecuLogUploadFailure" 261 "a261_bluetoothStackPanic" 260 "a260_sapWrongChannel" 259 "a259_sapChannelMismatch" 258 "a258_sapFailedToPowerOn" 257 "a257_modemRebooting" 256 "a256_sapFailedToEnable" 255 "a255_apbCertificateExpired" 254 "a254_appCertificateExpired" 253 "a253_maintenanceHistoryRecorded" 252 "a252_TPMErrorReceive" 247 "a247_StalklessDisplayBacklightFailure" 246 "a246_gpuFenceTimeout" 245 "a245_taskHung" 244 "a244_segfault" 243 "a243_pmDisplayCheckFailure" 242 "a242_uiHealthFaultInjectionActive" 241 "a241_AxCPError" 240 "a240_ethError" 238 "a238_ModemConfigMismatch" 237 "a237_ClipUploadActive" 236 "a236_ModemOnResetState" 235 "a235_AMDI2C1Timeout" 234 "a234_AMDI2C0Timeout" 233 "a233_ModemRFFailure" 232 "a232_processExitError" 231 "a231_SleepCancelled" 230 "a230_ModemSimCardMismatch" 229 "a229_SerDesError" 228 "a228_pipewireXrunBurst" 226 "a226_largePhoneContactSync" 225 "a225_clusterDisplayDisconnected" 224 "a224_centerDisplayDisconnected" 223 "a223_databaseError" 222 "a222_QtCarRestart" 221 "a221_NavigationServiceError" 220 "a220_MediaBrowseError" 219 "a219_CompositorWatchdog" 218 "a218_AudiodNoAudioDevices" 217 "a217_CgroupMemoryPressure" 216 "a216_AudioA2bCircuitProblem" 215 "a215_compositorStallDetected" 214 "a214_pmHelperFailure" 213 "a213_ISADisabled" 212 "a212_AEBSFaulted" 211 "a211_AEBSDisabled" 210 "a210_CellularCSRegFail" 209 "a209_dataCallDisconnected" 208 "a208_mqttClientDisconnected" 206 "a206_ModemMIAAfterWake" 205 "a205_ModemSleepSignalMismatch" 204 "a204_ModemSleepFailure" 202 "a202_sysMemoryIncorrect" 201 "a201_rearDisplayDisconnected" 200 "a200_UIFirmwareVersionMismatch" 199 "a199_HighAPedalDetectedAtCollision" 198 "a198_IncompatibleBTUSBHubHardware" 197 "a197_AMDI2C1BusInoperable" 196 "a196_AMDI2C3BusInoperable" 195 "a195_gtwMfdUdpApiFired" 194 "a194_AudioweaverRestarted" 193 "a193_TcuRNandFwVersionMismatch" 192 "a192_AudioWatchdogReboot" 191 "a191_TunerUpdateFailed" 190 "a190_TunerMIA" 189 "a189_TunerWatchdogReset" 188 "a188_TunerFirmwareMismatchedAPI" 187 "a187_TunerFirmwareMismatchedVersion" 186 "a186_ELKSUnavailable" 185 "a185_ELKSDisabled" 184 "a184_ISAFaulted" 183 "a183_DDAWFaulted" 182 "a182_VideoPipelineOverrun" 181 "a181_ModemFirmwareVersionMismatch" 180 "a180_AudiodInputRestarted" 178 "a178_irqDisabled" 177 "a177_MediaPlayerFailure" 176 "a176_CellularAntennaAlert" 174 "a174_HistorySaveLoop" 173 "a173_pmSuspendFailure" 172 "a172_GraphicsLoadShedUIFailure" 171 "a171_GraphicsLoadShedRequested" 170 "a170_AMDdGPULoadShedFailure" 169 "a169_SteamLoadShedFailure" 168 "a168_dgpuPowerOnSelfTestFailure" 167 "a167_CgroupOverMemKill" 166 "a166_fsError" 165 "a165_fsCorrupted" 164 "a164_AudiodConnTimeout" 163 "a163_QtCarVehicleExitError" 162 "a162_voiceRecClipsUploaded" 161 "a161_ECallTemporarilyUnavailable" 160 "a160_SystemWatchdogFailure" 159 "a159_AudioHeartbeatFailure" 158 "a158_UsbDeviceMountError" 157 "a157_MCUActiveCoolingRequested" 156 "a156_UsbFrontHubInstallMismatch" 155 "a155_UsbFrontHubUnavailable" 154 "a154_AudiodBufferError" 153 "a153_serviceRestarted" 152 "a152_infoThrottling" 151 "a151_carComputerThermalProblem" 150 "a150_infoCPURunningHot" 149 "a149_DisplayCheckFailure" 148 "a148_SleepFailure" 147 "a147_ASILGlobalError" 146 "a146_nvmeNeedsReplacement" 145 "a145_nvmeUnsafeShutdown" 144 "a144_nvmeWarning" 143 "a143_FPSCrawling" 142 "a142_CorrectableMemoryError" 141 "a141_falconDoorOpen" 140 "a140_NeverSleepActive" 139 "a139_postponedConfigChange" 138 "a138_applyingConfigChange" 137 "a137_ServiceShellActiveConnection" 136 "a136_warnSettingsConfExists" 135 "a135_warnRunOverlayExists" 134 "a134_DashcamUsbDriveNoMedium" 133 "a133_AdspWatchdogRecoveryFailed" 132 "a132_AdspWatchdogRecoveryTriggered" 131 "a131_DisplayPortFailure" 130 "a130_QtCarClusterExitError" 129 "a129_dgpuOperationFailure" 128 "a128_dgpuNotDetected" 126 "a126_UsbErrorDriveCorrupt" 125 "a125_AMDI2C1TxRxAborted" 124 "a124_AMDI2C0TxRxAborted" 123 "a123_AMDI2C1LostArbitration" 122 "a122_AMDI2C0LostArbitration" 121 "a121_nvmeSmartLogCritical" 120 "a120_nvmePCIeLinkErrorDetected" 119 "a119_nvmeBlockDeviceMissing" 118 "a118_NVMeReset" 117 "a117_VehicleSelfTestRunning" 116 "a116_UncorrectableMemoryError" 115 "a115_IrisEDLMode" 114 "a114_drivingVisualizationDegraded" 113 "a113_DashcamHasOnboardSentryClips" 112 "a112_badUSBDevice" 111 "a111_DashcamUsbDriveNotSuperSpeed" 110 "a110_DashcamUsbDriveCorrupt" 109 "a109_DashcamUsbDriveTooSmall" 108 "a108_DashcamUsbDriveGettingFull" 107 "a107_DashcamUsbDriveTooBigForVfatFsck" 106 "a106_rebootBackstopTriggered" 105 "a105_firmwareReinstallRequested" 104 "a104_DashcamUsbDriveMissing" 103 "a103_UsbHubNotEnumerating" 102 "a102_A2bDiscoveryFailed" 101 "a101_wifiStackProblem" 100 "a100_eMMCFTLError" 99 "a099_eMMCStatusError" 98 "a098_DiskCheckFailure" 97 "a097_AudiodRestarted" 96 "a096_VideodPipelineIssueDetected" 95 "a095_CidStorageRunningLow" 94 "a094_ModemPowerOnFailure" 93 "a093_updateEnded" 92 "a092_updateStarted" 91 "a091_VehicleLinkStall" 90 "a090_RadioPingFailError" 89 "a089_RadioReset" 88 "a088_CellRemovableSimMissing" 87 "a087_BmpReset" 86 "a086_TouchEnumerationError" 85 "a085_DeserializerError" 84 "a084_SerializerError" 83 "a083_ECallProxyWatchdogTriggered" 82 "a082_NumModemRebootStuckInECall" 81 "a081_CellModemSearchExpired" 80 "a080_DashcamUsbDriveSlow" 79 "a079_DashcamUsbDriveFull" 78 "a078_DashcamUsbDriveUnmountable" 77 "a077_AudioA2bMicChannelSwap" 76 "a076_NumFalseManualECalls" 75 "a075_BackupCameraInitError" 74 "a074_EMMCHangDetected" 73 "a073_ECallDigitalMicFailed" 72 "a072_ECallAnalogMicFailed" 71 "a071_VideoPipelineError" 70 "a070_VideoPipelineWarning" 69 "a069_VideoUDPTimeout" 68 "a068_VideoUnexpectedExit" 67 "a067_WarnOnI915" 66 "a066_GpuHangDetected" 65 "a065_WiFiRecoveryReset" 64 "a064_ModemFirmwareTestFailed" 63 "a063_CellularTestFailed" 62 "a062_ENSTestFailed" 61 "a061_SIMTestFailed" 60 "a060_ECallMicDisconnected" 59 "a059_ECallSpeakerDisconnected" 58 "a058_GPSAntennaDisconnected" 57 "a057_CellAntennaDisconnected" 56 "a056_ManualECallButtonDisconnected" 55 "a055_ManualECallDisabled" 54 "a054_AudioBoostPowerBad" 53 "a053_QtCarExitError" 52 "a052_KernelPanicReported" 51 "a051_BackupCameraFrameTimeout" 50 "a050_BackupCameraIPUTimeout" 49 "a049_BrakeShiftRequired" 48 "a048_AudioPremiumAmpCheckFailed" 47 "a047_CellRoamingDisallowed" 46 "a046_BackupCameraStreamError" 45 "a045_ECallSystemCheckFailed" 44 "a044_AudioDmesgDspException" 43 "a043_InvalidMapDataOverride" 42 "a042_AudioDmesgRtThrottling" 41 "a041_AudioDmesgXrun" 40 "a040_HomelinkTransmit" 39 "a039_AudioA2bNeedRediscovery" 38 "a038_AudioWatchdogA2bI2cLockupError" 37 "a037_AudioWatchdogXrunStormError" 36 "a036_AudioWatchdog" 35 "a035_FrunkOpenChime" 34 "a034_WakeupProblem" 33 "a033_ApTrialExpired" 32 "a032_CellModemRecoveryResets" 31 "a031_BrakeFluidLow" 30 "a030_ModemVMCrash" 29 "a029_ModemMIA" 28 "a028_FrontTrunkPopupClosed" 27 "a027_AutoSteerMIA" 26 "a026_ModemResetLoopDetected" 24 "a024_WifiInternetCheckFailed" 23 "a023_CellInternetCheckFailed" 22 "a022_ApeFusesEtc" 21 "a021_RearSeatbeltUnbuckled" 20 "a020_SteeringReduced" 19 "a019_ParkBrakeFault" 18 "a018_SlipStartOn" 17 "a017_TPMSSystemFault" 16 "a016_TPMSTemperatureWarning" 15 "a015_TPMSOverPressureWarning" 14 "a014_TPMSSoftWarning" 13 "a013_TPMSHardWarning" 12 "a012_NotOnPrivateProperty" 11 "a011_IncorrectMap" 10 "a010_MapsMissing" 9 "a009_SquashfsError" 8 "a008_TouchScreenError" 7 "a007_SoftPackConfigMismatch" 6 "a006_RemoteServiceAlert" 5 "a005_HeadlightsOnDoorOpen" 4 "a004_FrunkOpen" 3 "a003_TrunkOpen" 2 "a002_DoorOpen" 1 "a001_DriverDoorOpen" 0 "ALERT_DO_NOT_USE_ZERO" ;
VAL_ 1523 UI_alertState 1 "SET" 0 "CLEARED" ;
VAL_ 1523 UI_a009_squashfsDevice 9 "FS_ROOTFS" 8 "FS_TSLA_VAR" 7 "FS_BMAP" 6 "FS_AMAP" 5 "FS_HOME" 4 "FS_APPS_USR" 3 "FS_APPS_VAR" 2 "FS_VAR" 1 "FS_LOG" 0 "Unknown" ;
VAL_ 1523 UI_a036_audioWatchdogReason 5 "EXCEPTION_DETECTED" 4 "TDA7802_CANNOT_CONFIGURE_AMP" 3 "TDA7802_CANNOT_OPEN_CODEC_NEG_110" 2 "IPC_DELETE_PIPELINE_FAILED_NEG_110" 1 "IPC_SET_DX_FAILED_NEG_110" 0 "DISABLING_IRQ_NUM_25" ;
VAL_ 1523 UI_a087_BmpResetType 5 "WATCHDOG" 4 "POWER_ON" 3 "WARM" 2 "COLD" 1 "GLOBAL" 0 "UNKNOWN" ;
VAL_ 1523 UI_a131_DisplayPortFailureType 1 "DPCD_READ_FAILURE" 0 "UNKNOWN_LANE_TRAIN_FAILURE" ;
VAL_ 1523 UI_a147_whichASIL 1 "A" 0 "B" ;
VAL_ 1523 UI_a147_errorCode 24 "TOUCH_PLL_WATCHDOG" 23 "DISPLAY_PLL_WATCHDOG" 22 "PANEL_BROKEN" 21 "FLASH_CRC" 20 "LVDS_FAIL_SAFE" 19 "LVDS_DLL_LOCK" 18 "NO_HS_DE" 17 "NO_VS" 16 "NO_CLOCK" 15 "SOURCE" 14 "GATE" 13 "OVER_TEMP" 12 "VGL_OVD" 11 "VGH_OVD" 10 "AVEE_OVD" 9 "AVVD_OVD" 8 "VCOM_OVD" 7 "VDDI_OVD" 6 "VGL_LVD" 5 "VGH_LVD" 4 "AVEE_LVD" 3 "AVDD_LVD" 2 "VCOM_LVD" 1 "VDDI_LVD" 0 "UNKNOWN" ;
VAL_ 1523 UI_a148_sleepType 4 "Unknown" 3 "ModernStandby" 2 "S2Idle" 1 "S3" 0 "Shallow" ;
VAL_ 1523 UI_a148_lastFailedPmSuspendDev 18 "Timesync" 17 "LED" 16 "Button" 15 "NVME" 14 "Hermes" 13 "Cameras" 12 "Modem" 11 "Bluetooth" 10 "Wifi" 9 "USB" 8 "Audio" 7 "BluetoothRear" 6 "DGPU" 5 "Post" 4 "Memory" 3 "UsbMsd" 2 "Steam" 1 "Unknown" 0 "None" ;
VAL_ 1523 UI_a149_displayType 9 "MY_DP_P103" 8 "CT_DP_185" 7 "M3_DP_P882" 6 "SX_HDMI_R94" 5 "M3_HDMI_E2X" 4 "M3_HDMI_P88" 3 "SX_HDMI_8" 2 "SX_HDMI_11" 1 "SX_DP_17" 0 "Unknown" ;
VAL_ 1523 UI_a149_displaySeat 3 "Rear" 2 "Cluster" 1 "Center" 0 "Unknown" ;
VAL_ 1523 UI_a149_errorCode 21 "UnknownDisplay" 20 "EdidRead" 19 "EepromRead" 18 "I2CRebootRequested" 17 "HDMIFrequencyChanged" 16 "ASILStatusFault" 15 "OsdCrcFailedToEnable" 14 "OsdCrcI2CReadWriteFailure" 13 "OsdCrcSecondaryTconMismatch" 12 "OsdCrcMainTconMismatch" 11 "PowerControl" 10 "TouchStatus" 9 "GammaControl" 8 "GatewayWedged" 7 "ResetFailure" 6 "SerDesLink" 5 "LaneTraining" 4 "BacklightEnumeration" 3 "BacklightMismatch" 2 "BacklightPower" 1 "BacklightControl" 0 "Unknown" ;
VAL_ 1523 UI_a153_processName 13 "QTCAR" 12 "QTCAR_ACCOUNTMANAGER" 11 "QTCAR_AUDIOD" 10 "QTCAR_BLUETOOTH" 9 "QTCAR_CARSERVER" 8 "QTCAR_CLUSTER" 7 "QTCAR_CONNMAN" 6 "QTCAR_EVLOGSERVICE" 5 "QTCAR_GPSMANAGER" 4 "QTCAR_MEDIASERVER" 3 "QTCAR_SPEECH_RECOGNIZER" 2 "QTCAR_SPOTIFYSERVER" 1 "QTCAR_VEHICLE" 0 "UNKNOWN" ;
VAL_ 1523 UI_a153_restartReason 3 "OVER_MEM" 2 "DEAD" 1 "LOST_SHARED_MEM" 0 "UNKNOWN" ;
VAL_ 1523 UI_a158_UsbDeviceMountErrorCode 30 "READ_ONLY_FILE_SYSTEM" 22 "INVALID_ARGUMENT" 19 "NO_SUCH_DEVICE" 16 "DEVICE_OR_RESOURCE_BUSY" 13 "PERMISSION_DENIED" 12 "OUT_OF_MEMORY" 6 "NO_SUCH_DEVICE_OR_ADDRESS" 5 "IO_ERROR" 2 "NO_SUCH_FILE_OR_DIRECTORY" ;
VAL_ 1523 UI_a165_fsCorruptedDevice 9 "FS_ROOTFS" 8 "FS_TSLA_VAR" 7 "FS_BMAP" 6 "FS_AMAP" 5 "FS_HOME" 4 "FS_APPS_USR" 3 "FS_APPS_VAR" 2 "FS_VAR" 1 "FS_LOG" 0 "Unknown" ;
VAL_ 1523 UI_a166_fsErrorDevice 9 "FS_ROOTFS" 8 "FS_TSLA_VAR" 7 "FS_BMAP" 6 "FS_AMAP" 5 "FS_HOME" 4 "FS_APPS_USR" 3 "FS_APPS_VAR" 2 "FS_VAR" 1 "FS_LOG" 0 "Unknown" ;
VAL_ 1523 UI_a167_processId 27 "unreal_apviz_mem" 26 "infoz_temp_monitor" 25 "alertd" 24 "tunaman" 23 "hermes_log" 22 "thermald" 21 "apviz_assetgen_mem" 20 "apviz_controls_mem" 19 "apviz_mem" 18 "dashcam_viewer" 17 "qtcar_radioserver" 16 "mediaserver" 15 "hermes_fleet_streaming" 14 "hermes_dynamic_triggers" 13 "chromium_odin" 12 "chromium_odin_gpu" 11 "chromium_app" 10 "chromium_app_gpu" 9 "chromium_fullscreen" 8 "chromium_fullscreen_gpu" 7 "chromium" 6 "chromium_gpu" 5 "valhalla_server" 4 "QtCarSpeechReco" 3 "QtCarGpsManager" 2 "QtCarTMServer" 1 "QtCar" 0 "Unknown" ;
VAL_ 1523 UI_a173_errorCode 2 "MODEM" 1 "RESERVED" 0 "NONE" ;
VAL_ 1523 UI_a173_lastFailedPmSuspendDev 18 "Timesync" 17 "LED" 16 "Button" 15 "NVME" 14 "Hermes" 13 "Cameras" 12 "Modem" 11 "Bluetooth" 10 "Wifi" 9 "USB" 8 "Audio" 7 "BluetoothRear" 6 "DGPU" 5 "Post" 4 "Memory" 3 "UsbMsd" 2 "Steam" 1 "Unknown" 0 "None" ;
VAL_ 1523 UI_a176_PrimaryAntenna 5 "SHORTED" 4 "OPEN" 3 "NORMAL" 2 "UNKNOWN" 1 "NOT_POWERED" 0 "INITIALIZING" ;
VAL_ 1523 UI_a176_SecondaryAntenna 5 "SHORTED" 4 "OPEN" 3 "NORMAL" 2 "UNKNOWN" 1 "NOT_POWERED" 0 "INITIALIZING" ;
VAL_ 1523 UI_a176_TertiaryAntenna 5 "SHORTED" 4 "OPEN" 3 "NORMAL" 2 "UNKNOWN" 1 "NOT_POWERED" 0 "INITIALIZING" ;
VAL_ 1523 UI_a177_errorCode 18 "LICENSE_ERROR" 17 "WIDEVINE_CDM_EXPIRED" 16 "ACTIVE_PHONE_CALL" 15 "PLAYBACK_ERROR" 14 "WIFI_REQUIRED" 13 "UNSPECIFIED_ERROR" 12 "PLAYING_ON_ANOTHER_DEVICE" 11 "FAILED_TO_LOAD_TRACKS" 10 "INVALID_STREAM" 9 "INVALID_URL" 8 "EXPLICIT_CONTENT" 7 "STREAMING_DISABLED" 6 "NO_RESPONSE_FROM_MEDIA_SERVER" 5 "BITRATE_TOO_HIGH" 4 "NO_INTERNET" 3 "NETWORK_ERROR" 2 "NO_STATION" 1 "NO_PLAYER" 0 "NO_ERROR" ;
VAL_ 1523 UI_a177_errorSource 39 "SODA_MUSIC" 38 "CARAOKE" 37 "KUGOU" 36 "YOUTUBE_MUSIC" 35 "YUNTING" 34 "AMAZON_MUSIC" 33 "AUDIBLE" 32 "APPLE_PODCASTS" 31 "APPLE_MUSIC" 30 "MINI_PROGRAMS" 29 "SEARCH" 28 "HOME_APPS" 27 "RECENTS_FAVORITES" 26 "TOYBOX" 25 "TUTORIAL" 24 "THEATER" 23 "BROWSER" 22 "GAME" 21 "NET_EASE_MUSIC" 20 "ONLINE_RADIO" 19 "XIMALAYA" 18 "QQ_MUSIC2" 17 "QQ_MUSIC1" 16 "TIDAL" 15 "SIRIUS_XM" 14 "STINGRAY" 13 "TUNE_IN" 12 "EU_RADIO" 11 "US_RADIO" 10 "SPOTIFY" 9 "SLACKER" 8 "BLUETOOTH" 7 "USB" 6 "DAB" 5 "XM" 4 "FM" 3 "AM" 2 "UNKNOWN" 1 "DEPRECATED" 0 "NONE" ;
VAL_ 1523 UI_a192_AudioRebootState 9 "REBOOTED_CRITICAL_KERNEL_ERROR" 8 "REBOOTED_KERNEL_ERROR" 7 "BLOCKED_REASON_CAR_NOT_PARKED" 6 "BLOCKED_REASON_REBOOT_TIME_EXPIRED" 5 "BLOCKED_REASON_REBOOT_COMMAND_FAILED" 4 "BLOCKED_REASON_SOFTWARE_UPDATE_IN_PROGRESS" 3 "BLOCKED_REASON_GATEWAY_UPDATE_IN_PROGRESS" 2 "BLOCKED_REASON_TOWING_MODE_REQUESTED" 1 "BLOCKED_REASON_AUDIO_POWER_ISSUE_DETECTED" 0 "BLOCKED_REASON_UNEXPECTED_AUDIO_STATE" ;
VAL_ 1523 UI_a204_ModemSleepFailureReason 5 "MODEM_FAILURE" 4 "ADSP_FAILURE" 3 "SLEEP_CANCELLED" 2 "ALREADY_ASLEEP" 1 "ETHERNET_FAILURE" 0 "NO_ERROR" ;
VAL_ 1523 UI_a214_lastFailedPmSuspendDev 18 "Timesync" 17 "LED" 16 "Button" 15 "NVME" 14 "Hermes" 13 "Cameras" 12 "Modem" 11 "Bluetooth" 10 "Wifi" 9 "USB" 8 "Audio" 7 "BluetoothRear" 6 "DGPU" 5 "Post" 4 "Memory" 3 "UsbMsd" 2 "Steam" 1 "Unknown" 0 "None" ;
VAL_ 1523 UI_a216_circuitProblem 42 "NON_LOCALIZED_SHORT_TO_VBAT" 41 "NON_LOCALIZED_SHORT_TO_GND" 15 "INDETERMINATE_FAULT" 13 "CABLE_REVERSE_CONNECTED" 12 "CABLE_DISCONNECTED_OR_OPEN_CIRCUIT" 11 "CABLE_SHORTED_TOGETHER" 10 "CABLE_SHORTED_TO_VBAT" 9 "CABLE_SHORTED_TO_GND" ;
VAL_ 1523 UI_a216_circuitNode 3 "UNKNOWN" 2 "AMP" 1 "MIC" 0 "MASTER" ;
VAL_ 1523 UI_a217_cgroupName 27 "unreal_apviz_mem" 26 "infoz_temp_monitor" 25 "alertd" 24 "tunaman" 23 "hermes_log" 22 "thermald" 21 "apviz_assetgen_mem" 20 "apviz_controls_mem" 19 "apviz_mem" 18 "dashcam_viewer" 17 "qtcar_radioserver" 16 "mediaserver" 15 "hermes_fleet_streaming" 14 "hermes_dynamic_triggers" 13 "chromium_odin" 12 "chromium_odin_gpu" 11 "chromium_app" 10 "chromium_app_gpu" 9 "chromium_fullscreen" 8 "chromium_fullscreen_gpu" 7 "chromium" 6 "chromium_gpu" 5 "valhalla_server" 4 "QtCarSpeechReco" 3 "QtCarGpsManager" 2 "QtCarTMServer" 1 "QtCar" 0 "Unknown" ;
VAL_ 1523 UI_a220_errorCode 11 "UPDATE_REQUIRED" 10 "CONTENT_BLOCKED" 9 "SERVICE_UNAVAILABLE" 8 "INTERNAL_SERVER_ERROR" 7 "TOO_MANY_REQUESTS" 6 "TIMEOUT" 5 "NOT_FOUND" 4 "FORBIDDEN" 3 "UNAUTHORIZED" 2 "BAD_REQUEST" 1 "INTERNAL_ERROR" 0 "NETWORK_ERROR" ;
VAL_ 1523 UI_a221_errorCode 12 "SERVER_ERROR" 11 "NETWORK_ERROR" 10 "SIMULATE_NAV_SERVICE_FAILURE" 9 "PARSE_VALHALLA_ATTRIBUTES_FAILURE" 8 "MAP_OVERRIDE_ERROR" 7 "NO_ROUTE_ERROR" 6 "PARSE_GRPC_ERROR" 5 "VOYAGER_TRIP_PLAN_NOT_POSSIBLE_ERROR" 4 "RESPONSE_STATUS_ERROR" 3 "INCOMPLETE_RESPONSE" 2 "PARSE_VALHALLA_ROUTE_FAILURE" 1 "DECODE_PROTOBUF_FAILURE" 0 "UNKNOWN_FAILURE" ;
VAL_ 1523 UI_a221_networkErrorCode 500 "SNA" 499 "UNKNOWN_SERVER_ERROR" 403 "SERVICE_UNAVAILABLE_ERROR" 402 "OPERATION_NOT_IMPLEMENTED_ERROR" 401 "INTERNAL_SERVER_ERROR" 399 "PROTOCOL_FAILURE" 302 "PROTOCOL_INVALID_OPERATION_ERROR" 301 "PROTOCOL_UNKNOWN_ERROR" 299 "UNKNOWN_CONTENT_ERROR" 207 "CONTENT_GONE_ERROR" 206 "CONTENT_CONFLICT_ERROR" 205 "CONTENT_RE_SEND_ERROR" 204 "AUTHENTICATION_REQUIRED_ERROR" 203 "CONTENT_NOT_FOUND_ERROR" 202 "CONTENT_OPERATION_NOT_PERMITTED_ERROR" 201 "CONTENT_ACCESS_DENIED" 199 "UNKNOWN_PROXY_ERROR" 105 "PROXY_AUTHENTICATION_REQUIRED_ERROR" 104 "PROXY_TIMEOUT_ERROR" 103 "PROXY_NOT_FOUND_ERROR" 102 "PROXY_CONNECTION_CLOSED_ERROR" 101 "PROXY_CONNECTION_REFUSED_ERROR" 99 "UNKNOWN_NETWORK_ERROR" 11 "INSECURE_REDIRECT_ERROR" 10 "TOO_MANY_REDIRECTS_ERROR" 9 "BACKGROUND_REQUEST_NOT_ALLOWED_ERROR" 8 "NETWORK_SESSION_FAILED_ERROR" 7 "TEMPORARY_NETWORK_FAILURE_ERROR" 6 "SSL_HANDSHAKE_FAILED_ERROR" 5 "OPERATION_CANCELED_ERROR" 4 "TIMEOUT_ERROR" 3 "HOST_NOT_FOUND_ERROR" 2 "REMOTE_HOST_CLOSED_ERROR" 1 "CONNECTION_REFUSED_ERROR" 0 "NO_ERROR" ;
VAL_ 1523 UI_a222_errorCode 11 "TIMED_OUT" 10 "OVER_GEM_OBJECT_MEMORY" 9 "OVER_MEMORY" 8 "LOST_SHARED_MEMORY" 7 "MANUAL" 6 "START_FTRACE_SNIFFING" 5 "CHANGED_TEXT_ACCESSIBILITY_OPTION" 4 "EXIT_TRANSPORT_MODE" 3 "ENTER_TRANSPORT_MODE" 2 "CUSTOMER_MODE_REQUESTED" 1 "LANGUAGE_CHANGED" 0 "OTHER" ;
VAL_ 1523 UI_a223_database 39 "APP_PUSH_NOTIFICATION" 38 "RADIO_SERVER_SETTINGS" 37 "TM_SERVER_SETTINGS" 36 "SPOTIFY_SERVER_SETTINGS" 35 "RELEASE_NOTES_SETTINGS" 34 "QTCAR_VEHICLE_POWER_SETTINGS" 33 "QTCAR_ENERGY_MONITOR_SETTINGS" 32 "ENERGY_CONSUMPTION" 31 "QTCAR_DV_SERVER_SETTINGS" 30 "QTCAR_CONNMAN_SETTINGS" 29 "QTCAR_AUDIOD_SETTINGS" 28 "OWNERS_MANUAL_SETTINGS" 27 "OWNERS_MANUAL_ADAPTER_SETTINGS" 26 "QTCAR_MONITOR_SETTINGS" 25 "QTCAR_MEDIA_SERVER2_SETTINGS" 24 "QTCAR_GPS_MANAGER_SETTINGS" 23 "QTCAR_FIRMWARE_INSTALL_SETTINGS" 22 "QTCAR_ECALL_CLIENT_SETTINGS" 21 "DASHCAM_VIEWER_SETTINGS" 20 "QTCAR_CONN_METRICS_SETTINGS" 19 "ACCOUNT_MANAGER_SETTINGS" 18 "BT_DEVICES" 17 "CALENDAR" 16 "NUANCE_SERVER_SETTINGS" 15 "PHONEBOOK_V2" 14 "QTCAR_BLUETOOTH_SETTINGS" 13 "QTCAR_EVLOG_SERVICE_SETTINGS" 12 "QTCAR_SERVER_SETTINGS" 11 "QTCAR_SETTINGS" 10 "QTCAR_SPEECH_RECOGNIZER_SETTINGS" 9 "QTCAR_VEHICLE_SETTINGS" 8 "VEHICLE_DATAKEYS" 7 "MSG_TRACK" 6 "PLACES_RECOMMENDATION" 5 "VEHICLE_LOG2" 4 "PROFILE_FRECENCY" 3 "PROFILE_PLACES_RECENT" 2 "PLACES_RECENT" 1 "FRECENCY" 0 "UNKNOWN" ;
VAL_ 1523 UI_a229_errorCode 13 "HDMI_FREQ" 12 "LINK_DETECT" 11 "SIGNAL_DETECT" 10 "TMDS_CLOCK" 9 "RX_FIVE_V_DETECT" 8 "INIT_DONE" 7 "CFG_CKSUM" 6 "FPD_THREE_LINK_RDY" 5 "FPD_THREE_TX_STS" 4 "TMDS_VALID" 3 "HDMI_PLL_LOCK" 2 "FREQ_STABLE" 1 "CLOCK_RECV" 0 "DL_MODE" ;
VAL_ 1523 UI_a231_sleepType 4 "Unknown" 3 "ModernStandby" 2 "S2Idle" 1 "S3" 0 "Shallow" ;
VAL_ 1523 UI_a232_processExited 24 "SPOTIFY_SERVER" 23 "QTCAR" 22 "QTCAR_CLUSTER" 21 "QTCAR_VEHICLE" 20 "QTCAR_BLUETOOTH" 19 "QTCAR_CONNMAN" 18 "QTCAR_DVSERVER" 17 "QTCAR_EVLOGSERVICE" 16 "QTCAR_FIRMWAREINSTALL" 15 "QTCAR_MEDIASERVERV2" 14 "QTCAR_RADIOSERVER" 13 "QTCAR_SIMSERVICE" 12 "QTCAR_SPEECHRECOGNIZER" 11 "QTCAR_STARTUP" 10 "QTCAR_TMSERVER" 9 "QTCAR_AUDIOD" 8 "QTCAR_CHECKINTERNET" 7 "QTCAR_ECALLCLIENT" 6 "QTCAR_ENERGYMONITOR" 5 "QTCAR_GPSMANAGER" 4 "QTCAR_MONITOR" 3 "QTCAR_SERVER" 2 "QTCAR_VEHICLEPOWER" 1 "UNKNOWN" ;
VAL_ 1523 UI_a232_processSignal 11 "SEGMENTATION_FAULT" 8 "FLOATING_POINT_EXCEPTION" 7 "BUS_ERROR" 6 "ABORT" 4 "ILLEGAL_INSTRUCTION" 1 "UNKNOWN" ;
VAL_ 1523 UI_a240_ethErrorType 6 "TX_FLOOD" 5 "RX_FLOOD" 4 "TX_OVERRUN" 3 "RX_OVERRUN" 2 "TX_ERROR" 1 "RX_ERROR" 0 "UNKNOWN" ;
VAL_ 1523 UI_a247_displayType 9 "MY_DP_P103" 8 "CT_DP_185" 7 "M3_DP_P882" 6 "SX_HDMI_R94" 5 "M3_HDMI_E2X" 4 "M3_HDMI_P88" 3 "SX_HDMI_8" 2 "SX_HDMI_11" 1 "SX_DP_17" 0 "Unknown" ;
VAL_ 1523 UI_a247_displaySeat 3 "Rear" 2 "Cluster" 1 "Center" 0 "Unknown" ;
VAL_ 1523 UI_a257_ModemRebootReason 4 "HARD_REBOOT_GPIO_FAIL" 3 "HARD_REBOOT_A2B_FAIL" 2 "HARD_REBOOT_FALLBACK" 1 "HARD_REBOOT" 0 "GRACEFUL_REBOOT" ;
VAL_ 1523 UI_a257_ModemRebootEthPresent 1 "NO_ETH" 0 "WITH_ETH" ;
VAL_ 1523 UI_a261_bluetoothStackPanicReaso 46 "SM_INVALID_STATE" 45 "SM_ACL_NOT_IN_PAIRING_LIST" 44 "SM_INVALID_RPA_TYPE" 43 "SM_RANDOM_GENERATION_FAILURE" 42 "SM_PAIRING_SANITY_FAILURE" 41 "SM_MARSHAL_UNMARSHAL_INVALID_STATE" 40 "SDM_CIS_INSTANCE_NOT_FOUND" 39 "SDM_MARSHAL_UNMARSHAL_INVALID_STATE" 38 "RFCOMM_MARSHAL_UNMARSHAL_INVALID_STATE" 37 "L2CAP_MARSHAL_UNMARSHAL_INVALID_STATE" 36 "L2CAP_FLOW_CTRL_INSTANCE_SANITY_FAILED" 35 "L2CAP_CONFIG_BUF_NULL" 34 "L2CAP_MALLOC_FAILED" 33 "L2CAP_MBLK_DATA_LEN_MTU_MISMATCH" 32 "L2CAP_INVALID_CID" 31 "L2CAP_READ_CONFTAB_FAILED" 30 "DM_MULTIPLE_ACL_LIST_FOUND" 29 "DM_MARSHAL_UNMARSHAL_INVALID_STATE" 28 "BLUESTACK_UNEXPECTED_HCI_COMMAND_COMPLETE" 27 "HCISHIM_HCI_SEND_FAILED" 26 "DM_AE_SET_SCAN_PARAM_FAILED" 25 "DM_AE_INVALID_ADV_HANDLE" 24 "DM_CLIENT_ACL_NULL" 23 "DM_ACL_SANITY_FAILED" 22 "INVALID_TIMER_ID" 21 "TRANSPORT_UNRESPONSIVE" 20 "ATT_FIXED_CID_REG_FAILED" 19 "DM_INVALID_HANDLE" 18 "ATT_INVALID_TYPE" 17 "ATT_INVALID_STATE" 16 "SM_L2CAP_HANDLER" 15 "INVALID_ULP_BUFFER_SIZE_RESPONSE" 14 "DM_ACL_LOCKS_EXHAUSED" 13 "RFCOMM_STREAM_MISMATCH" 12 "RFCOMM_L2CAP_REGISTER_FAILED" 11 "MBLK_CREATE_FAILURE" 10 "RFCOMM_INVALID_TIMER_CONTEXT" 9 "RFCOMM_INVALID_TIMER_TYPE" 8 "RFCOMM_TIMER_ALREADY_STARTED" 7 "MBLK_DISCARD_TAIL_ERROR" 6 "MBLK_MSGFRAG_COALESCE_FAILURE" 5 "HEAP_EXHAUSTION" 4 "INVALID_ESCO_TX_INTERVAL" 3 "INVALID_BLUESTACK_PRIMITIVE" 2 "L2CAP_HCI_DATA_CREDITS_INCONSISTENT" 1 "MBLK_MAP_ERROR" 0 "UNKNOWN" ;
VAL_ 1523 UI_a274_hintCardType 10 "FSD_TRIAL" 9 "ACTIVATE_FSD_LANE_KEEP_ASSIST" 8 "ACTIVATE_FSD_DROWSY_DRIVER" 7 "ACTIVATE_FSD_ON_HIGHWAY" 6 "ACTIVATE_FSD_IN_TRAFFIC" 5 "START_FSD_FROM_PARK" 4 "ENABLE_FSD" 3 "END_TO_END_FSD_HIGHWAY_A_PEDAL" 2 "END_TO_END_FSD_HIGHWAY" 1 "ACTIVATE_FSD" 0 "UNKNOWN" ;
VAL_ 1523 UI_a274_hintCardDismissOutcome 4 "CONDITION_DISMISSED" 3 "SWIPED_AWAY" 2 "TIMED_OUT" 1 "SUCCESSFUL" 0 "UNKNOWN" ;
VAL_ 1279 UI_energyConsumptionInfoIndex 21 "21" 20 "20" 19 "19" 18 "18" 17 "17" 16 "16" 15 "15" 14 "14" 13 "13" 12 "12" 11 "11" 10 "10" 9 "9" 8 "8" 7 "7" 6 "6" 5 "5" 4 "4" 3 "3" 2 "2" 1 "1" 0 "0" ;
VAL_ 993 UI_gearSliderInfoIndex 2 "Neutral" 1 "Park" 0 "Slider" ;
VAL_ 563 UI_gearRequest 4 "GEAR_REQUEST_DRIVE" 3 "GEAR_REQUEST_NEUTRAL" 2 "GEAR_REQUEST_REVERSE" 1 "GEAR_REQUEST_PARK" 0 "GEAR_REQUEST_IDLE_SNA" ;
VAL_ 563 UI_autopilotRequest 1 "PRESSED" 0 "IDLE" ;
VAL_ 563 UI_gearStripLocation 1 "RIGHT" 0 "LEFT" ;
VAL_ 986 UI_wifiRegDomain 67 "AZ" 66 "SR" 65 "SM" 64 "MS" 63 "MT" 62 "LV" 61 "LT" 60 "LI" 59 "GI" 58 "CY" 57 "AD" 56 "PT" 55 "MU" 54 "LU" 53 "EE" 52 "BG" 51 "BR" 50 "IN" 49 "IE" 48 "IS" 47 "AE" 46 "TR" 45 "ES" 44 "SI" 43 "SK" 42 "RO" 41 "PR" 40 "PL" 39 "HU" 38 "GR" 37 "FI" 36 "HR" 35 "CZ" 34 "NZ" 33 "MO" 32 "SA" 31 "PH" 30 "CO" 29 "QA" 28 "CL" 27 "MY" 26 "TH" 25 "SG" 24 "JO" 23 "MX" 22 "TW" 21 "KR" 20 "RU" 19 "GB" 18 "IL" 17 "AU" 16 "JP" 15 "HK" 14 "CN" 13 "UK" 12 "SE" 11 "CH" 10 "NO" 9 "DK" 8 "BE" 7 "AT" 6 "NL" 5 "IT" 4 "FR" 3 "DE" 2 "CA" 1 "US" 0 "UNKNOWN" ;
VAL_ 661 UI_systemMonitorIndex 1 "1" 0 "0" ;
VAL_ 139 UI_maxSpeedToReachDestination 65535 "SNA" 65534 "UNREACHABLE" 65533 "MAXVAL" ;
VAL_ 139 UI_remainingWeightedRMSSpeed 65535 "SNA" 65534 "MAXVAL" ;
VAL_ 139 UI_timeToDestination 65535 "SNA" 65534 "MAXVAL" ;
VAL_ 1173 UI_predictedEnergy -32767 "TRIP_TOO_LONG" -32768 "SNA" ;
VAL_ 1173 UI_predictedEnergyLearned -32767 "TRIP_TOO_LONG" -32768 "SNA" ;
VAL_ 1173 UI_hindsightEnergy -32767 "TRIP_TOO_LONG" -32768 "SNA" ;
VAL_ 1173 UI_hindsightEnergyLearned -32767 "TRIP_TOO_LONG" -32768 "SNA" ;
VAL_ 1174 UI_longTermEnergyModelError 127 "MAXVAL" -128 "SNA" ;
VAL_ 1174 UI_longTermRmsSpeedRatio 255 "SNA" 254 "MAXVAL" ;
VAL_ 1174 UI_gradeCorrectedEnergy -32767 "TRIP_TOO_LONG" -32768 "SNA" ;
VAL_ 1174 UI_gradeCorrectedEnergyLearned -32767 "TRIP_TOO_LONG" -32768 "SNA" ;
VAL_ 1175 UI_battPreconditionOnNavTime 65535 "SNA" 65534 "MAXVAL" ;
VAL_ 1175 UI_maxBattPreconditionOnNavTime 65535 "SNA" 65534 "MAXVAL" ;
VAL_ 649 VCLEFT_logging10HzIndex 1 "END" 0 "HVAC_VARS" ;
VAL_ 649 VCLEFT_hvacBlowerRs 255 "SNA" ;
VAL_ 649 VCLEFT_hvacBlowerIPhase0 127 "SNA" ;
VAL_ 649 VCLEFT_hvacBlowerIPhase1 127 "SNA" ;
VAL_ 649 VCLEFT_hvacBlowerIPhase2 127 "SNA" ;
VAL_ 649 VCLEFT_hvacBlower_IO_CBC_Status 1 "RX" 0 "IDLE" ;
VAL_ 649 VCLEFT_hvacBlowerCBCEstState 14 "COUNT" 13 "ONLINE" 12 "MOTOR_IDENTIFIED" 11 "ROTOR_RESISTANCE" 10 "INDUCTANCE_EST" 9 "LOCKROTOR" 8 "RAMPDOWN" 7 "RATEDFLUX" 6 "RATEDFLUX_OL" 5 "IDRATED" 4 "RAMPUP" 3 "RS" 2 "ROVERL" 1 "IDLE" 0 "ERROR" ;
VAL_ 649 VCLEFT_hvacBlowerCBCCtrlState 4 "COUNT" 3 "ONLINE" 2 "OFFLINE" 1 "IDLE" 0 "ERROR" ;
VAL_ 649 VCLEFT_hvacBlowerITerm 127 "SNA" ;
